NS_ :

BS_:

BU_: AWC BAP_Tester BMC_MLBevo BMS_MV BMS_NV DCDC_800V_PAG DCDC_HV DCDC_HV_02 DCDC_IHEV Gateway Gateway_PAG Ladegeraet_2 Ladegeraet_Konzern LE1 LE2 LE_MLBevo Sub_Gateway TME

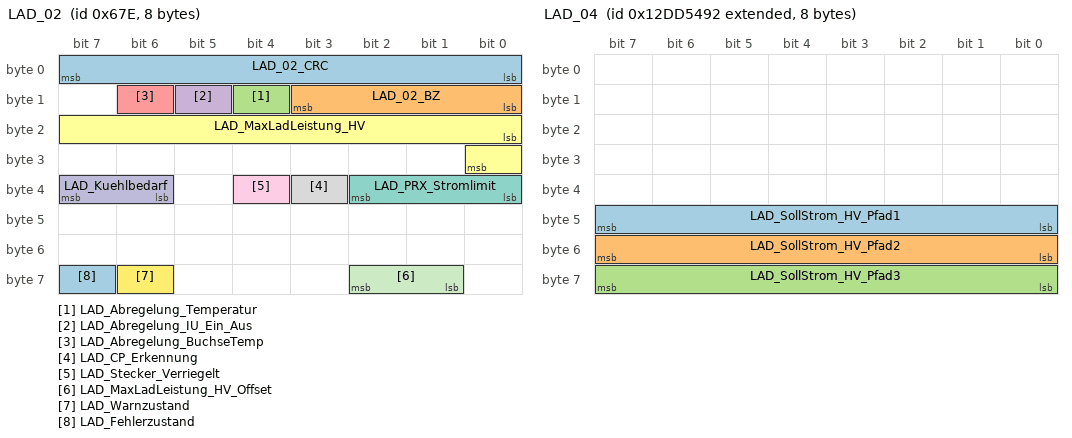
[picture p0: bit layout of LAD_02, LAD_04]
BO_ 1662 LAD_02: 8 Ladegeraet_Konzern
 SG_ LAD_02_CRC : 0|8@1+ (1,0) [0|255] ""  Gateway,Gateway_PAG
 SG_ LAD_02_BZ : 8|4@1+ (1,0) [0|15] ""  Gateway,Gateway_PAG
 SG_ LAD_Abregelung_Temperatur : 12|1@1+ (1.0,0.0) [0.0|1] ""  TME
 SG_ LAD_Abregelung_IU_Ein_Aus : 13|1@1+ (1.0,0.0) [0.0|1] ""  Vector__XXX
 SG_ LAD_Abregelung_BuchseTemp : 14|1@1+ (1.0,0.0) [0.0|1] ""  Vector__XXX
 SG_ LAD_MaxLadLeistung_HV : 16|9@1+ (100,0) [0|50900] "Unit_Watt"  TME
 SG_ LAD_PRX_Stromlimit : 32|3@1+ (1.0,0.0) [0.0|7] ""  Vector__XXX
 SG_ LAD_CP_Erkennung : 35|1@1+ (1.0,0.0) [0.0|1] ""  Vector__XXX
 SG_ LAD_Stecker_Verriegelt : 36|1@1+ (1.0,0.0) [0.0|1] ""  Vector__XXX
 SG_ LAD_Kuehlbedarf : 38|2@1+ (1.0,0.0) [0.0|3] ""  Vector__XXX
 SG_ LAD_MaxLadLeistung_HV_Offset : 57|2@1+ (1.0,0.0) [0.0|3] ""  Vector__XXX
 SG_ LAD_Warnzustand : 62|1@1+ (1.0,0.0) [0.0|1] ""  Vector__XXX
 SG_ LAD_Fehlerzustand : 63|1@1+ (1.0,0.0) [0.0|1] ""  Vector__XXX

BO_ 2463978642 LAD_04: 8 Ladegeraet_Konzern
 SG_ LAD_SollStrom_HV_Pfad1 : 40|8@1+ (0.1,0) [0.0|25.3] "Unit_Amper"  Ladegeraet_2
 SG_ LAD_SollStrom_HV_Pfad2 : 48|8@1+ (0.1,0) [0.0|25.3] "Unit_Amper"  Ladegeraet_2
 SG_ LAD_SollStrom_HV_Pfad3 : 56|8@1+ (0.1,0) [0.0|25.3] "Unit_Amper"  Ladegeraet_2

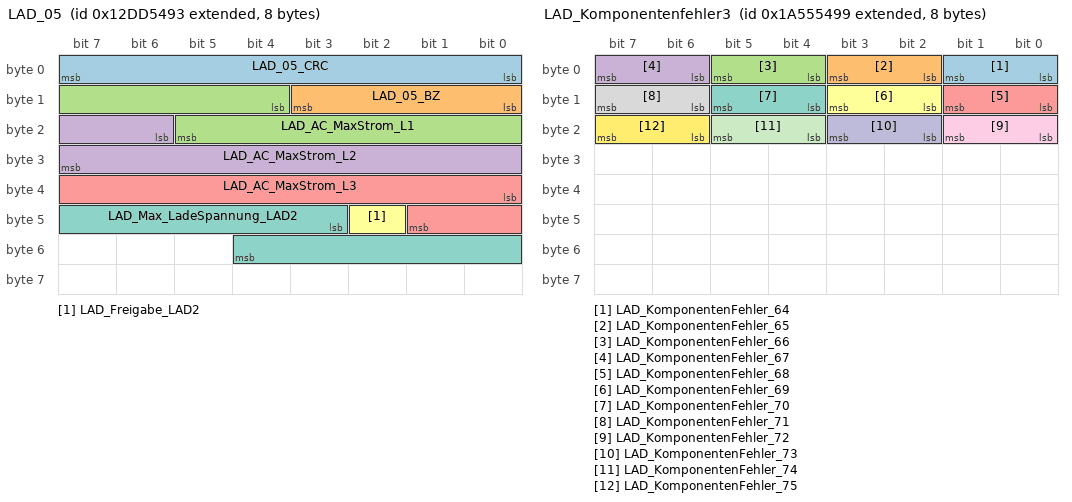
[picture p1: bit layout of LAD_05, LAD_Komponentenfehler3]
BO_ 2463978643 LAD_05: 8 Ladegeraet_Konzern
 SG_ LAD_05_CRC : 0|8@1+ (1,0) [0|255] ""  Ladegeraet_2
 SG_ LAD_05_BZ : 8|4@1+ (1,0) [0|15] ""  Ladegeraet_2
 SG_ LAD_AC_MaxStrom_L1 : 12|10@1+ (0.1,0) [0.0|102.1] "Unit_Amper"  Ladegeraet_2
 SG_ LAD_AC_MaxStrom_L2 : 22|10@1+ (0.1,0) [0.0|102.1] "Unit_Amper"  Ladegeraet_2
 SG_ LAD_AC_MaxStrom_L3 : 32|10@1+ (0.1,0) [0.0|102.1] "Unit_Amper"  Ladegeraet_2
 SG_ LAD_Freigabe_LAD2 : 42|1@1+ (1.0,0.0) [0.0|1] ""  Ladegeraet_2
 SG_ LAD_Max_LadeSpannung_LAD2 : 43|10@1+ (1,0) [0|1021] "Unit_Volt"  Ladegeraet_2

BO_ 2589283663 LAD_06: 8 Ladegeraet_Konzern
 SG_ LAD_PlanAntw_Verlustleistung : 48|12@1+ (50,0) [0|204650] "Unit_Watt"  TME
 SG_ LAD_PlanAntw_Zaehler : 60|4@1+ (1,0) [0|13] "Unit_None"  TME

BO_ 2589283415 LAD_CALID_CVN: 8 Ladegeraet_Konzern
 SG_ LAD_CALID_CVN_MUX M  : 0|2@1+ (1,0) [0|3] "Unit_None"  BMC_MLBevo
 SG_ LAD_CVN_VLD : 7|1@1+ (1.0,0.0) [0.0|1] ""  BMC_MLBevo
 SG_ LAD_CALID_Index_01 m0  : 8|8@1+ (1.0,0.0) [0.0|255] ""  BMC_MLBevo
 SG_ LAD_CALID_Index_05 m1  : 8|8@1+ (1.0,0.0) [0.0|255] ""  BMC_MLBevo
 SG_ LAD_CALID_Index_09 m2  : 8|8@1+ (1.0,0.0) [0.0|255] ""  BMC_MLBevo
 SG_ LAD_CALID_Index_13 m3  : 8|8@1+ (1.0,0.0) [0.0|255] ""  BMC_MLBevo
 SG_ LAD_CALID_Index_02 m0  : 16|8@1+ (1.0,0.0) [0.0|255] ""  BMC_MLBevo
 SG_ LAD_CALID_Index_06 m1  : 16|8@1+ (1.0,0.0) [0.0|255] ""  BMC_MLBevo
 SG_ LAD_CALID_Index_10 m2  : 16|8@1+ (1.0,0.0) [0.0|255] ""  BMC_MLBevo
 SG_ LAD_CALID_Index_14 m3  : 16|8@1+ (1.0,0.0) [0.0|255] ""  BMC_MLBevo
 SG_ LAD_CALID_Index_03 m0  : 24|8@1+ (1.0,0.0) [0.0|255] ""  BMC_MLBevo
 SG_ LAD_CALID_Index_07 m1  : 24|8@1+ (1.0,0.0) [0.0|255] ""  BMC_MLBevo
 SG_ LAD_CALID_Index_11 m2  : 24|8@1+ (1.0,0.0) [0.0|255] ""  BMC_MLBevo
 SG_ LAD_CALID_Index_15 m3  : 24|8@1+ (1.0,0.0) [0.0|255] ""  BMC_MLBevo
 SG_ LAD_CALID_Index_04 m0  : 32|8@1+ (1.0,0.0) [0.0|255] ""  BMC_MLBevo
 SG_ LAD_CALID_Index_08 m1  : 32|8@1+ (1.0,0.0) [0.0|255] ""  BMC_MLBevo
 SG_ LAD_CALID_Index_12 m2  : 32|8@1+ (1.0,0.0) [0.0|255] ""  BMC_MLBevo
 SG_ LAD_CALID_Index_16 m3  : 32|8@1+ (1.0,0.0) [0.0|255] ""  BMC_MLBevo
 SG_ LAD_CVN_Byte_1 m0  : 40|8@1+ (1.0,0.0) [0.0|255] ""  BMC_MLBevo
 SG_ LAD_CVN_Byte_2 m1  : 40|8@1+ (1.0,0.0) [0.0|255] ""  BMC_MLBevo
 SG_ LAD_CVN_Byte_3 m2  : 40|8@1+ (1.0,0.0) [0.0|255] ""  BMC_MLBevo
 SG_ LAD_CVN_Byte_4 m3  : 40|8@1+ (1.0,0.0) [0.0|255] ""  BMC_MLBevo

BO_ 2589283472 LAD_Komponentenfehler: 8 Ladegeraet_Konzern
 SG_ LAD_KomponentenFehler_01 : 0|2@1+ (1.0,0.0) [0.0|3] ""  BMC_MLBevo
 SG_ LAD_KomponentenFehler_02 : 2|2@1+ (1.0,0.0) [0.0|3] ""  BMC_MLBevo
 SG_ LAD_KomponentenFehler_03 : 4|2@1+ (1.0,0.0) [0.0|3] ""  BMC_MLBevo
 SG_ LAD_KomponentenFehler_04 : 6|2@1+ (1.0,0.0) [0.0|3] ""  BMC_MLBevo
 SG_ LAD_KomponentenFehler_05 : 8|2@1+ (1.0,0.0) [0.0|3] ""  BMC_MLBevo
 SG_ LAD_KomponentenFehler_06 : 10|2@1+ (1.0,0.0) [0.0|3] ""  BMC_MLBevo
 SG_ LAD_KomponentenFehler_07 : 12|2@1+ (1.0,0.0) [0.0|3] ""  BMC_MLBevo
 SG_ LAD_KomponentenFehler_08 : 14|2@1+ (1.0,0.0) [0.0|3] ""  BMC_MLBevo
 SG_ LAD_KomponentenFehler_09 : 16|2@1+ (1.0,0.0) [0.0|3] ""  BMC_MLBevo
 SG_ LAD_KomponentenFehler_10 : 18|2@1+ (1.0,0.0) [0.0|3] ""  BMC_MLBevo
 SG_ LAD_KomponentenFehler_11 : 20|2@1+ (1.0,0.0) [0.0|3] ""  BMC_MLBevo
 SG_ LAD_KomponentenFehler_12 : 22|2@1+ (1.0,0.0) [0.0|3] ""  BMC_MLBevo
 SG_ LAD_KomponentenFehler_13 : 24|2@1+ (1.0,0.0) [0.0|3] ""  BMC_MLBevo
 SG_ LAD_KomponentenFehler_14 : 26|2@1+ (1.0,0.0) [0.0|3] ""  BMC_MLBevo
 SG_ LAD_KomponentenFehler_15 : 28|2@1+ (1.0,0.0) [0.0|3] ""  BMC_MLBevo
 SG_ LAD_KomponentenFehler_16 : 30|2@1+ (1.0,0.0) [0.0|3] ""  BMC_MLBevo
 SG_ LAD_KomponentenFehler_17 : 32|2@1+ (1.0,0.0) [0.0|3] ""  BMC_MLBevo
 SG_ LAD_KomponentenFehler_18 : 34|2@1+ (1.0,0.0) [0.0|3] ""  BMC_MLBevo
 SG_ LAD_KomponentenFehler_19 : 36|2@1+ (1.0,0.0) [0.0|3] ""  BMC_MLBevo
 SG_ LAD_KomponentenFehler_20 : 38|2@1+ (1.0,0.0) [0.0|3] ""  BMC_MLBevo
 SG_ LAD_KomponentenFehler_21 : 40|2@1+ (1.0,0.0) [0.0|3] ""  BMC_MLBevo
 SG_ LAD_KomponentenFehler_22 : 42|2@1+ (1.0,0.0) [0.0|3] ""  BMC_MLBevo
 SG_ LAD_KomponentenFehler_23 : 44|2@1+ (1.0,0.0) [0.0|3] ""  BMC_MLBevo
 SG_ LAD_KomponentenFehler_24 : 46|2@1+ (1.0,0.0) [0.0|3] ""  BMC_MLBevo
 SG_ LAD_KomponentenFehler_25 : 48|2@1+ (1.0,0.0) [0.0|3] ""  BMC_MLBevo
 SG_ LAD_KomponentenFehler_26 : 50|2@1+ (1.0,0.0) [0.0|3] ""  BMC_MLBevo
 SG_ LAD_KomponentenFehler_27 : 52|2@1+ (1.0,0.0) [0.0|3] ""  BMC_MLBevo
 SG_ LAD_KomponentenFehler_28 : 54|2@1+ (1.0,0.0) [0.0|3] ""  BMC_MLBevo
 SG_ LAD_KomponentenFehler_29 : 56|2@1+ (1.0,0.0) [0.0|3] ""  BMC_MLBevo
 SG_ LAD_KomponentenFehler_30 : 58|2@1+ (1.0,0.0) [0.0|3] ""  BMC_MLBevo
 SG_ LAD_KomponentenFehler_31 : 60|2@1+ (1.0,0.0) [0.0|3] ""  BMC_MLBevo
 SG_ LAD_KomponentenFehler_32 : 62|2@1+ (1.0,0.0) [0.0|3] ""  BMC_MLBevo

BO_ 2589283473 LAD_Komponentenfehler2: 8 Ladegeraet_Konzern
 SG_ LAD_KomponentenFehler_33 : 0|2@1+ (1.0,0.0) [0.0|3] ""  BMC_MLBevo
 SG_ LAD_KomponentenFehler_34 : 2|2@1+ (1.0,0.0) [0.0|3] ""  BMC_MLBevo
 SG_ LAD_KomponentenFehler_35 : 4|2@1+ (1.0,0.0) [0.0|3] ""  BMC_MLBevo
 SG_ LAD_KomponentenFehler_36 : 6|2@1+ (1.0,0.0) [0.0|3] ""  BMC_MLBevo
 SG_ LAD_KomponentenFehler_37 : 8|2@1+ (1.0,0.0) [0.0|3] ""  BMC_MLBevo
 SG_ LAD_KomponentenFehler_38 : 10|2@1+ (1.0,0.0) [0.0|3] ""  BMC_MLBevo
 SG_ LAD_KomponentenFehler_39 : 12|2@1+ (1.0,0.0) [0.0|3] ""  BMC_MLBevo
 SG_ LAD_KomponentenFehler_40 : 14|2@1+ (1.0,0.0) [0.0|3] ""  BMC_MLBevo
 SG_ LAD_KomponentenFehler_41 : 16|2@1+ (1.0,0.0) [0.0|3] ""  BMC_MLBevo
 SG_ LAD_KomponentenFehler_42 : 18|2@1+ (1.0,0.0) [0.0|3] ""  BMC_MLBevo
 SG_ LAD_KomponentenFehler_43 : 20|2@1+ (1.0,0.0) [0.0|3] ""  BMC_MLBevo
 SG_ LAD_KomponentenFehler_44 : 22|2@1+ (1.0,0.0) [0.0|3] ""  BMC_MLBevo
 SG_ LAD_KomponentenFehler_45 : 24|2@1+ (1.0,0.0) [0.0|3] ""  BMC_MLBevo
 SG_ LAD_KomponentenFehler_46 : 26|2@1+ (1.0,0.0) [0.0|3] ""  BMC_MLBevo
 SG_ LAD_KomponentenFehler_47 : 28|2@1+ (1.0,0.0) [0.0|3] ""  BMC_MLBevo
 SG_ LAD_KomponentenFehler_48 : 30|2@1+ (1.0,0.0) [0.0|3] ""  BMC_MLBevo
 SG_ LAD_KomponentenFehler_49 : 32|2@1+ (1.0,0.0) [0.0|3] ""  BMC_MLBevo
 SG_ LAD_KomponentenFehler_50 : 34|2@1+ (1.0,0.0) [0.0|3] ""  BMC_MLBevo
 SG_ LAD_KomponentenFehler_51 : 36|2@1+ (1.0,0.0) [0.0|3] ""  BMC_MLBevo
 SG_ LAD_KomponentenFehler_52 : 38|2@1+ (1.0,0.0) [0.0|3] ""  BMC_MLBevo
 SG_ LAD_KomponentenFehler_53 : 40|2@1+ (1.0,0.0) [0.0|3] ""  BMC_MLBevo
 SG_ LAD_KomponentenFehler_54 : 42|2@1+ (1.0,0.0) [0.0|3] ""  BMC_MLBevo
 SG_ LAD_KomponentenFehler_55 : 44|2@1+ (1.0,0.0) [0.0|3] ""  BMC_MLBevo
 SG_ LAD_KomponentenFehler_56 : 46|2@1+ (1.0,0.0) [0.0|3] ""  BMC_MLBevo
 SG_ LAD_KomponentenFehler_57 : 48|2@1+ (1.0,0.0) [0.0|3] ""  BMC_MLBevo
 SG_ LAD_KomponentenFehler_58 : 50|2@1+ (1.0,0.0) [0.0|3] ""  BMC_MLBevo
 SG_ LAD_KomponentenFehler_59 : 52|2@1+ (1.0,0.0) [0.0|3] ""  BMC_MLBevo
 SG_ LAD_KomponentenFehler_60 : 54|2@1+ (1.0,0.0) [0.0|3] ""  BMC_MLBevo
 SG_ LAD_KomponentenFehler_61 : 56|2@1+ (1.0,0.0) [0.0|3] ""  BMC_MLBevo
 SG_ LAD_KomponentenFehler_62 : 58|2@1+ (1.0,0.0) [0.0|3] ""  BMC_MLBevo
 SG_ LAD_KomponentenFehler_63 : 60|2@1+ (1.0,0.0) [0.0|3] ""  BMC_MLBevo
 SG_ LAD_Komponentenfehler_VLD : 63|1@1+ (1.0,0.0) [0.0|1] ""  BMC_MLBevo

BO_ 2589283481 LAD_Komponentenfehler3: 8 Ladegeraet_Konzern
 SG_ LAD_KomponentenFehler_64 : 0|2@1+ (1.0,0.0) [0.0|3] ""  BMC_MLBevo
 SG_ LAD_KomponentenFehler_65 : 2|2@1+ (1.0,0.0) [0.0|3] ""  BMC_MLBevo
 SG_ LAD_KomponentenFehler_66 : 4|2@1+ (1.0,0.0) [0.0|3] ""  BMC_MLBevo
 SG_ LAD_KomponentenFehler_67 : 6|2@1+ (1.0,0.0) [0.0|3] ""  BMC_MLBevo
 SG_ LAD_KomponentenFehler_68 : 8|2@1+ (1.0,0.0) [0.0|3] ""  BMC_MLBevo
 SG_ LAD_KomponentenFehler_69 : 10|2@1+ (1.0,0.0) [0.0|3] ""  BMC_MLBevo
 SG_ LAD_KomponentenFehler_70 : 12|2@1+ (1.0,0.0) [0.0|3] ""  BMC_MLBevo
 SG_ LAD_KomponentenFehler_71 : 14|2@1+ (1.0,0.0) [0.0|3] ""  BMC_MLBevo
 SG_ LAD_KomponentenFehler_72 : 16|2@1+ (1.0,0.0) [0.0|3] ""  BMC_MLBevo
 SG_ LAD_KomponentenFehler_73 : 18|2@1+ (1.0,0.0) [0.0|3] ""  BMC_MLBevo
 SG_ LAD_KomponentenFehler_74 : 20|2@1+ (1.0,0.0) [0.0|3] ""  BMC_MLBevo
 SG_ LAD_KomponentenFehler_75 : 22|2@1+ (1.0,0.0) [0.0|3] ""  BMC_MLBevo

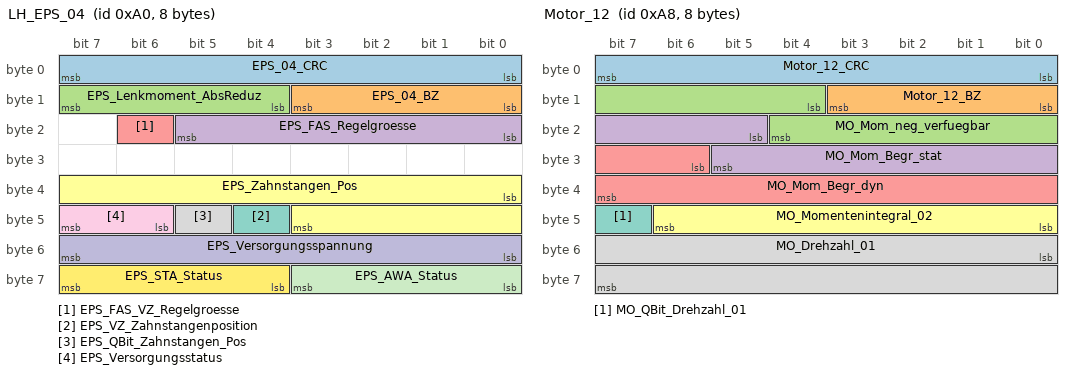
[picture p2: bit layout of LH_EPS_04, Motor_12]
BO_ 160 LH_EPS_04: 8 Gateway
 SG_ EPS_04_CRC : 0|8@1+ (1,0) [0|255] ""  Vector__XXX
 SG_ EPS_04_BZ : 8|4@1+ (1,0) [0|15] ""  Vector__XXX
 SG_ EPS_Lenkmoment_AbsReduz : 12|4@1+ (0.62,0.61) [0.61|8.05] "Unit_NewtoMeter"  Vector__XXX
 SG_ EPS_FAS_Regelgroesse : 16|6@1+ (2,0) [0|100] "Unit_PerCent"  Vector__XXX
 SG_ EPS_FAS_VZ_Regelgroesse : 22|1@1+ (1.0,0.0) [0.0|1] ""  Vector__XXX
 SG_ EPS_Zahnstangen_Pos : 32|12@1+ (0.02,0) [0.00|81.86] "Unit_MilliMeter"  AWC
 SG_ EPS_VZ_Zahnstangenposition : 44|1@1+ (1.0,0.0) [0.0|1] ""  AWC
 SG_ EPS_QBit_Zahnstangen_Pos : 45|1@1+ (1.0,0.0) [0.0|1] ""  AWC
 SG_ EPS_Versorgungsstatus : 46|2@1+ (1.0,0.0) [0.0|3] ""  Vector__XXX
 SG_ EPS_Versorgungsspannung : 48|8@1+ (0.05,5.05) [5.05|17.70] "Unit_Volt"  Vector__XXX
 SG_ EPS_AWA_Status : 56|4@1+ (1.0,0.0) [0.0|15] ""  Vector__XXX
 SG_ EPS_STA_Status : 60|4@1+ (1.0,0.0) [0.0|15] ""  Vector__XXX

BO_ 1600 Motor_07: 8 Gateway
 SG_ MO_QBit_Ansaugluft_Temp : 0|1@1+ (1.0,0.0) [0.0|1] ""  Vector__XXX
 SG_ MO_QBit_Oel_Temp : 1|1@1+ (1.0,0.0) [0.0|1] ""  Vector__XXX
 SG_ MO_QBit_Kuehlmittel_Temp : 2|1@1+ (1.0,0.0) [0.0|1] ""  Vector__XXX
 SG_ MO_KL15_Abschaltempfehlung : 3|1@1+ (1.0,0.0) [0.0|1] ""  Vector__XXX
 SG_ MO_HYB_Fehler_HV_Netz : 4|1@1+ (1.0,0.0) [0.0|1] ""  Vector__XXX
 SG_ MO_aktives_Getriebeheizen : 5|1@1+ (1.0,0.0) [0.0|1] ""  Vector__XXX
 SG_ MO_Absperrventil_oeffnen : 6|2@1+ (1.0,0.0) [0.0|3] ""  TME
 SG_ MO_Ansaugluft_Temp : 8|8@1+ (0.75,-48) [-48.00|141.75] "Unit_DegreCelsi"  TME
 SG_ MO_Oel_Temp : 16|8@1+ (1,-60) [-60|192] "Unit_DegreCelsi"  TME
 SG_ MO_Kuehlmittel_Temp : 24|8@1+ (0.75,-48) [-48.00|141.75] "Unit_DegreCelsi"  TME
 SG_ MO_Hoeheninfo : 32|8@1+ (0.00781,0) [0.00000|1.98374] ""  TME
 SG_ MO_Kennfeldk : 40|1@1+ (1.0,0.0) [0.0|1] ""  TME
 SG_ MO_Versionsinfo_02 : 41|5@1+ (1.0,0.0) [0.0|31] ""  Vector__XXX
 SG_ MO_QBit_Hoeheninfo : 46|1@1+ (1.0,0.0) [0.0|1] ""  Vector__XXX
 SG_ MO_Getriebe_kuehlen : 47|1@1+ (1.0,0.0) [0.0|1] ""  Vector__XXX
 SG_ MO_Mom_Traegheit_02 : 48|5@1+ (0.01,0) [0.00|0.31] "Unit_KiloGramMeterSquar"  Vector__XXX
 SG_ MO_Heizungspumpenansteuerung : 53|4@1+ (10,0) [0|100] "Unit_PerCent"  TME
 SG_ MO_SpannungsAnf : 57|1@1+ (1.0,0.0) [0.0|1] ""  Vector__XXX
 SG_ MO_Nachlaufzeit_Heizungspumpe : 58|6@1+ (15,0) [0|945] "Unit_Secon"  TME

BO_ 1607 Motor_09: 8 Gateway
 SG_ MO_ITM_Kuehlmittel_Temp : 0|8@1+ (0.75,-48) [-45.75|143.25] "Unit_DegreCelsi"  TME
 SG_ MO_E85_Sensor : 8|4@1+ (10,0) [0|100] "Unit_PerCent"  Vector__XXX
 SG_ SCR_Anz_Motorstarts : 12|4@1+ (1.0,0.0) [0.0|15] ""  Vector__XXX
 SG_ SCR_Reichweite : 16|15@1+ (1,0) [0|32766] "Unit_KiloMeter"  Vector__XXX
 SG_ MO_Ethanol_Spuelhinweis : 31|1@1+ (1.0,0.0) [0.0|1] ""  Vector__XXX
 SG_ SCR_Warnstufe_1 : 32|1@1+ (1.0,0.0) [0.0|1] ""  Vector__XXX
 SG_ SCR_Warnstufe_2 : 33|1@1+ (1.0,0.0) [0.0|1] ""  Vector__XXX
 SG_ SCR_Text : 34|3@1+ (1.0,0.0) [0.0|7] ""  Vector__XXX
 SG_ SCR_Akustik : 37|2@1+ (1.0,0.0) [0.0|3] ""  Vector__XXX
 SG_ SCR_verbaut : 39|1@1+ (1.0,0.0) [0.0|1] ""  Vector__XXX
 SG_ MO_Kraftstofffilter_Wasser : 40|1@1+ (1.0,0.0) [0.0|1] ""  Vector__XXX
 SG_ SCR_Systemfehler : 41|1@1+ (1.0,0.0) [0.0|1] ""  Vector__XXX
 SG_ SCR_Inducement_Strategie : 42|2@1+ (1.0,0.0) [0.0|3] ""  Vector__XXX
 SG_ MO_CO2_Faktor : 44|12@1+ (1,0) [1|4094] "Unit_GramPerLiter"  Vector__XXX
 SG_ MO_MKB_MUX M  : 56|2@1+ (1.0,0.0) [0.0|3] ""  Vector__XXX
 SG_ MO_MKB_01 m0  : 59|5@1+ (1.0,0.0) [0.0|31] ""  Vector__XXX
 SG_ MO_MKB_02 m1  : 59|5@1+ (1.0,0.0) [0.0|31] ""  Vector__XXX
 SG_ MO_MKB_03 m2  : 59|5@1+ (1.0,0.0) [0.0|31] ""  Vector__XXX
 SG_ MO_MKB_04 m3  : 59|5@1+ (1.0,0.0) [0.0|31] ""  Vector__XXX

BO_ 168 Motor_12: 8 Gateway
 SG_ Motor_12_CRC : 0|8@1+ (1,0) [0|255] ""  Vector__XXX
 SG_ Motor_12_BZ : 8|4@1+ (1,0) [0|15] ""  Vector__XXX
 SG_ MO_Mom_neg_verfuegbar : 12|9@1+ (1,-509) [-509|0] ""  Vector__XXX
 SG_ MO_Mom_Begr_stat : 21|9@1+ (1,0) [0|509] ""  Vector__XXX
 SG_ MO_Mom_Begr_dyn : 30|10@1+ (1,-509) [-509|509] ""  Vector__XXX
 SG_ MO_Momentenintegral_02 : 40|7@1+ (1,0) [0|100] "Unit_PerCent"  Vector__XXX
 SG_ MO_QBit_Drehzahl_01 : 47|1@1+ (1.0,0.0) [0.0|1] ""  AWC
 SG_ MO_Drehzahl_01 : 48|16@1+ (0.25,0) [0.00|16383.00] "Unit_MinutInver"  AWC,BMC_MLBevo,DCDC_800V_PAG,DCDC_HV,Ladegeraet_2,Ladegeraet_Konzern,TME

BO_ 958 Motor_14: 8 Gateway
 SG_ Motor_14_CRC : 0|8@1+ (1,0) [0|255] ""  Vector__XXX
 SG_ Motor_14_BZ : 8|4@1+ (1,0) [0|15] ""  Vector__XXX
 SG_ MO_StartStopp_Status : 12|2@1+ (1.0,0.0) [0.0|3] ""  TME
 SG_ MO_StartStopp_Wiederstart : 14|1@1+ (1.0,0.0) [0.0|1] ""  BMS_NV,TME
 SG_ MO_StartStopp_Motorstopp : 15|1@1+ (1.0,0.0) [0.0|1] ""  BMS_NV,TME
 SG_ MO_Freig_Reku : 16|2@1+ (1.0,0.0) [0.0|3] ""  Vector__XXX
 SG_ MO_Kl_75 : 18|1@1+ (1.0,0.0) [0.0|1] ""  TME
 SG_ MO_Kl_50 : 19|1@1+ (1.0,0.0) [0.0|1] ""  DCDC_IHEV,Ladegeraet_Konzern
 SG_ MO_Gangposition : 20|4@1+ (1.0,0.0) [0.0|15] ""  TME
 SG_ MO_StartStopp_Fahrerwunsch : 24|2@1+ (1.0,0.0) [0.0|3] ""  TME
 SG_ MO_HYB_Fahrbereitschaft : 26|1@1+ (1.0,0.0) [0.0|1] ""  AWC,BMS_NV,Ladegeraet_Konzern,TME
 SG_ MO_Ext_E_Fahrt_aktiv : 27|1@1+ (1.0,0.0) [0.0|1] ""  TME
 SG_ MO_Fahrer_bremst : 28|1@1+ (1.0,0.0) [0.0|1] ""  Vector__XXX
 SG_ MO_QBit_Fahrer_bremst : 29|1@1+ (1.0,0.0) [0.0|1] ""  Vector__XXX
 SG_ MO_BLS : 30|1@1+ (1.0,0.0) [0.0|1] ""  Vector__XXX
 SG_ MO_Konsistenz_Bremsped : 31|1@1+ (1.0,0.0) [0.0|1] ""  Vector__XXX
 SG_ MO_KomFehler_ESP : 32|1@1+ (1.0,0.0) [0.0|1] ""  Vector__XXX
 SG_ MO_Klima_Eingr : 33|2@1+ (1.0,0.0) [0.0|3] ""  TME
 SG_ MO_Aussp_Anlass : 35|1@1+ (1.0,0.0) [0.0|1] ""  Vector__XXX
 SG_ MO_Freig_Anlass : 36|1@1+ (1.0,0.0) [0.0|1] ""  Vector__XXX
 SG_ MO_Kuppl_schalter : 37|1@1+ (1.0,0.0) [0.0|1] ""  Vector__XXX
 SG_ MO_Interlock : 38|1@1+ (1.0,0.0) [0.0|1] ""  Vector__XXX
 SG_ MO_Motor_laeuft : 39|1@1+ (1.0,0.0) [0.0|1] ""  TME
 SG_ MO_Kickdown : 40|1@1+ (1.0,0.0) [0.0|1] ""  TME
 SG_ MO_QBit_KL_75 : 41|1@1+ (1.0,0.0) [0.0|1] ""  Vector__XXX
 SG_ MO_EKlKomLeiRed : 42|2@1+ (1.0,0.0) [0.0|3] ""  Vector__XXX
 SG_ MO_Handshake_STH : 44|1@1+ (1.0,0.0) [0.0|1] ""  Vector__XXX
 SG_ MO_BKV_Unterdruckwarnung : 45|1@1+ (1.0,0.0) [0.0|1] ""  Vector__XXX
 SG_ MO_Freigabe_Segeln : 46|1@1+ (1.0,0.0) [0.0|1] ""  Vector__XXX
 SG_ MO_PTC_Status : 47|3@1+ (1.0,0.0) [0.0|7] ""  Vector__XXX
 SG_ MO_QBit_Gangposition : 50|1@1+ (1.0,0.0) [0.0|1] ""  Vector__XXX
 SG_ MO_Signalquelle_Gangposition : 51|1@1+ (1.0,0.0) [0.0|1] ""  Vector__XXX
 SG_ MO_Remotestart_Betrieb : 52|1@1+ (1.0,0.0) [0.0|1] ""  Vector__XXX
 SG_ MO_Remotestart_moeglich : 53|1@1+ (1.0,0.0) [0.0|1] ""  Vector__XXX
 SG_ MO_FMAus_aktiv : 55|1@1+ (1.0,0.0) [0.0|1] ""  BMS_NV
 SG_ MO_FMAus_Startvariante : 56|2@1+ (1.0,0.0) [0.0|3] ""  Vector__XXX
 SG_ MO_BMS_NV_Anf_stuetzen : 58|1@1+ (1.0,0.0) [0.0|1] ""  Vector__XXX
 SG_ MO_Zylinderabschaltung : 59|2@1+ (1.0,0.0) [0.0|3] ""  Vector__XXX
 SG_ MO_HYB_VM_aktiv : 61|1@1+ (1.0,0.0) [0.0|1] ""  Vector__XXX
 SG_ MO_StartVorauss_erfuellt : 62|2@1+ (1.0,0.0) [0.0|3] ""  AWC,Ladegeraet_Konzern

BO_ 812 Motor_17: 8 Gateway
 SG_ MO_Sperrung_FahrPr_BZS : 0|8@1+ (1.0,0.0) [0.0|255] ""  Vector__XXX
 SG_ MO_Rampenzeit_Generator_Anf : 8|4@1+ (1.0,0.0) [0.0|15] ""  Vector__XXX
 SG_ MO_Prio_MAX_Wunschdrehzahl : 12|1@1+ (1.0,0.0) [0.0|1] ""  Vector__XXX
 SG_ MO_Prio_MIN_Wunschdrehzahl : 13|1@1+ (1.0,0.0) [0.0|1] ""  Vector__XXX
 SG_ MO_Luftpfad_aktiv : 14|1@1+ (1.0,0.0) [0.0|1] ""  Vector__XXX
 SG_ MO_v_Begrenz_Aktivierbar : 15|1@1+ (1.0,0.0) [0.0|1] ""  Vector__XXX
 SG_ MO_Drehzahlbeeinflussung : 16|8@1+ (0.39,0) [0.00|99.45] "Unit_PerCent"  Vector__XXX
 SG_ MO_MIN_Wunschdrehzahl : 24|8@1+ (25,0) [0|6350] "Unit_MinutInver"  Vector__XXX
 SG_ MO_MAX_Wunschdrehzahl : 32|9@1+ (25,0) [0|12750] "Unit_MinutInver"  Vector__XXX
 SG_ MO_Charisma_FahrPr : 41|4@1+ (1.0,0.0) [0.0|15] ""  TME
 SG_ MO_Charisma_Status : 45|2@1+ (1.0,0.0) [0.0|3] ""  Vector__XXX
 SG_ MO_StSt_Charisma_FahrPr : 47|4@1+ (1.0,0.0) [0.0|15] ""  Vector__XXX
 SG_ MO_StSt_Charisma_Status : 51|2@1+ (1.0,0.0) [0.0|3] ""  Vector__XXX
 SG_ MO_BZS_Charisma_FahrPr : 53|4@1+ (1.0,0.0) [0.0|15] ""  TME
 SG_ MO_BZS_Charisma_Status : 57|2@1+ (1.0,0.0) [0.0|3] ""  Vector__XXX
 SG_ MO_NGS_Position : 59|1@1+ (1.0,0.0) [0.0|1] ""  Vector__XXX
 SG_ MO_NGS_Status : 60|2@1+ (1.0,0.0) [0.0|3] ""  Vector__XXX
 SG_ MO_v_Begrenzung_Niveau : 62|2@1+ (1.0,0.0) [0.0|3] ""  Vector__XXX

BO_ 1648 Motor_18: 8 Gateway
 SG_ MO_max_Ladedruck : 0|6@1+ (0.1,0) [0.0|6.3] "Unit_Bar"  Vector__XXX
 SG_ MO_ANC_Kennfeld_Anf : 6|2@1+ (1.0,0.0) [0.0|3] ""  Vector__XXX
 SG_ MO_Bremslicht_Reku : 8|1@1+ (1.0,0.0) [0.0|1] ""  Vector__XXX
 SG_ MO_StartStopp_PopUp : 9|2@1+ (1.0,0.0) [0.0|3] ""  Vector__XXX
 SG_ MO1_Sperr_Info_WFS : 11|1@1+ (1.0,0.0) [0.0|1] ""  Vector__XXX
 SG_ MO1_Freigabe_Info_WFS : 12|1@1+ (1.0,0.0) [0.0|1] ""  Vector__XXX
 SG_ MO_EPCL : 13|3@1+ (1.0,0.0) [0.0|7] ""  Vector__XXX
 SG_ MO_Zylabsch_Texte_02 : 16|4@1+ (1.0,0.0) [0.0|15] ""  Vector__XXX
 SG_ MO_Fahrzeugtyp : 20|3@1+ (1.0,0.0) [0.0|7] ""  BMS_NV
 SG_ MO_NMAX_Schaltanzeige : 23|9@1+ (25,0) [0|12775] "Unit_MinutInver"  Vector__XXX
 SG_ MO_Abstellzeit : 32|8@1+ (8,0) [0|2024] "Unit_Minut"  BMS_MV,BMS_NV,TME
 SG_ MO_Abstellzeit_Status : 40|2@1+ (1.0,0.0) [0.0|3] ""  BMS_MV,BMS_NV,TME
 SG_ MO1_Freigabe_Verfallsinfo_WFS : 42|1@1+ (1.0,0.0) [0.0|1] ""  Vector__XXX
 SG_ MO_Hybrid_StartStopp_LED : 43|2@1+ (1.0,0.0) [0.0|3] ""  Vector__XXX
 SG_ MO_Fehler_Zylabsch : 45|2@1+ (1.0,0.0) [0.0|3] ""  Vector__XXX
 SG_ MO_Anzahl_Abgesch_Zyl : 47|3@1+ (1.0,0.0) [0.0|7] ""  Vector__XXX
 SG_ MO_Zylabsch_Texte : 50|2@1+ (1.0,0.0) [0.0|3] ""  Vector__XXX
 SG_ MO_Ethanol_BS_Texte : 52|3@1+ (1.0,0.0) [0.0|7] ""  Vector__XXX
 SG_ MO_Drehzahl_Warnung : 55|1@1+ (1.0,0.0) [0.0|1] ""  Vector__XXX
 SG_ MO_obere_Drehzahlgrenze : 56|8@1+ (50,0) [50|12750] "Unit_MinutInver"  Vector__XXX

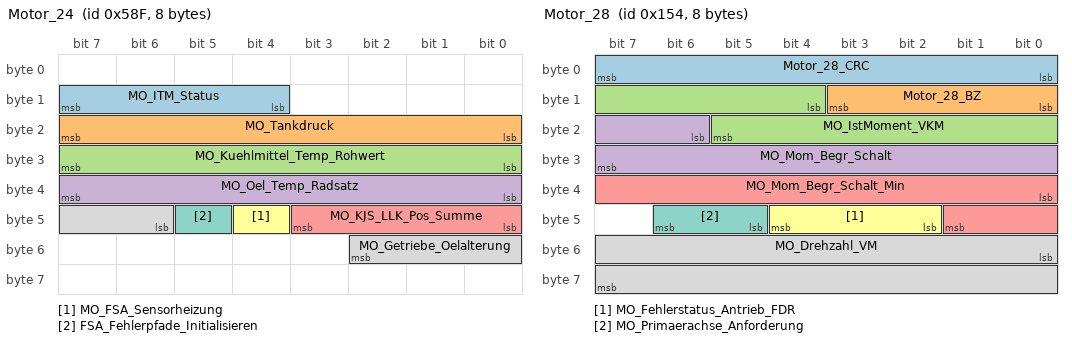
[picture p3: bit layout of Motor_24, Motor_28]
BO_ 1423 Motor_24: 8 Gateway
 SG_ MO_ITM_Status : 12|4@1+ (1.0,0.0) [0.0|15] ""  TME
 SG_ MO_Tankdruck : 16|8@1+ (2,-250) [-250|256] "Unit_MilliBar"  Vector__XXX
 SG_ MO_Kuehlmittel_Temp_Rohwert : 24|8@1+ (0.75,-48) [-48.00|141.75] "Unit_DegreCelsi"  TME
 SG_ MO_Oel_Temp_Radsatz : 32|8@1+ (1,-60) [-60|193] "Unit_DegreCelsi"  Vector__XXX
 SG_ MO_KJS_LLK_Pos_Summe : 40|4@1+ (10,0) [0|100] "Unit_PerCent"  Vector__XXX
 SG_ MO_FSA_Sensorheizung : 44|1@1+ (1.0,0.0) [0.0|1] ""  Vector__XXX
 SG_ FSA_Fehlerpfade_Initialisieren : 45|1@1+ (1.0,0.0) [0.0|1] ""  Vector__XXX
 SG_ MO_Getriebe_Oelalterung : 46|5@1+ (5,0) [0|100] "Unit_PerCent"  Vector__XXX

BO_ 967 Motor_26: 8 Gateway
 SG_ MO_Kuehlerluefter_MUX M  : 0|1@1+ (1.0,0.0) [0.0|1] ""  TME
 SG_ MO_Kuehlerluefter_1 m0  : 1|7@1+ (1,0) [0|100] "Unit_PerCent"  TME
 SG_ MO_Kuehlerluefter_2 m1  : 1|7@1+ (1,0) [0|100] "Unit_PerCent"  TME
 SG_ MO_EFLEX_Lampe : 8|2@1+ (1.0,0.0) [0.0|3] ""  Vector__XXX
 SG_ MO_KJS_nicht_bereit : 10|1@1+ (1.0,0.0) [0.0|1] ""  Vector__XXX
 SG_ MO_ITM_Warnung_Pumpe : 11|1@1+ (1.0,0.0) [0.0|1] ""  Vector__XXX
 SG_ WIV_Anzeige_aktiv : 12|1@1+ (1.0,0.0) [0.0|1] ""  Vector__XXX
 SG_ WIV_Oelmin_Warn : 13|1@1+ (1.0,0.0) [0.0|1] ""  Vector__XXX
 SG_ WIV_Sensorfehler : 14|1@1+ (1.0,0.0) [0.0|1] ""  Vector__XXX
 SG_ WIV_Schieflage : 15|1@1+ (1.0,0.0) [0.0|1] ""  Vector__XXX
 SG_ WIV_Oelstand : 16|4@1+ (12.5,0) [0.0|100.0] "Unit_PerCent"  Vector__XXX
 SG_ MO_Zustand_HWP : 20|2@1+ (1.0,0.0) [0.0|3] ""  TME
 SG_ OLEV_Systemstoerung : 22|1@1+ (1.0,0.0) [0.0|1] ""  Vector__XXX
 SG_ MO_Oelwarnung_max : 23|1@1+ (1.0,0.0) [0.0|1] ""  Vector__XXX
 SG_ WIV_Oelsystem_aktiv : 24|1@1+ (1.0,0.0) [0.0|1] ""  Vector__XXX
 SG_ WIV_nicht_betriebswarm : 25|1@1+ (1.0,0.0) [0.0|1] ""  Vector__XXX
 SG_ WIV_Ueberfuell_Warn : 26|1@1+ (1.0,0.0) [0.0|1] ""  Vector__XXX
 SG_ WIV_laufender_Motor : 27|1@1+ (1.0,0.0) [0.0|1] ""  Vector__XXX
 SG_ MO_E_Warnungen : 28|4@1+ (1.0,0.0) [0.0|15] ""  Vector__XXX
 SG_ MO_Text_Motorstart : 32|4@1+ (1.0,0.0) [0.0|15] ""  Vector__XXX
 SG_ MO_E_Texte : 36|4@1+ (1.0,0.0) [0.0|15] ""  Vector__XXX
 SG_ WIV_Oeldyn_avl : 40|1@1+ (1.0,0.0) [0.0|1] ""  Vector__XXX
 SG_ MO_Text_Partikelfil_Reg : 41|1@1+ (1,0) [0|1] ""  Vector__XXX
 SG_ OLEV_Oelstand_nicht_vorhanden : 42|1@1+ (1.0,0.0) [0.0|1] ""  Vector__XXX
 SG_ WIV_Oelmenge : 43|5@1+ (125,0) [0|3875] "Unit_MilliLiter"  Vector__XXX
 SG_ MO_Systemlampe : 48|1@1+ (1.0,0.0) [0.0|1] ""  Vector__XXX
 SG_ MO_OBD2_Lampe : 49|1@1+ (1.0,0.0) [0.0|1] ""  Vector__XXX
 SG_ MO_Heissleuchte : 50|1@1+ (1.0,0.0) [0.0|1] ""  TME
 SG_ MO_Partikel_Lampe : 51|1@1+ (1.0,0.0) [0.0|1] ""  Vector__XXX
 SG_ MO_RedFahrleistung_Lampe : 52|1@1+ (1.0,0.0) [0.0|1] ""  Vector__XXX
 SG_ WIV_Oelstand_nicht_vorhanden : 53|1@1+ (1.0,0.0) [0.0|1] ""  Vector__XXX
 SG_ WIV_nachfuellanzeige_ein : 54|1@1+ (1.0,0.0) [0.0|1] ""  Vector__XXX
 SG_ WIV_Ueberfuell_deaktiv : 55|1@1+ (1.0,0.0) [0.0|1] ""  Vector__XXX
 SG_ WIV_Unterfuell_Warn : 56|1@1+ (1.0,0.0) [0.0|1] ""  Vector__XXX
 SG_ MO_Tankdeckel_Lampe : 57|1@1+ (1.0,0.0) [0.0|1] ""  Vector__XXX
 SG_ MO_Text_Tankdeckelwarn : 58|1@1+ (1.0,0.0) [0.0|1] ""  Vector__XXX
 SG_ MO_Vorglueh_Lampe : 59|1@1+ (1.0,0.0) [0.0|1] ""  Vector__XXX
 SG_ WIV_Oeldr_Warn_Motor : 60|1@1+ (1.0,0.0) [0.0|1] ""  Vector__XXX
 SG_ MO_E_Mode : 61|3@1+ (1.0,0.0) [0.0|7] ""  Vector__XXX

BO_ 340 Motor_28: 8 Gateway
 SG_ Motor_28_CRC : 0|8@1+ (1,0) [0|255] ""  Vector__XXX
 SG_ Motor_28_BZ : 8|4@1+ (1,0) [0|15] ""  Vector__XXX
 SG_ MO_IstMoment_VKM : 12|10@1+ (1,-509) [-509|509] ""  Vector__XXX
 SG_ MO_Mom_Begr_Schalt : 22|10@1+ (1,-509) [-509|509] ""  Vector__XXX
 SG_ MO_Mom_Begr_Schalt_Min : 32|10@1+ (1,-509) [-509|509] ""  Vector__XXX
 SG_ MO_Fehlerstatus_Antrieb_FDR : 42|3@1+ (1.0,0.0) [0.0|7] ""  Vector__XXX
 SG_ MO_Primaerachse_Anforderung : 45|2@1+ (1.0,0.0) [0.0|3] ""  Vector__XXX
 SG_ MO_Drehzahl_VM : 48|16@1+ (0.25,0) [0.00|16383.00] "Unit_MinutInver"  BMC_MLBevo,BMS_MV,BMS_NV,DCDC_IHEV,TME

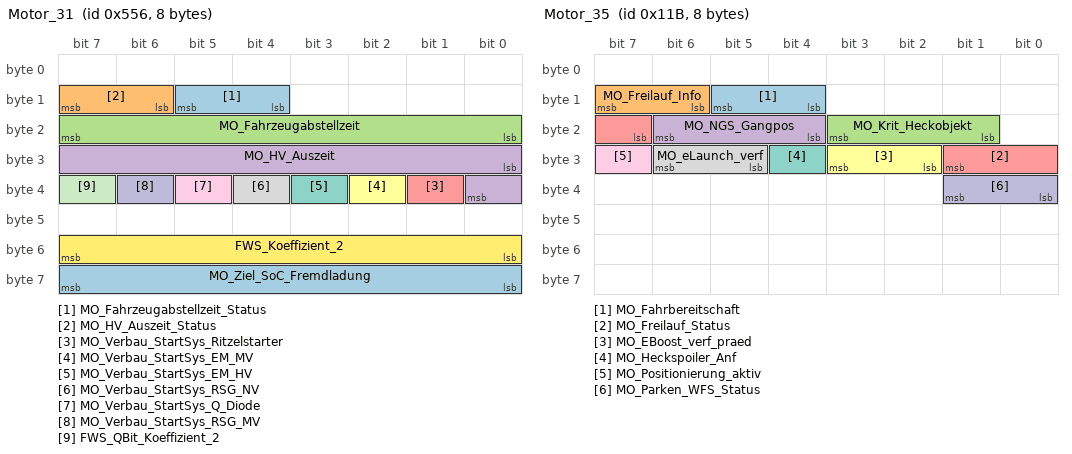
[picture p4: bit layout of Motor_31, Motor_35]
BO_ 1366 Motor_31: 8 Gateway
 SG_ MO_Fahrzeugabstellzeit_Status : 12|2@1+ (1.0,0.0) [0.0|3] ""  BMC_MLBevo,TME
 SG_ MO_HV_Auszeit_Status : 14|2@1+ (1.0,0.0) [0.0|3] ""  BMC_MLBevo,DCDC_HV,Ladegeraet_Konzern,TME
 SG_ MO_Fahrzeugabstellzeit : 16|8@1+ (8,0) [0|2024] "Unit_Minut"  BMC_MLBevo,TME
 SG_ MO_HV_Auszeit : 24|9@1+ (4,0) [0|2036] "Unit_Minut"  BMC_MLBevo,DCDC_HV,Ladegeraet_Konzern,TME
 SG_ MO_Verbau_StartSys_Ritzelstarter : 33|1@1+ (1.0,0.0) [0.0|1] ""  BMS_NV
 SG_ MO_Verbau_StartSys_EM_MV : 34|1@1+ (1.0,0.0) [0.0|1] ""  BMS_NV
 SG_ MO_Verbau_StartSys_EM_HV : 35|1@1+ (1.0,0.0) [0.0|1] ""  BMS_NV
 SG_ MO_Verbau_StartSys_RSG_NV : 36|1@1+ (1.0,0.0) [0.0|1] ""  BMS_NV
 SG_ MO_Verbau_StartSys_Q_Diode : 37|1@1+ (1.0,0.0) [0.0|1] ""  BMS_NV
 SG_ MO_Verbau_StartSys_RSG_MV : 38|1@1+ (1.0,0.0) [0.0|1] ""  BMS_NV
 SG_ FWS_QBit_Koeffizient_2 : 39|1@1+ (1.0,0.0) [0.0|1] ""  Vector__XXX
 SG_ FWS_Koeffizient_2 : 48|8@1+ (0.002,0) [0.000|0.506] "Unit_NewtonPer_Kmh_Squar"  Vector__XXX
 SG_ MO_Ziel_SoC_Fremdladung : 56|8@1+ (0.4,0) [0.0|100.0] "Unit_PerCent"  Vector__XXX

BO_ 283 Motor_35: 8 Gateway
 SG_ MO_Fahrbereitschaft : 12|2@1+ (1.0,0.0) [0.0|3] ""  Vector__XXX
 SG_ MO_Freilauf_Info : 14|2@1+ (1.0,0.0) [0.0|3] ""  Vector__XXX
 SG_ MO_Krit_Heckobjekt : 17|3@1+ (1.0,0.0) [0.0|7] ""  Vector__XXX
 SG_ MO_NGS_Gangpos : 20|3@1+ (1.0,0.0) [0.0|7] ""  Vector__XXX
 SG_ MO_Freilauf_Status : 23|3@1+ (1.0,0.0) [0.0|7] ""  BMS_NV
 SG_ MO_EBoost_verf_praed : 26|2@1+ (1.0,0.0) [0.0|3] ""  Vector__XXX
 SG_ MO_Heckspoiler_Anf : 28|1@1+ (1.0,0.0) [0.0|1] ""  Vector__XXX
 SG_ MO_eLaunch_verf : 29|2@1+ (1.0,0.0) [0.0|3] ""  Vector__XXX
 SG_ MO_Positionierung_aktiv : 31|1@1+ (1.0,0.0) [0.0|1] ""  Vector__XXX
 SG_ MO_Parken_WFS_Status : 32|2@1+ (1.0,0.0) [0.0|3] ""  Vector__XXX

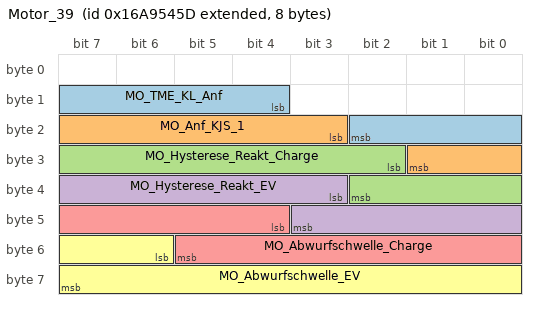
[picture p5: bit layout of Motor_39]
BO_ 2527679581 Motor_39: 8 Gateway
 SG_ MO_TME_KL_Anf : 12|7@1+ (1,0) [0|100] "Unit_PerCent"  TME
 SG_ MO_Anf_KJS_1 : 19|7@1+ (1,0) [0|100] "Unit_PerCent"  TME
 SG_ MO_Hysterese_Reakt_Charge : 26|9@1+ (4,0) [0|2036] "Unit_WattHour"  BMC_MLBevo
 SG_ MO_Hysterese_Reakt_EV : 35|9@1+ (4,0) [0|2036] "Unit_WattHour"  BMC_MLBevo
 SG_ MO_Abwurfschwelle_Charge : 44|10@1+ (4,0) [0|4084] "Unit_WattHour"  BMC_MLBevo
 SG_ MO_Abwurfschwelle_EV : 54|10@1+ (4,0) [0|4084] "Unit_WattHour"  BMC_MLBevo

BO_ 377 Motor_42: 8 Gateway
 SG_ MO_Soll_NutzbarerSOC : 56|8@1+ (0.5,0) [0.0|100.0] "Unit_PerCent"  BMC_MLBevo

BO_TX_BU_ 160 :Gateway,Gateway_PAG;
BO_TX_BU_ 1600 :Gateway,Gateway_PAG;
BO_TX_BU_ 1607 :Gateway,Gateway_PAG;
BO_TX_BU_ 168 :Gateway,Gateway_PAG;
BO_TX_BU_ 958 :Gateway,Gateway_PAG;
BO_TX_BU_ 812 :Gateway,Gateway_PAG;
BO_TX_BU_ 1648 :Gateway,Gateway_PAG;
BO_TX_BU_ 1423 :Gateway,Gateway_PAG;
BO_TX_BU_ 967 :Gateway,Gateway_PAG;
BO_TX_BU_ 340 :Gateway,Gateway_PAG;
BO_TX_BU_ 1366 :Gateway,Gateway_PAG;
BO_TX_BU_ 283 :Gateway,Gateway_PAG;
BO_TX_BU_ 2527679581 :Gateway,Gateway_PAG;
BO_TX_BU_ 377 :Gateway,Gateway_PAG;
CM_ BO_ 1662 "MLB, MXB, MLBevo";
CM_ BO_ 1600 "ab MQB mit QBit Höheneinfo und MO_Versionsinfo_02";
CM_ BO_ 168 "Teil 2 neue Momentenschnittstelle MLB";
CM_ BO_ 1648 "Kombischnittstelle";
CM_ BO_ 1423 "CAN-Botschaft";
CM_ BO_ 967 "MQB - vorher Motor_06 / Umbenennung wg. ID-Wechsel";

CM_ SG_ 1662 LAD_02_BZ "freilaufender Botschaftszähler";
CM_ SG_ 1662 LAD_02_CRC "Ab MQB und MLBevo:
'Berechnung siehe Lastenheft 'End-to-End Kommunikationsabsicherung''

Endwerte siehe Begleitdokument 'S-PDU Kennungsfolgen'";
CM_ SG_ 1662 LAD_Abregelung_BuchseTemp "Reduzierung aufgrund zu hoher Temperatur der Ladebuchse";
CM_ SG_ 1662 LAD_Abregelung_IU_Ein_Aus "Abregelung aufgrund Strom oder Spannung am Eingang oder Ausgang";
CM_ SG_ 1662 LAD_Abregelung_Temperatur "Abregelung aufgrund interner Übertemperatur im Ladegerät";
CM_ SG_ 1662 LAD_CP_Erkennung "Status Control Pilot Überwachung (Erkennung des Control Pilot Duty-Cycles)";
CM_ SG_ 1662 LAD_Fehlerzustand "Sammelfehler Ladegerät - kein Laden möglich";
CM_ SG_ 1662 LAD_Kuehlbedarf "Kühlbedarf des Ladegerätes";
CM_ SG_ 1662 LAD_MaxLadLeistung_HV "Maximale Leistung Ladegerät bezogen auf die maximale Leistung Infrastruktur (Kabel, Ladestation) und Berücksichtigung des Ladegerät-Wirkungsgrades";
CM_ SG_ 1662 LAD_MaxLadLeistung_HV_Offset "Signal kann in Ergänzung zu LAD_MaxLadLeistung_HV (100W Skalierung) genutzt werden, um die Auflösegenauigkeit auf 25W zu erweitern.";
CM_ SG_ 1662 LAD_PRX_Stromlimit "AC-Stromlimit aufgrund der PRX Kabelkodierung";
CM_ SG_ 1662 LAD_Stecker_Verriegelt "Status Steckerverriegelung (Rücklesekontakt des Verrieglungsaktors)";
CM_ SG_ 1662 LAD_Warnzustand "Sammelwarnung Ladegerät
0 keine Warnbedingung aktiv
1 Warnbedingung aktiv, evtl. eingeschränkte Leistungsfähigkeit";

CM_ SG_ 2463978642 LAD_SollStrom_HV_Pfad1 "HV-SollStrom für Rail1 von OBC2";
CM_ SG_ 2463978642 LAD_SollStrom_HV_Pfad2 "HV-Sollstrom für Rail2 von OBC2";
CM_ SG_ 2463978642 LAD_SollStrom_HV_Pfad3 "HV-Sollstrom für Rail3 von OBC2";

CM_ SG_ 2463978643 LAD_05_BZ "4bit Botschaftszähler, wird mit jeder Sendebotschaft inkrementiert";
CM_ SG_ 2463978643 LAD_05_CRC "Für MLB:
Berechnung siehe Lastenheft 'Kommunikationsabsicherung für FlexRay und CAN'
Ab MQB und MLBevo:
Berechnung siehe Lastenheft 'End-to-End Kommunikationsabsicherung'

Endwerte siehe Begleitdokument 'S-PDU Kennungsfolgen'";
CM_ SG_ 2463978643 LAD_AC_MaxStrom_L1 "Maximaler AC-Eingangsstrom auf Rail 1 für OBC2";
CM_ SG_ 2463978643 LAD_AC_MaxStrom_L2 "Maximaler AC-Eingangsstrom auf Rail 2 für OBC2";
CM_ SG_ 2463978643 LAD_AC_MaxStrom_L3 "Maximaler AC-Eingangsstrom auf Rail 3 für OBC2";
CM_ SG_ 2463978643 LAD_Freigabe_LAD2 "Ladefreigabe für zweiten OBC bei Verbau von 2x11 kW OBC";
CM_ SG_ 2463978643 LAD_Max_LadeSpannung_LAD2 "max. voltage / maximal erlaubte Ladespannung";

CM_ SG_ 2589283663 LAD_PlanAntw_Verlustleistung "Antwort auf die Ladeplan-Anfrage für die Ladeplanung: Verlustleistung";
CM_ SG_ 2589283663 LAD_PlanAntw_Zaehler "Antwort auf die Ladeplan-Anfrage für die Ladeplanung: Zähler";

CM_ SG_ 2589283415 LAD_CALID_CVN_MUX "Alle CALID-Indizes bilden zusammen die CALID";
CM_ SG_ 2589283415 LAD_CALID_Index_01 "Software-Calibration-Identification (CALID) im ASCII-Zeichenformat; 
für Ausgabe an das Generic Scan-Tool für OBD in NAR

0x30 entspricht ASCII '0'";
CM_ SG_ 2589283415 LAD_CALID_Index_02 "Software-Calibration-Identification (CALID) im ASCII-Zeichenformat; 
für Ausgabe an das Generic Scan-Tool für OBD in NAR

0x30 entspricht ASCII '0'";
CM_ SG_ 2589283415 LAD_CALID_Index_03 "Software-Calibration-Identification (CALID) im ASCII-Zeichenformat; 
für Ausgabe an das Generic Scan-Tool für OBD in NAR

0x30 entspricht ASCII '0'";
CM_ SG_ 2589283415 LAD_CALID_Index_04 "Software-Calibration-Identification (CALID) im ASCII-Zeichenformat; 
für Ausgabe an das Generic Scan-Tool für OBD in NAR

0x30 entspricht ASCII '0'";
CM_ SG_ 2589283415 LAD_CALID_Index_05 "Software-Calibration-Identification (CALID) im ASCII-Zeichenformat; 
für Ausgabe an das Generic Scan-Tool für OBD in NAR

0x30 entspricht ASCII '0'";
CM_ SG_ 2589283415 LAD_CALID_Index_06 "Software-Calibration-Identification (CALID) im ASCII-Zeichenformat; 
für Ausgabe an das Generic Scan-Tool für OBD in NAR

0x30 entspricht ASCII '0'";
CM_ SG_ 2589283415 LAD_CALID_Index_07 "Software-Calibration-Identification (CALID) im ASCII-Zeichenformat; 
für Ausgabe an das Generic Scan-Tool für OBD in NAR

0x30 entspricht ASCII '0'";
CM_ SG_ 2589283415 LAD_CALID_Index_08 "Software-Calibration-Identification (CALID) im ASCII-Zeichenformat; 
für Ausgabe an das Generic Scan-Tool für OBD in NAR

0x30 entspricht ASCII '0'";
CM_ SG_ 2589283415 LAD_CALID_Index_09 "Software-Calibration-Identification (CALID) im ASCII-Zeichenformat; 
für Ausgabe an das Generic Scan-Tool für OBD in NAR

0x30 entspricht ASCII '0'";
CM_ SG_ 2589283415 LAD_CALID_Index_10 "Software-Calibration-Identification (CALID) im ASCII-Zeichenformat; 
für Ausgabe an das Generic Scan-Tool für OBD in NAR

0x30 entspricht ASCII '0'";
CM_ SG_ 2589283415 LAD_CALID_Index_11 "Software-Calibration-Identification (CALID) im ASCII-Zeichenformat; 
für Ausgabe an das Generic Scan-Tool für OBD in NAR

0x30 entspricht ASCII '0'";
CM_ SG_ 2589283415 LAD_CALID_Index_12 "Software-Calibration-Identification (CALID) im ASCII-Zeichenformat; 
für Ausgabe an das Generic Scan-Tool für OBD in NAR

0x30 entspricht ASCII '0'";
CM_ SG_ 2589283415 LAD_CALID_Index_13 "Software-Calibration-Identification (CALID) im ASCII-Zeichenformat; 
für Ausgabe an das Generic Scan-Tool für OBD in NAR

0x30 entspricht ASCII '0'";
CM_ SG_ 2589283415 LAD_CALID_Index_14 "Software-Calibration-Identification (CALID) im ASCII-Zeichenformat; 
für Ausgabe an das Generic Scan-Tool für OBD in NAR

0x30 entspricht ASCII '0'";
CM_ SG_ 2589283415 LAD_CALID_Index_15 "Software-Calibration-Identification (CALID) im ASCII-Zeichenformat; 
für Ausgabe an das Generic Scan-Tool für OBD in NAR

0x30 entspricht ASCII '0'";
CM_ SG_ 2589283415 LAD_CALID_Index_16 "Software-Calibration-Identification (CALID) im ASCII-Zeichenformat; 
für Ausgabe an das Generic Scan-Tool für OBD in NAR

0x30 entspricht ASCII '0'";
CM_ SG_ 2589283415 LAD_CVN_Byte_1 "Calibration Verification Number (CVN bzw. Checksumme) des SW- und Datenstandes; 
für Ausgabe an das Generic Scan-Tool für OBD in NAR";
CM_ SG_ 2589283415 LAD_CVN_Byte_2 "Calibration Verification Number (CVN bzw. Checksumme) des SW- und Datenstandes; 
für Ausgabe an das Generic Scan-Tool für OBD in NAR";
CM_ SG_ 2589283415 LAD_CVN_Byte_3 "Calibration Verification Number (CVN bzw. Checksumme) des SW- und Datenstandes; 
für Ausgabe an das Generic Scan-Tool für OBD in NAR";
CM_ SG_ 2589283415 LAD_CVN_Byte_4 "Calibration Verification Number (CVN bzw. Checksumme) des SW- und Datenstandes; 
für Ausgabe an das Generic Scan-Tool für OBD in NAR";
CM_ SG_ 2589283415 LAD_CVN_VLD "Valid-Bit der Calibration-Verification-Number (CVN bzw. Checksumme)";

CM_ SG_ 2589283472 LAD_KomponentenFehler_01 "Übertragung OBD relevanter Fehlerpfade vom Secondary zum Primary Steuergerät. 
Zuordnung der generischen Komponentenfehler muss zwischen Sender und Empfänger abgestimmt werden.";
CM_ SG_ 2589283472 LAD_KomponentenFehler_02 "Übertragung OBD relevanter Fehlerpfade vom Secondary zum Primary Steuergerät. 
Zuordnung der generischen Komponentenfehler muss zwischen Sender und Empfänger abgestimmt werden.";
CM_ SG_ 2589283472 LAD_KomponentenFehler_03 "Übertragung OBD relevanter Fehlerpfade vom Secondary zum Primary Steuergerät. 
Zuordnung der generischen Komponentenfehler muss zwischen Sender und Empfänger abgestimmt werden.";
CM_ SG_ 2589283472 LAD_KomponentenFehler_04 "Übertragung OBD relevanter Fehlerpfade vom Secondary zum Primary Steuergerät. 
Zuordnung der generischen Komponentenfehler muss zwischen Sender und Empfänger abgestimmt werden.";
CM_ SG_ 2589283472 LAD_KomponentenFehler_05 "Übertragung OBD relevanter Fehlerpfade vom Secondary zum Primary Steuergerät. 
Zuordnung der generischen Komponentenfehler muss zwischen Sender und Empfänger abgestimmt werden.";
CM_ SG_ 2589283472 LAD_KomponentenFehler_06 "Übertragung OBD relevanter Fehlerpfade vom Secondary zum Primary Steuergerät. 
Zuordnung der generischen Komponentenfehler muss zwischen Sender und Empfänger abgestimmt werden.";
CM_ SG_ 2589283472 LAD_KomponentenFehler_07 "Übertragung OBD relevanter Fehlerpfade vom Secondary zum Primary Steuergerät. 
Zuordnung der generischen Komponentenfehler muss zwischen Sender und Empfänger abgestimmt werden.";
CM_ SG_ 2589283472 LAD_KomponentenFehler_08 "Übertragung OBD relevanter Fehlerpfade vom Secondary zum Primary Steuergerät. 
Zuordnung der generischen Komponentenfehler muss zwischen Sender und Empfänger abgestimmt werden.";
CM_ SG_ 2589283472 LAD_KomponentenFehler_09 "Übertragung OBD relevanter Fehlerpfade vom Secondary zum Primary Steuergerät. 
Zuordnung der generischen Komponentenfehler muss zwischen Sender und Empfänger abgestimmt werden.";
CM_ SG_ 2589283472 LAD_KomponentenFehler_10 "Übertragung OBD relevanter Fehlerpfade vom Secondary zum Primary Steuergerät. 
Zuordnung der generischen Komponentenfehler muss zwischen Sender und Empfänger abgestimmt werden.";
CM_ SG_ 2589283472 LAD_KomponentenFehler_11 "Übertragung OBD relevanter Fehlerpfade vom Secondary zum Primary Steuergerät. 
Zuordnung der generischen Komponentenfehler muss zwischen Sender und Empfänger abgestimmt werden.";
CM_ SG_ 2589283472 LAD_KomponentenFehler_12 "Übertragung OBD relevanter Fehlerpfade vom Secondary zum Primary Steuergerät. 
Zuordnung der generischen Komponentenfehler muss zwischen Sender und Empfänger abgestimmt werden.";
CM_ SG_ 2589283472 LAD_KomponentenFehler_13 "Übertragung OBD relevanter Fehlerpfade vom Secondary zum Primary Steuergerät. 
Zuordnung der generischen Komponentenfehler muss zwischen Sender und Empfänger abgestimmt werden.";
CM_ SG_ 2589283472 LAD_KomponentenFehler_14 "Übertragung OBD relevanter Fehlerpfade vom Secondary zum Primary Steuergerät. 
Zuordnung der generischen Komponentenfehler muss zwischen Sender und Empfänger abgestimmt werden.";
CM_ SG_ 2589283472 LAD_KomponentenFehler_15 "Übertragung OBD relevanter Fehlerpfade vom Secondary zum Primary Steuergerät. 
Zuordnung der generischen Komponentenfehler muss zwischen Sender und Empfänger abgestimmt werden.";
CM_ SG_ 2589283472 LAD_KomponentenFehler_16 "Übertragung OBD relevanter Fehlerpfade vom Secondary zum Primary Steuergerät. 
Zuordnung der generischen Komponentenfehler muss zwischen Sender und Empfänger abgestimmt werden.";
CM_ SG_ 2589283472 LAD_KomponentenFehler_17 "Übertragung OBD relevanter Fehlerpfade vom Secondary zum Primary Steuergerät. 
Zuordnung der generischen Komponentenfehler muss zwischen Sender und Empfänger abgestimmt werden.";
CM_ SG_ 2589283472 LAD_KomponentenFehler_18 "Übertragung OBD relevanter Fehlerpfade vom Secondary zum Primary Steuergerät. 
Zuordnung der generischen Komponentenfehler muss zwischen Sender und Empfänger abgestimmt werden.";
CM_ SG_ 2589283472 LAD_KomponentenFehler_19 "Übertragung OBD relevanter Fehlerpfade vom Secondary zum Primary Steuergerät. 
Zuordnung der generischen Komponentenfehler muss zwischen Sender und Empfänger abgestimmt werden.";
CM_ SG_ 2589283472 LAD_KomponentenFehler_20 "Übertragung OBD relevanter Fehlerpfade vom Secondary zum Primary Steuergerät. 
Zuordnung der generischen Komponentenfehler muss zwischen Sender und Empfänger abgestimmt werden.";
CM_ SG_ 2589283472 LAD_KomponentenFehler_21 "Übertragung OBD relevanter Fehlerpfade vom Secondary zum Primary Steuergerät. 
Zuordnung der generischen Komponentenfehler muss zwischen Sender und Empfänger abgestimmt werden.";
CM_ SG_ 2589283472 LAD_KomponentenFehler_22 "Übertragung OBD relevanter Fehlerpfade vom Secondary zum Primary Steuergerät. 
Zuordnung der generischen Komponentenfehler muss zwischen Sender und Empfänger abgestimmt werden.";
CM_ SG_ 2589283472 LAD_KomponentenFehler_23 "Übertragung OBD relevanter Fehlerpfade vom Secondary zum Primary Steuergerät. 
Zuordnung der generischen Komponentenfehler muss zwischen Sender und Empfänger abgestimmt werden.";
CM_ SG_ 2589283472 LAD_KomponentenFehler_24 "Übertragung OBD relevanter Fehlerpfade vom Secondary zum Primary Steuergerät. 
Zuordnung der generischen Komponentenfehler muss zwischen Sender und Empfänger abgestimmt werden.";
CM_ SG_ 2589283472 LAD_KomponentenFehler_25 "Übertragung OBD relevanter Fehlerpfade vom Secondary zum Primary Steuergerät. 
Zuordnung der generischen Komponentenfehler muss zwischen Sender und Empfänger abgestimmt werden.";
CM_ SG_ 2589283472 LAD_KomponentenFehler_26 "Übertragung OBD relevanter Fehlerpfade vom Secondary zum Primary Steuergerät. 
Zuordnung der generischen Komponentenfehler muss zwischen Sender und Empfänger abgestimmt werden.";
CM_ SG_ 2589283472 LAD_KomponentenFehler_27 "Übertragung OBD relevanter Fehlerpfade vom Secondary zum Primary Steuergerät. 
Zuordnung der generischen Komponentenfehler muss zwischen Sender und Empfänger abgestimmt werden.";
CM_ SG_ 2589283472 LAD_KomponentenFehler_28 "Übertragung OBD relevanter Fehlerpfade vom Secondary zum Primary Steuergerät. 
Zuordnung der generischen Komponentenfehler muss zwischen Sender und Empfänger abgestimmt werden.";
CM_ SG_ 2589283472 LAD_KomponentenFehler_29 "Übertragung OBD relevanter Fehlerpfade vom Secondary zum Primary Steuergerät. 
Zuordnung der generischen Komponentenfehler muss zwischen Sender und Empfänger abgestimmt werden.";
CM_ SG_ 2589283472 LAD_KomponentenFehler_30 "Übertragung OBD relevanter Fehlerpfade vom Secondary zum Primary Steuergerät. 
Zuordnung der generischen Komponentenfehler muss zwischen Sender und Empfänger abgestimmt werden.";
CM_ SG_ 2589283472 LAD_KomponentenFehler_31 "Übertragung OBD relevanter Fehlerpfade vom Secondary zum Primary Steuergerät. 
Zuordnung der generischen Komponentenfehler muss zwischen Sender und Empfänger abgestimmt werden.";
CM_ SG_ 2589283472 LAD_KomponentenFehler_32 "Übertragung OBD relevanter Fehlerpfade vom Secondary zum Primary Steuergerät. 
Zuordnung der generischen Komponentenfehler muss zwischen Sender und Empfänger abgestimmt werden.";

CM_ SG_ 2589283473 LAD_KomponentenFehler_33 "Übertragung OBD relevanter Fehlerpfade vom Secondary zum Primary Steuergerät. 
Zuordnung der generischen Komponentenfehler muss zwischen Sender und Empfänger abgestimmt werden.";
CM_ SG_ 2589283473 LAD_KomponentenFehler_34 "Übertragung OBD relevanter Fehlerpfade vom Secondary zum Primary Steuergerät. 
Zuordnung der generischen Komponentenfehler muss zwischen Sender und Empfänger abgestimmt werden.";
CM_ SG_ 2589283473 LAD_KomponentenFehler_35 "Übertragung OBD relevanter Fehlerpfade vom Secondary zum Primary Steuergerät. 
Zuordnung der generischen Komponentenfehler muss zwischen Sender und Empfänger abgestimmt werden.";
CM_ SG_ 2589283473 LAD_KomponentenFehler_36 "Übertragung OBD relevanter Fehlerpfade vom Secondary zum Primary Steuergerät. 
Zuordnung der generischen Komponentenfehler muss zwischen Sender und Empfänger abgestimmt werden.";
CM_ SG_ 2589283473 LAD_KomponentenFehler_37 "Übertragung OBD relevanter Fehlerpfade vom Secondary zum Primary Steuergerät. 
Zuordnung der generischen Komponentenfehler muss zwischen Sender und Empfänger abgestimmt werden.";
CM_ SG_ 2589283473 LAD_KomponentenFehler_38 "Übertragung OBD relevanter Fehlerpfade vom Secondary zum Primary Steuergerät. 
Zuordnung der generischen Komponentenfehler muss zwischen Sender und Empfänger abgestimmt werden.";
CM_ SG_ 2589283473 LAD_KomponentenFehler_39 "Übertragung OBD relevanter Fehlerpfade vom Secondary zum Primary Steuergerät. 
Zuordnung der generischen Komponentenfehler muss zwischen Sender und Empfänger abgestimmt werden.";
CM_ SG_ 2589283473 LAD_KomponentenFehler_40 "Übertragung OBD relevanter Fehlerpfade vom Secondary zum Primary Steuergerät. 
Zuordnung der generischen Komponentenfehler muss zwischen Sender und Empfänger abgestimmt werden.";
CM_ SG_ 2589283473 LAD_KomponentenFehler_41 "Übertragung OBD relevanter Fehlerpfade vom Secondary zum Primary Steuergerät. 
Zuordnung der generischen Komponentenfehler muss zwischen Sender und Empfänger abgestimmt werden.";
CM_ SG_ 2589283473 LAD_KomponentenFehler_42 "Übertragung OBD relevanter Fehlerpfade vom Secondary zum Primary Steuergerät. 
Zuordnung der generischen Komponentenfehler muss zwischen Sender und Empfänger abgestimmt werden.";
CM_ SG_ 2589283473 LAD_KomponentenFehler_43 "Übertragung OBD relevanter Fehlerpfade vom Secondary zum Primary Steuergerät. 
Zuordnung der generischen Komponentenfehler muss zwischen Sender und Empfänger abgestimmt werden.";
CM_ SG_ 2589283473 LAD_KomponentenFehler_44 "Übertragung OBD relevanter Fehlerpfade vom Secondary zum Primary Steuergerät. 
Zuordnung der generischen Komponentenfehler muss zwischen Sender und Empfänger abgestimmt werden.";
CM_ SG_ 2589283473 LAD_KomponentenFehler_45 "Übertragung OBD relevanter Fehlerpfade vom Secondary zum Primary Steuergerät. 
Zuordnung der generischen Komponentenfehler muss zwischen Sender und Empfänger abgestimmt werden.";
CM_ SG_ 2589283473 LAD_KomponentenFehler_46 "Übertragung OBD relevanter Fehlerpfade vom Secondary zum Primary Steuergerät. 
Zuordnung der generischen Komponentenfehler muss zwischen Sender und Empfänger abgestimmt werden.";
CM_ SG_ 2589283473 LAD_KomponentenFehler_47 "Übertragung OBD relevanter Fehlerpfade vom Secondary zum Primary Steuergerät. 
Zuordnung der generischen Komponentenfehler muss zwischen Sender und Empfänger abgestimmt werden.";
CM_ SG_ 2589283473 LAD_KomponentenFehler_48 "Übertragung OBD relevanter Fehlerpfade vom Secondary zum Primary Steuergerät. 
Zuordnung der generischen Komponentenfehler muss zwischen Sender und Empfänger abgestimmt werden.";
CM_ SG_ 2589283473 LAD_KomponentenFehler_49 "Übertragung OBD relevanter Fehlerpfade vom Secondary zum Primary Steuergerät. 
Zuordnung der generischen Komponentenfehler muss zwischen Sender und Empfänger abgestimmt werden.";
CM_ SG_ 2589283473 LAD_KomponentenFehler_50 "Übertragung OBD relevanter Fehlerpfade vom Secondary zum Primary Steuergerät. 
Zuordnung der generischen Komponentenfehler muss zwischen Sender und Empfänger abgestimmt werden.";
CM_ SG_ 2589283473 LAD_KomponentenFehler_51 "Übertragung OBD relevanter Fehlerpfade vom Secondary zum Primary Steuergerät. 
Zuordnung der generischen Komponentenfehler muss zwischen Sender und Empfänger abgestimmt werden.";
CM_ SG_ 2589283473 LAD_KomponentenFehler_52 "Übertragung OBD relevanter Fehlerpfade vom Secondary zum Primary Steuergerät. 
Zuordnung der generischen Komponentenfehler muss zwischen Sender und Empfänger abgestimmt werden.";
CM_ SG_ 2589283473 LAD_KomponentenFehler_53 "Übertragung OBD relevanter Fehlerpfade vom Secondary zum Primary Steuergerät. 
Zuordnung der generischen Komponentenfehler muss zwischen Sender und Empfänger abgestimmt werden.";
CM_ SG_ 2589283473 LAD_KomponentenFehler_54 "Übertragung OBD relevanter Fehlerpfade vom Secondary zum Primary Steuergerät. 
Zuordnung der generischen Komponentenfehler muss zwischen Sender und Empfänger abgestimmt werden.";
CM_ SG_ 2589283473 LAD_KomponentenFehler_55 "Übertragung OBD relevanter Fehlerpfade vom Secondary zum Primary Steuergerät. 
Zuordnung der generischen Komponentenfehler muss zwischen Sender und Empfänger abgestimmt werden.";
CM_ SG_ 2589283473 LAD_KomponentenFehler_56 "Übertragung OBD relevanter Fehlerpfade vom Secondary zum Primary Steuergerät. 
Zuordnung der generischen Komponentenfehler muss zwischen Sender und Empfänger abgestimmt werden.";
CM_ SG_ 2589283473 LAD_KomponentenFehler_57 "Übertragung OBD relevanter Fehlerpfade vom Secondary zum Primary Steuergerät. 
Zuordnung der generischen Komponentenfehler muss zwischen Sender und Empfänger abgestimmt werden.";
CM_ SG_ 2589283473 LAD_KomponentenFehler_58 "Übertragung OBD relevanter Fehlerpfade vom Secondary zum Primary Steuergerät. 
Zuordnung der generischen Komponentenfehler muss zwischen Sender und Empfänger abgestimmt werden.";
CM_ SG_ 2589283473 LAD_KomponentenFehler_59 "Übertragung OBD relevanter Fehlerpfade vom Secondary zum Primary Steuergerät. 
Zuordnung der generischen Komponentenfehler muss zwischen Sender und Empfänger abgestimmt werden.";
CM_ SG_ 2589283473 LAD_KomponentenFehler_60 "Übertragung OBD relevanter Fehlerpfade vom Secondary zum Primary Steuergerät. 
Zuordnung der generischen Komponentenfehler muss zwischen Sender und Empfänger abgestimmt werden.";
CM_ SG_ 2589283473 LAD_KomponentenFehler_61 "Übertragung OBD relevanter Fehlerpfade vom Secondary zum Primary Steuergerät. 
Zuordnung der generischen Komponentenfehler muss zwischen Sender und Empfänger abgestimmt werden.";
CM_ SG_ 2589283473 LAD_KomponentenFehler_62 "Übertragung OBD relevanter Fehlerpfade vom Secondary zum Primary Steuergerät. 
Zuordnung der generischen Komponentenfehler muss zwischen Sender und Empfänger abgestimmt werden.";
CM_ SG_ 2589283473 LAD_KomponentenFehler_63 "Übertragung OBD relevanter Fehlerpfade vom Secondary zum Primary Steuergerät. 
Zuordnung der generischen Komponentenfehler muss zwischen Sender und Empfänger abgestimmt werden.";
CM_ SG_ 2589283473 LAD_Komponentenfehler_VLD "Valid-Bit der OBD-Komponentenfehler. Das Bit wird beim Fehlerspeicher löschen zurückgenommen und erst wieder gesetzt, wenn der Fehlerspeicher vollständig gelöscht wurde. Der Primary-OBD-ECU soll damit mitgeteilt werden, ob sie den Inhalten der Komponenten";

CM_ SG_ 2589283481 LAD_KomponentenFehler_64 "Übertragung OBD relevanter Fehlerpfade vom Secondary zum Primary Steuergerät. 
Zuordnung der generischen Komponentenfehler muss zwischen Sender und Empfänger abgestimmt werden.";
CM_ SG_ 2589283481 LAD_KomponentenFehler_65 "Übertragung OBD relevanter Fehlerpfade vom Secondary zum Primary Steuergerät. 
Zuordnung der generischen Komponentenfehler muss zwischen Sender und Empfänger abgestimmt werden.";
CM_ SG_ 2589283481 LAD_KomponentenFehler_66 "Übertragung OBD relevanter Fehlerpfade vom Secondary zum Primary Steuergerät. 
Zuordnung der generischen Komponentenfehler muss zwischen Sender und Empfänger abgestimmt werden.";
CM_ SG_ 2589283481 LAD_KomponentenFehler_67 "Übertragung OBD relevanter Fehlerpfade vom Secondary zum Primary Steuergerät. 
Zuordnung der generischen Komponentenfehler muss zwischen Sender und Empfänger abgestimmt werden.";
CM_ SG_ 2589283481 LAD_KomponentenFehler_68 "Übertragung OBD relevanter Fehlerpfade vom Secondary zum Primary Steuergerät. 
Zuordnung der generischen Komponentenfehler muss zwischen Sender und Empfänger abgestimmt werden.";
CM_ SG_ 2589283481 LAD_KomponentenFehler_69 "Übertragung OBD relevanter Fehlerpfade vom Secondary zum Primary Steuergerät. 
Zuordnung der generischen Komponentenfehler muss zwischen Sender und Empfänger abgestimmt werden.";
CM_ SG_ 2589283481 LAD_KomponentenFehler_70 "Übertragung OBD relevanter Fehlerpfade vom Secondary zum Primary Steuergerät. 
Zuordnung der generischen Komponentenfehler muss zwischen Sender und Empfänger abgestimmt werden.";
CM_ SG_ 2589283481 LAD_KomponentenFehler_71 "Übertragung OBD relevanter Fehlerpfade vom Secondary zum Primary Steuergerät. 
Zuordnung der generischen Komponentenfehler muss zwischen Sender und Empfänger abgestimmt werden.";
CM_ SG_ 2589283481 LAD_KomponentenFehler_72 "Übertragung OBD relevanter Fehlerpfade vom Secondary zum Primary Steuergerät. 
Zuordnung der generischen Komponentenfehler muss zwischen Sender und Empfänger abgestimmt werden.";
CM_ SG_ 2589283481 LAD_KomponentenFehler_73 "Übertragung OBD relevanter Fehlerpfade vom Secondary zum Primary Steuergerät. 
Zuordnung der generischen Komponentenfehler muss zwischen Sender und Empfänger abgestimmt werden.";
CM_ SG_ 2589283481 LAD_KomponentenFehler_74 "Übertragung OBD relevanter Fehlerpfade vom Secondary zum Primary Steuergerät. 
Zuordnung der generischen Komponentenfehler muss zwischen Sender und Empfänger abgestimmt werden.";
CM_ SG_ 2589283481 LAD_KomponentenFehler_75 "Übertragung OBD relevanter Fehlerpfade vom Secondary zum Primary Steuergerät. 
Zuordnung der generischen Komponentenfehler muss zwischen Sender und Empfänger abgestimmt werden.";

CM_ SG_ 160 EPS_04_BZ "Botschaftszähler
Botschaft asynchron geroutet. Zählerwert kann springen.";
CM_ SG_ 160 EPS_04_CRC "Für MLB:
'Berechnung siehe Lastenheft 'Kommunikationsabsicherung für FlexRay und CAN''

Ab MQB und MLBevo:
'Berechnung siehe Lastenheft 'End-to-End Kommunikationsabsicherung''

Endwerte siehe Begleitdokument 'S-PDU Kennungsfolgen'";
CM_ SG_ 160 EPS_AWA_Status "beschreibt den Status der AWA-Funktion im EPS-Steuergerät. (Ausweich-Assistent)";
CM_ SG_ 160 EPS_FAS_Regelgroesse "Aktuelle Regelauslastung der STA/STP-Funktionsschnittstelle";
CM_ SG_ 160 EPS_FAS_VZ_Regelgroesse "Richtung der FAS Regelgröße";
CM_ SG_ 160 EPS_Lenkmoment_AbsReduz "Gibt den Absolutwert des aktuelle Handlenkmoment mit einer Auflösung von 0 ,62 Nm aus";
CM_ SG_ 160 EPS_QBit_Zahnstangen_Pos "beschreibt die Qualität/Vertrauenswürdigkeit der Zahnstangenposition";
CM_ SG_ 160 EPS_STA_Status "beschreibt den Status der STA-Funktion im EPS-Steuergerät. (Stauassistent)";
CM_ SG_ 160 EPS_Versorgungsspannung "Gibt die am Steuergerät anliegende Spannung aus.
";
CM_ SG_ 160 EPS_Versorgungsstatus "Erkennung Störung im Versorgungspfad
";
CM_ SG_ 160 EPS_VZ_Zahnstangenposition "Vorzeichen der Position/Verschiebung der Zahnstange bzgl. Lenkungsmitte
Vorzeichen:
(Fahreransicht: positiv = links von der Nullstellung des Lenkrades)
Nullstellung = +0mm";
CM_ SG_ 160 EPS_Zahnstangen_Pos "Position/Verschiebung der Zahnstange bzgl. Lenkungsmitte";

CM_ SG_ 1600 MO_Absperrventil_oeffnen "Signal an Klima-SG das Absperrrventil anzusteuern. Ab D4 auch 0x3 Ventil_schließen.

Im MQB wird hier der Soll-Status des Absperrventils ausgegeben.
Achtung: bei z. B. klemmendem Ventil entspricht das Signal nicht dem tatsächlichen Status!";
CM_ SG_ 1600 MO_aktives_Getriebeheizen "Information für Getriebe, ob ein Ventil für Getriebheizen angesteuert werden muss";
CM_ SG_ 1600 MO_Ansaugluft_Temp "In Fahrzeugen ohne Außentemperatur vom Kombi kann aus der Ansauglufttemperatur auf die Außentemperatur geschlossen werden. Beim SDI ist das mit einer gewissen Genauigkeit gegeben. Genutzt wird es vom ASG.";
CM_ SG_ 1600 MO_Getriebe_kuehlen "Anforderung Getriebekühlventilansteuerung";
CM_ SG_ 1600 MO_Heizungspumpenansteuerung "Anforderung Heizungspumpenansteuerung
MQB und Hybrid: Status der Heizungsunterstützungspumpe am MSG
";
CM_ SG_ 1600 MO_Hoeheninfo "Korrekturfaktor Höhe (1 entspricht 1013 mbar)";
CM_ SG_ 1600 MO_HYB_Fehler_HV_Netz "Im HV-Bordnetz ist fehlerbedingt kein generatorischer Betrieb möglich. Das 12V-Bordnetz wird über den DC/DC-Wandler allein aus der Traktionsbatterie gespeist. Um diesen Zustand möglichst lange aufrechterhalten zu können, sollten Komfort-Verbraucher abgesc";
CM_ SG_ 1600 MO_Kennfeldk "Die Kennfeldkühlung ist in diesem Fahrzeug verbaut und hat keinen Systemfehler";
CM_ SG_ 1600 MO_KL15_Abschaltempfehlung "Kessy Abschaltempfehlung nach Verlassen des Fahrzeugs";
CM_ SG_ 1600 MO_Kuehlmittel_Temp "Kuehlmitteltemperatur";
CM_ SG_ 1600 MO_Mom_Traegheit_02 "Massenträgheit (J) der Motors bzw. der Antriebsmaschinen in kgm².

Zur Berücksichtigung des E-Motor in Hybrid-Projekten:
in MLB-Projekten wird nur der J-Wert des Verbrennungsmotors und nicht der J-Wert des E-Motors berücksichtigt.
In MQB/MLBevo-Projek";
CM_ SG_ 1600 MO_Nachlaufzeit_Heizungspumpe "Nachlaufzeit für Heizungspumpe für Turboladerschutz";
CM_ SG_ 1600 MO_Oel_Temp "Realer Meßbereich ca. -40..150 Grad";
CM_ SG_ 1600 MO_QBit_Ansaugluft_Temp "
";
CM_ SG_ 1600 MO_QBit_Hoeheninfo "Qualifizierungsbit der Höheninfo. Gesetzt bei Ersatzwert, Init oder Fehler.";
CM_ SG_ 1600 MO_QBit_Kuehlmittel_Temp "
";
CM_ SG_ 1600 MO_SpannungsAnf "Forderung des Motor-SGs zur Spannungsanhebung";
CM_ SG_ 1600 MO_Versionsinfo_02 "Versioninformation vom Motor zur Steuerung bei inkompatiblen KMatrix-Änderung bzw. Einführung von neuen Funktionen, die in den Empfängern verriegelt werden müssen. Zu jedem Ereignis wird ein fixer Zählerstand zugeordnet, um dem Empfänger die funktionale Ä";

CM_ SG_ 1607 MO_CO2_Faktor "dynamischer Umrechnungsfaktor von l in CO2";
CM_ SG_ 1607 MO_E85_Sensor "Information über den E85 Gehalt (%-mass.) im Ottokraftstoff";
CM_ SG_ 1607 MO_Ethanol_Spuelhinweis "Hinweis das der Fahrer beim nächsten Tanken Ethanol armen Sprit tanken soll.";
CM_ SG_ 1607 MO_ITM_Kuehlmittel_Temp "Kuehlmitteltemperatur: Ersatzkühlmitteltemperatur für Motoren mit ITM (Thermomanagement)

ACHTUNG: Ab MQB wird in diesem Signal das Anzeigeplateau durch das MSG dargestellt!";
CM_ SG_ 1607 MO_Kraftstofffilter_Wasser "Für Schlechtkraftstoffländer wird das Wasserabscheidevolumen im Dieselkraftstofffilter mit einem  Wassersensor überwacht. Ist das Volumen erschöpft, erfolgt im Kombi eine entsprechende Anzeige.";
CM_ SG_ 1607 MO_MKB_01 "Motorkennbuchstabe 1";
CM_ SG_ 1607 MO_MKB_02 "Motorkennbuchstabe 2";
CM_ SG_ 1607 MO_MKB_03 "Motorkennbuchstabe 3";
CM_ SG_ 1607 MO_MKB_04 "Motorkennbuchstabe 4";
CM_ SG_ 1607 MO_MKB_MUX "Die vier Motorkennbuchstaben werden gemultiplext in MO_MKB übertragen. Das Signal MO_MKB_MUX stellt das Steuersignal für diesen Multiplexer dar.";
CM_ SG_ 1607 SCR_Akustik "Ansteuerung von Summer/Gong bei Aktivieren der SCR-Warnungen.
Bedienung des Signals nur bei Dieseln mit SCR-System. Andere senden Initwert.";
CM_ SG_ 1607 SCR_Anz_Motorstarts "Anzahl noch möglicher Motorstarts, wenn Reichweite = 0 ist
0..13 = Anzeige 'x mögliche Restarts'
14 = Eingeschränkte Fahrfunktion (z. Zt. Audi)
15 = keine Einschränkung (Anzeige Reichweite)
Bedienung des Signals nur bei Dieseln mit SCR-System.";
CM_ SG_ 1607 SCR_Inducement_Strategie "Art des Motor-Inducement-Konzepts. Abhängig von diesem Signal sind die Warntexte zwischen 'Kein Motorstart (in...km)' und 'eingeschränkte Fahrbarkeit (in ...km)' auszuwählen.";
CM_ SG_ 1607 SCR_Reichweite "Gesamtreichweite in km der aktuellen SCR-Tankfüllung.
Bedienung des Signals nur bei Dieseln mit SCR-System.";
CM_ SG_ 1607 SCR_Systemfehler "Ansteuerung Anzeige für SCR-Systemfehler";
CM_ SG_ 1607 SCR_Text "Warntext (z. B. in Kombination mit SCR Warnstufe und SCR-Systemfehler).
Bedienung des Signals nur bei Dieseln mit SCR-System. Andere senden Initwert.";
CM_ SG_ 1607 SCR_verbaut "Die SCR-Signale deren Initwert ungleich 0 sind, werden nur dann ausgewertet, wenn SCR_verbaut == 1 den Verbau des SCR Systems zeigt.";
CM_ SG_ 1607 SCR_Warnstufe_1 "Ansteuerung der SCR Füllstandswarnlampe (Stufe 1) (gelbe Lampe) SCR_Warnstufe_1 (Prio 2).
Bedienung des Signals nur bei Dieseln mit SCR-System. Andere senden Initwert.";
CM_ SG_ 1607 SCR_Warnstufe_2 "Ansteuerung der SCR Füllstandswarnlampe (Stufe 2) (Blinkbit für gelbe Lampe oder rote Lampe) SCR_Warnstufe_2 (Prio 1).
Bedienung des Signals nur bei Dieseln mit SCR-System. Andere senden Initwert.";

CM_ SG_ 168 MO_Drehzahl_01 "Im Fehlerfall wird die Motordrehzahl über die Nockenwellendrehzahl als Ersatzgrösse ausgegeben

Bei Parallelhybrid: Getriebeeingangsdrehzahl (=E-Maschinen Drehzahl)

Hinweis: 
Ehemaliger Fehlerwert 0xFFFF wird senderseitig nicht unterstützt. 
Diesen";
CM_ SG_ 168 MO_Mom_Begr_dyn "Einheitenloser Wert! Faktor in MO_Faktor_Momente (CAN V6.x) bzw. MO_Faktor_Momente_02 (CAN V7.x/V8.x) in Motor_Code_01 beachten!

Bei aktueller Drehzahl kurzfristig (ca. 100..200 ms) max. mögliches Moment (Summe aus Verbrennungsmotor und E-Motor), wird ";
CM_ SG_ 168 MO_Mom_Begr_stat "Einheitenloser Wert! Faktor in MO_Faktor_Momente (CAN V6.x) bzw. MO_Faktor_Momente_02 (CAN V7.x) in Motor_Code_01 beachten!

Bei aktueller Drehzahl quasistationär (nach ca. 3..5 s) max. mögliches Moment (Summe aus max. Moment des Verbrennungsmotors aus ";
CM_ SG_ 168 MO_Mom_neg_verfuegbar "Einheitenloser Wert! Faktor in MO_Faktor_Momente (CAN V6.x) bzw. MO_Faktor_Momente_02 (CAN V7.x) in Motor_Code_01 beachten!

Bei aktueller Drehzahl im nächsten Task (bei CAN-Übertragung z.B. 10ms) tatsächlich verfügbares negatives Moment (Summe aus Verl";
CM_ SG_ 168 MO_Momentenintegral_02 "100  %  entspricht volle Verfügbarkeit aktuell vorhanden. 0 % entspricht Integral bis Limit gefüllt, erhöhender Eingriff kann aktuell nicht berücksichtigt werden oder aufgrund eines Fehlers nicht verfügbar
";
CM_ SG_ 168 MO_QBit_Drehzahl_01 "AUDI D4: Zykluszeit: 10ms (siehe Zykluszeit schnell/Cycletime Fast)

Achtung:
Reduktion der Zykluszeit Motor_03 auf 10ms geplant.
Projektabhängig soll künftig mit 10ms gesendet werden.
Empfänger die in weiteren Konzern-Projekten eingesetzt werden müs";
CM_ SG_ 168 Motor_12_CRC "Für MLB:
'Berechnung siehe Lastenheft 'Kommunikationsabsicherung für FlexRay und CAN''

Ab MQB und MLBevo:
'Berechnung siehe Lastenheft 'End-to-End Kommunikationsabsicherung'

Endwerte siehe Begleitdokument 'S-PDU Kennungsfolgen'";

CM_ SG_ 958 MO_Aussp_Anlass "Das Signal zeigt an, ob die Wiederholstartsperre aktiv ist. D. h. eine Ansteuerung des Anlassers wird auch bei erfüllten Startvoraussetzungen (HS: Interlock betätigt bzw. AT: P/N eingelegt und Bremse betätigt) nicht erfolgen.";
CM_ SG_ 958 MO_BKV_Unterdruckwarnung "Über die Unterdruckwarnung signalisiert das MSG dem ESP, dass kein ausreichender Unterdruck für den BKV zur Verfügung gestellt werden kann.";
CM_ SG_ 958 MO_BLS "Ungefiltertes Rohsignal des Bremslichtschalters, nur wenn HW-Eingang bestückt und ausgewertet wird. Bei Motoren ohne genutzten HW-Eingang wird kein Ersatzwert (bspw. SW-Signal über CAN) ausgegeben!
Bei AUDI muss das Signal wg. Bremslichtfunktion immer be";
CM_ SG_ 958 MO_BMS_NV_Anf_stuetzen "Garantierte Unterstützung des Zusatzspeichers ist erforderlich. Zusatzspeicher muss an das Versorgungsnezt angebunden werden. ";
CM_ SG_ 958 MO_EKlKomLeiRed "Anforderung an die Klimasteuerung, die Leistungsaufnahme des E-Kompressors bei schlechtem SOC und in bestimmten Fahrsituationen zu begrenzen. (Das bereits bestehende Signal 'Klimakompressor aus' als stets umzusetzende Anforderung bleibt unverändert besteh";
CM_ SG_ 958 MO_Ext_E_Fahrt_aktiv "Funktionsrückmeldung zum erw. E-Fahr-Betrieb über Lampe/LED im E-Mode-Taster";
CM_ SG_ 958 MO_Fahrer_bremst "Redundante Bremsinformation vom Motor.

MLB:
AUDI D4: Zykluszeit: 10ms (siehe Zykluszeit schnell/Cycletime Fast)
Im AUDI B8 wird in diesem Bit der Wert der ESP-CAN-Information 'ESP_Fahrer_bremst' ausgegeben.

Achtung:
Reduktion der Zykluszeit Motor";
CM_ SG_ 958 MO_FMAus_aktiv "Das Signal gibt Rückmeldung ob Freilauf Motor aus aktiv ist. Beleibt auch 0km/h (unterhalb der StartStopp Schwelle) weiterhin aktiv.";
CM_ SG_ 958 MO_FMAus_Startvariante "Startvariante beim Motorstart aus der Freilauf-Motor-AUS Phase";
CM_ SG_ 958 MO_Freig_Anlass "Bit wird gesetzt, wenn der Motor beim Automatikstart gestartet werden darf (Motorstillstand, Emissionsmaßnahmen sind erfüllt).";
CM_ SG_ 958 MO_Freig_Reku "Empfehlung des Motor-SG's zur Spannungsabsenkung/-anhebung für den Rekuperationsbetrieb";
CM_ SG_ 958 MO_Freigabe_Segeln "Freigabebit des Segelbetriebs im Getriebe. Bedingt durch bestimmte Diagnosen und Adaptionen des MSGs, die nur im Schub möglich sind, darf nicht jede Schubphase für einen Segelbetrieb genutzt werden. Eine Freigabe bleibt auch außerhalb einer Schubphase bes";
CM_ SG_ 958 MO_Gangposition "MLB:
Stellung des Wählhebels in der Schaltgasse des Handschaltgetriebes.
MLBevo: 
Ausweitung der Bedienung auch auf Automatikgetriebe;
Routing des Signals GE_Fahrstufe: 
1. Position_R (dez. 6) auf MO_Gangposition: Gang_R (dez. 13) wegen Entfall Signa";
CM_ SG_ 958 MO_Handshake_STH "Es gilt: Signalspec MO_Handshake v1.0

Handshake zwischen MSG und STH. Wenn das MSG die EKP aufgrund einer STH-Anforderung ansteuert und kein Fehlereintrag bzgl. EKP/KPE/NDR vorliegt, wird das Bit gesetzt.";
CM_ SG_ 958 MO_HYB_Fahrbereitschaft "Signal steuert u.a. in der Lenkhilfe zusammen mit weiteren Informationen den Modewechsel in den 'Drivemode'
Grüne Anzeige im Kombiinstrument zur Signalisierung der Bereitschaft des Hybridsystems.";
CM_ SG_ 958 MO_HYB_VM_aktiv "0 = VMotor wird nicht aktiv gehalten (nVM < n_min und keine LL-Regelung aktiv)
1 = VMotor aktiv (ab der ersten Einspritzung; gilt auch für Schubbetrieb, wenn VMotor spätestens durch LLRegelung befeuert würde)
Verwendet zur Bestimmung des Ist-Zustandes";
CM_ SG_ 958 MO_Interlock "Das Motorsteuergerät gibt die Information aus, ab wann der Kupplungsschalter durch das Motorsteuergerät als getreten gesehen wird.
Bei Systemen für Start Stopp muss das Interlocksignal für einen Start durch das MSG generiert werden, sobald der Schalthebe";
CM_ SG_ 958 MO_Kickdown "Es gilt: Signalspec MO_Kickdown v1.0";
CM_ SG_ 958 MO_Kl_50 "Klemme 50: Startausführung durch Ritzelstarter

MLB: nicht von allen Motoren gesendet
MQB/MLBevo: gesendet von allen Motoren";
CM_ SG_ 958 MO_Kl_75 "Klemme X
";
CM_ SG_ 958 MO_Klima_Eingr "Eingriffe des Motor bei der Klima";
CM_ SG_ 958 MO_KomFehler_ESP "Anzeige Kommunikationsfehler bei Empfang vom ESP";
CM_ SG_ 958 MO_Konsistenz_Bremsped "MLB:

AUDI D4: Zykluszeit: 10ms (siehe Zykluszeit schnell/Cycletime Fast)
Siehe 'Funktionsspezifikation Bremslichtinfo B8'

Achtung:
Reduktion der Zykluszeit Motor_03 auf 10ms geplant.
Projektabhängig soll künftig mit 10ms gesendet werden.
Empfäng";
CM_ SG_ 958 MO_Kuppl_schalter "MLB:
Das Motorsteuergerät gibt die Information aus, ab wann der Kupplungsschalter durch das Motorsteuergerät als getreten gesehen wird
0x0: Schalter sagt betätigt (Ausgekuppelt)
0x1: Schalter sagt nicht betätigt (Eingekuppelt)

MQB:
Nur Handschalter";
CM_ SG_ 958 MO_Motor_laeuft "Das Motorsteuergerät gibt die Information aus, ab wann der Motor verbrennungsbedingt autark läuft und durch zuschaltbare Nebenaggregate mechanisch belastbar ist (z.B. durch Generator, Klimakompressor, etc.).

Die 'Motor läuft' Information wird ausgegebe";
CM_ SG_ 958 MO_PTC_Status "Status-Rückmeldung vom MSG zum aktuellen PTC-Status (stufiges PTC, Relais am MSG). Bei Ansteuerung eines stufigen PTC durch ein anderes SG beschreibt das Signal die vom MSG freigegebene PTC-Stufe.";
CM_ SG_ 958 MO_QBit_Fahrer_bremst "MLB:
AUDI D4: Zykluszeit: 10ms (siehe Zykluszeit schnell/Cycletime Fast)

Achtung:
Reduktion der Zykluszeit Motor_03 auf 10ms geplant.
Projektabhängig soll künftig mit 10ms gesendet werden.
Empfänger die in weiteren Konzern-Projekten eingesetzt werd";
CM_ SG_ 958 MO_QBit_Gangposition "Qualitätsbit zum Signal MO_Gangposition";
CM_ SG_ 958 MO_QBit_KL_75 "Q - Bit für das KL 75 Signal zur Vermeidung der fehlerhaften Erkennung von Motorstarts. 
Wird auf 1 gesetzt, solange das Motorsteuergerät KL15 = AUS erkannt hat.";
CM_ SG_ 958 MO_Remotestart_Betrieb "Das MSG ist für den Remotestart-Betrieb bereit. Nach Empfang der Motorstartanforderung für RSt-Betrieb durch BCM wird der Fahrzeugmotor gestartet und solange der Motor läuft, bleibt dieses Bit aktiv. Dieses Signal ist nur zur Verwendung durch das BCM zur ";
CM_ SG_ 958 MO_Remotestart_moeglich "Wenn Bit gesetzt, würde das MSG bei entsprechender Anforderung durch das BCM den Remotestartbetrieb einleiten, d.h. das MSG ist remotestartfähig und es liegen aktuell keine relevanten Fehler oder andere Abbruchgründe vor.";
CM_ SG_ 958 MO_Signalquelle_Gangposition "Signalquelle des Signals MO_Gangposition
0: Signalquelle Gangpositionssensor
1: Signalquelle Modellwert (v/n)";
CM_ SG_ 958 MO_StartStopp_Fahrerwunsch "Fahreraktivität Start/Stop";
CM_ SG_ 958 MO_StartStopp_Motorstopp "Motor-Stopp durch Start/Stopp-Koordinator
HYBRID:
Wenn MO_Hybridfahrzeug = 1 gilt:
Verbrennungsmotor durch Hybrid-Koordinator im MSG ausgeschaltet. 
Die definierten Start/Stopp-Signale beziehen sich nur auf den Verbrennungsmotor!";
CM_ SG_ 958 MO_StartStopp_Status "Aktivitätsstatus Start/Stopp-Koordinator
HYBRID:
Wenn MO_Hybridfahrzeug = 1 gilt:
Signal bezieht sich nur auf den Verbrennungsmotor, nicht auf den Hybridantrieb
";
CM_ SG_ 958 MO_StartStopp_Wiederstart "Motorwiederstart durch Start/Stopp-Koordinator
HYBRID:
Wenn MO_Hybridfahrzeug =1 gilt:
Warnung vor Spannungseinbruch beim Zustart des Verbrennungsmotors. 
-nicht relevant, da derzeit kein Start über 12V-Starter geplant-
Dieses Signal wird nur vom Hyb";
CM_ SG_ 958 MO_StartVorauss_erfuellt "Dient der Fallunterscheidung bei ZAT-Betätigung im Zustand 'KL15 ein' (bei nicht gesetztem Signal folgt KL15 aus, bei gesetztem Signal folgt setzen KL50-Anf.)

0: Signal nicht bedient 
1: Voraussetzungen zur Antriebsstrangaktivierung / Startvoraussetzu";
CM_ SG_ 958 MO_Zylinderabschaltung "Status Zylinderabschaltung Motor";
CM_ SG_ 958 Motor_14_CRC "Ab MQB und MLBevo:
'Berechnung siehe Lastenheft 'End-to-End Kommunikationsabsicherung'

Endwerte siehe Begleitdokument 'S-PDU Kennungsfolgen'";

CM_ SG_ 812 MO_BZS_Charisma_FahrPr "Rückmeldung des aktuellen Charisma-Fahrprogramms der MSG Betriebsstrategie

MLBevo: Aktuelles Fahrprogramm des Charisma-Teilnehmers (siehe Systemlastenheft Drive Select)
MQB: Istwert der Kennlinie (siehe Systemlastenheft MQB FPA)";
CM_ SG_ 812 MO_BZS_Charisma_Status "Charisma Systemstatus des Charisma-Teilnehmers MSG (Betriebszustände)

Wert 0x3 ist nur für Fahrzeuge ab MQB relevant";
CM_ SG_ 812 MO_Charisma_FahrPr "MLBevo: Aktuelles Fahrprogramm des Charisma-Teilnehmers (siehe Systemlastenheft Drive Select)
MQB: Istwert der Kennlinie (siehe Systemlastenheft MQB FPA)";
CM_ SG_ 812 MO_Charisma_Status "Charisma Systemstatus des Charisma-Teilnehmers

Wert 0x3 ist nur für Fahrzeuge ab MQB relevant";
CM_ SG_ 812 MO_Drehzahlbeeinflussung "Faktor zur Anhebung der Fahrdrehzahl im Warmlauf";
CM_ SG_ 812 MO_Luftpfad_aktiv "Getriebeeingriff wird zusätzlich zum Zündungspfad auch über den Luftpfad umgesetzt, kommt zu MLB neu in die PL48-Getriebe";
CM_ SG_ 812 MO_MAX_Wunschdrehzahl "maximale Motorwunschdrehzahl, die vom Getriebe nicht überschritten werden darf

Signal darf GE_Synchro_Wunschdrehzahl nicht spiegeln";
CM_ SG_ 812 MO_MIN_Wunschdrehzahl "minimale Motorwunschdrehzahl aufgrund Regeneration, die vom Getriebe nicht unterschritten werden darf

Hinweis: 
Ehemaliger Fehlerwert 0xFF wird senderseitig nicht unterstützt. 
Diesen Wert aus Kompatibilitätsgründen nicht neu belegen!";
CM_ SG_ 812 MO_NGS_Position "Messwert des Neutralgangsensors
(nur Handschalter)";
CM_ SG_ 812 MO_NGS_Status "Status des Signals MO_NGS_Position. Das MSG prüft die Plausibilität nur hinsichtlich sicher geöffnetem Triebstrang.";
CM_ SG_ 812 MO_Prio_MAX_Wunschdrehzahl "Prioritätsbit der Motorwunschdrehzahl  als MAX";
CM_ SG_ 812 MO_Prio_MIN_Wunschdrehzahl "Prioritätsbit der Motorwunschdrehzahl als MIN";
CM_ SG_ 812 MO_Rampenzeit_Generator_Anf "Das Motorsteuergerät kann eine Load-Response-Zeit des Generators vom Niedervoltenergiemanagement (NVEM) anfordern. Die Load-Response-Zeit wird vom NVEM umgesetzt, wenn dies bordnetzverträglich möglich ist.";
CM_ SG_ 812 MO_Sperrung_FahrPr_BZS "Sperrung einzelner Betriebszustände bzgl. Kommunikation zwischen Motor-SG und Charisma-SG (Gateway)";
CM_ SG_ 812 MO_StSt_Charisma_FahrPr "MLBevo: Aktuelles Fahrprogramm des Charisma-Teilnehmers (siehe Systemlastenheft Drive Select)
MQB: Istwert der Kennlinie (siehe Systemlastenheft MQB FPA)";
CM_ SG_ 812 MO_StSt_Charisma_Status "Charisma Systemstatus des Charisma-Teilnehmers

Wert 0x3 ist nur für Fahrzeuge ab MQB relevant";
CM_ SG_ 812 MO_v_Begrenz_Aktivierbar "Fehlerbit wird vom Motor-SG gesetzt, wenn dieses nicht in dieGeschwindigkeits-begrenzung gehen kann, ein Fehler während der v-Begrenzung auftritt oder v > v_Begrenzung - v_Delta";
CM_ SG_ 812 MO_v_Begrenzung_Niveau "Zeigt an, ob eine v-Begrenzung aufgrund Anforderung der Niveauregelung  im MSG aktiv ist oder nicht (Signal für Niveau zum Steuern der Kombianzeige).";

CM_ SG_ 1648 MO1_Freigabe_Info_WFS "WFS-Freigabeinformation";
CM_ SG_ 1648 MO1_Freigabe_Verfallsinfo_WFS "WFS-Freigabeverfallsinformation";
CM_ SG_ 1648 MO1_Sperr_Info_WFS "WFS-Sperrinformation";
CM_ SG_ 1648 MO_Abstellzeit "Abstelldauer nach letztem KL15 aus

Hinweis: 
Ehemaliger Fehlerwert 0xFF wird senderseitig nicht unterstützt. 
Diesen Wert aus Kompatibilitätsgründen nicht neu belegen!";
CM_ SG_ 1648 MO_Abstellzeit_Status "Statusinformation zur Abstellzeit
0: Die dem Status zugeordnete Variable konnte noch nicht berechnet werden. 
1: Die dem Status zugehörige Variable wurde korrekt berechnet. 
2: Der Wert der zugehörigen Variablen ist nur ein Minimalwert. 
3: Der Wert d";
CM_ SG_ 1648 MO_ANC_Kennfeld_Anf "Anforderung ANC Kennfeldumschaltung";
CM_ SG_ 1648 MO_Anzahl_Abgesch_Zyl "Gibt die Anzahl der abgeschalteten Zylinder an. In Übergangszuständen wird der Zielbetriebszustand angezeigt.";
CM_ SG_ 1648 MO_Bremslicht_Reku "Bremslicht (ggf. bei Rekuperation durch E-Motor) wird angesteuert";
CM_ SG_ 1648 MO_Drehzahl_Warnung "Warnhinweis zum Kombi im Fall einer fehlerbehafteten Drehzahlbegrenzung";
CM_ SG_ 1648 MO_EPCL "Die Anforderung der EPC-Lampe vom MSG ans Kombi soll durch das Bus-Signal MO_EPCL gemäß folgender Logik erfolgen:
MO_EPCL = 0 dez -> EPC Lampe aus, kein Text
MO_EPCL = 1 dez -> gelbe EPC-Symbolik, Text „Antrieb: Störung! Bitte Service aufsuchen“
MO_EPC";
CM_ SG_ 1648 MO_Ethanol_BS_Texte "Ethanol Brennstoff-Texte im Kombi

0 = kein Text
1 = E85 Warm_Up
2 = FlexFuel Warnung 3.Stufe (Too cold for ethanol)
3 = Warmfahrempfehlung MQB / FlexFuel Warnung 1.Stufe (Refuel with gasoline)
4 = FlexFuel Warnung 2. Stufe (Refuel with gasoline)
5";
CM_ SG_ 1648 MO_Fahrzeugtyp "Unterscheidet die Fahrzeugtypen bzgl. der Antriebsart";
CM_ SG_ 1648 MO_Fehler_Zylabsch "Fehlerstatus der Funktion Zylinderabschaltung ";
CM_ SG_ 1648 MO_Hybrid_StartStopp_LED "Ansteuerung der Funktions-LED der Hybrid Taste bzw. Start/Stop Deaktivierungstaste.
Der Start/Stopp-Master (derzeit im MSG) (oder ein künftiger Hybrid-Master) soll die Ansteuerung senden.";
CM_ SG_ 1648 MO_max_Ladedruck "maximal möglicher Ladedruck (zur Anpassung des Anzeigebereichs bei absoluter Ladedruckanzeige)";
CM_ SG_ 1648 MO_NMAX_Schaltanzeige "Maximaldrehzahl für Schaltanzeige";
CM_ SG_ 1648 MO_obere_Drehzahlgrenze "obere Drehzahlgrenze des Motors";
CM_ SG_ 1648 MO_StartStopp_PopUp "Das Signal zeigt an, ob der StSt-Status mittels Deaktivierungstaster geändert wurde. Ein Wechsel auf die Werte 01 oder 10 löst im Kombi ein entsprechendes PopUp aus. Bei einem Statuswechsel durch andere Signalquellen (z.B. Charisma, fehlerbedingte Abschal";
CM_ SG_ 1648 MO_Zylabsch_Texte "Zylinderabschaltung mode in Kombi, fuer Zylinderabschaltung";
CM_ SG_ 1648 MO_Zylabsch_Texte_02 "ZAS-Anzeige für den Fahrer im Kombi
0: kein ZAS (generell keinerlei ZAS-Anzeigen)  (Init für nicht ZAS-Motor)
1: ZAS im Vollmotorbetrieb  (Init für ZAS-Motor)
2: ZAS im Abschaltbetrieb: 1 Zyl aktiv
3: ZAS im Abschaltbetrieb: 2 Zyl aktiv
4: ZAS im Abs";

CM_ SG_ 1423 FSA_Fehlerpfade_Initialisieren "Aktivierung der Fehlerpfad-Initialisierung  beim FSP Löschen ueber Mode04";
CM_ SG_ 1423 MO_FSA_Sensorheizung "Aktivierung Sensorheizung FSA";
CM_ SG_ 1423 MO_Getriebe_Oelalterung "Prozentualer Alterungswert Getriebeöl";
CM_ SG_ 1423 MO_ITM_Status "Statusinformationen an TME-Steuergerät bzgl. Thermomanagement";
CM_ SG_ 1423 MO_KJS_LLK_Pos_Summe "Aerodynamisch wirksamer Gesamtöffnungswinkel aller Kühlerlüfter- und LLK-Jalousiesteller.

Pos_Frontendverschl_ungenau = 15 zeigt eine Fehlfunktion bzw. unbekannte Position einer oder mehrere Jalousiesteller an.";
CM_ SG_ 1423 MO_Kuehlmittel_Temp_Rohwert "Rohwert Kuehlmitteltemperatur
Das Signal wird derzeit von Diesel-Projekten nicht bedient.";
CM_ SG_ 1423 MO_Oel_Temp_Radsatz "Öltemperatur in PDK Radsatz ";
CM_ SG_ 1423 MO_Tankdruck "Tank Über-/Unterdruck wird für Ansteuerintensität der Treibstoffpumpe der Standheizung benötigt.";

CM_ SG_ 967 MO_E_Mode "Anforderung der E-Mode Statusanzeige";
CM_ SG_ 967 MO_E_Texte "Anforderung von Hinweistexten des E-Systems separat für HEV/BEV bzw. erweiterbar für PHEV";
CM_ SG_ 967 MO_E_Warnungen "Anforderung von Warnanzeigen des E-Systems separat für HEV/BEV bzw. erweiterbar für PHEV";
CM_ SG_ 967 MO_EFLEX_Lampe "Um ein Starten mit E100 zu ermöglichen, wird Kraftstoff ggf. vorgeheizt. Das Signal dient der Anzeige des Heizungsstatus.

Heizung aus -> Lampe aus
Heizung ein -> Lampe ein
Heizung ein und Startversuch -> Lampe blinkend
Heizung nicht möglich -> Lampe";
CM_ SG_ 967 MO_Heissleuchte "Ansteuerung der Kühlwassertemperatur-Heißleuchte (Sensor nur noch am Motorsteuergerät): Temperaturschaltschwellen mit Hysterese (bei VW D1/Colorado Kombi derzeit noch nicht genutzt).";
CM_ SG_ 967 MO_ITM_Warnung_Pumpe "Textanzeige: 'Motor sofort abstellen, geschaltete Wasserpumpe defekt / klemmt'";
CM_ SG_ 967 MO_KJS_nicht_bereit "Dieses Signal zeigen einen Fehler der Kühlerjalousie mit unbekannter Stellung der Lamellen. ";
CM_ SG_ 967 MO_Kuehlerluefter_1 "Ansteuertastverhaeltnis (PWM) der Kuehlerluefterendstufe 1";
CM_ SG_ 967 MO_Kuehlerluefter_2 "Ansteuertastverhaeltnis (PWM) der Kuehlerluefterendstufe 2";
CM_ SG_ 967 MO_Kuehlerluefter_MUX "Multiplexer für das Signal 'MO_Kuehlerlüfter'";
CM_ SG_ 967 MO_OBD2_Lampe "OBD bzw. MIL-Lampe wird vom Motorsteuergerät angesteuert, die Information im Signal GE_OBD_Status wird vom Motorsteuergerät an das Kombi weitergereicht";
CM_ SG_ 967 MO_Oelwarnung_max "Ölstandswarnung mit der Aufforderung zum Ölwechsel.
Hintergrund: Bei Kraftstoffeintrag (B20) ins Öl verbleibt der RME-Anteil irreversibel im Öl.";
CM_ SG_ 967 MO_Partikel_Lampe "Partikelfilter-Lampe wird eingeschaltet";
CM_ SG_ 967 MO_RedFahrleistung_Lampe "Ansteuerung der Turtle-Mode Lampe für E-Traktion Fahrzeuge";
CM_ SG_ 967 MO_Systemlampe "EGas Systemlampe (EPC) oder Vorglühlampe im Kombi, Kombi steuert immer gleiche
LED an, nur über Ziffernblatt wird die EPC von der Vorglühlampe differenziert";
CM_ SG_ 967 MO_Tankdeckel_Lampe "Ansteuerung Tankdeckel-Warnlampe Kombiinstrument (nur Ottomotoren) z.Zt. Vorhalt VW";
CM_ SG_ 967 MO_Text_Motorstart "Anzeigetexte für Start/Stopp und Motor-Start
0xB Fehler_Kupplungsschalter nur für PAG-MLB";
CM_ SG_ 967 MO_Text_Partikelfil_Reg "Über dieses Bit im Kombi wird ein Klartextanzeige erzeugt werden: 'Partikelfilter benötigt Regeneration'.
";
CM_ SG_ 967 MO_Text_Tankdeckelwarn "Textbit der Tankdeckelwarnung, z.Zt. Vorhalt VW";
CM_ SG_ 967 MO_Vorglueh_Lampe "Vorglühlampe im Kombi, Kombi steuert immer gleiche LED an. 
Mit Einführung des Einheits-Kombis sind getrennte Signalwege für Vorglühlampe und EPCL notwendig.";
CM_ SG_ 967 MO_Zustand_HWP "Rückmeldung des  Ansteuerzustand der Hauptwasserpumpe an das Klima-SG .
Der Zustand 'HWP fördert' wird übermittelt, wenn die Schaufeln der Hauptwasserpumpe frei drehen können und die Motordrehzahl und damit die Wasserpumpendrehzahl größer als Null ist. B";
CM_ SG_ 967 OLEV_Oelstand_nicht_vorhanden "Kein aktueller Ölstand vorhanden";
CM_ SG_ 967 OLEV_Systemstoerung "Systemstörung im Ölsystem";
CM_ SG_ 967 WIV_Anzeige_aktiv "Peilstabsanzeigefunktion aktiv";
CM_ SG_ 967 WIV_laufender_Motor "Messung bei laufendem Motor nicht möglich";
CM_ SG_ 967 WIV_nachfuellanzeige_ein "Steuert das Aufblenden der Nachfüllanzeige im Kombi, nach Klemme 15 ein und geöffneter Motorhaube";
CM_ SG_ 967 WIV_nicht_betriebswarm "Motor nicht betriebswarm, Messung ungenau";
CM_ SG_ 967 WIV_Oeldr_Warn_Motor "Löst im Kombiinstrument die rote Prio1-Öldruckwarnung (inkl. 3xBeep) aus.
nur MLB: die Warnauslösung erfolgt nur bei gleichzeitig gesetztem 'WIV_Enable_Oeldr_Motor'";
CM_ SG_ 967 WIV_Oeldyn_avl "Ölstand aus dynamischer Messung vorhanden";
CM_ SG_ 967 WIV_Oelmenge "Ölmenge zwischen Min und Max";
CM_ SG_ 967 WIV_Oelmin_Warn "Signal gibt an wenn der Ölstand die Min-Schwelle unterschritten hat";
CM_ SG_ 967 WIV_Oelstand "8 Segmente zur Balkenanzeige des Ölstands";
CM_ SG_ 967 WIV_Oelstand_nicht_vorhanden "Kein aktueller Ölstand vorhanden";
CM_ SG_ 967 WIV_Oelsystem_aktiv "Gesamtölsystem aktiv (entspricht Ölsensor verbaut) und das Ölstand-Untermenu im MMI aktiv";
CM_ SG_ 967 WIV_Schieflage "Fahrzeug steht nicht waagerecht, Messung ungenau";
CM_ SG_ 967 WIV_Sensorfehler "Ölstand/Öltemperatursensor (TOG) defekt";
CM_ SG_ 967 WIV_Ueberfuell_deaktiv "Unterdrückung der Warnung im Kombi die durch Signal WIV_Ueberfuel_Warn ausgelöst wird";
CM_ SG_ 967 WIV_Ueberfuell_Warn "Ölstand hat die Überfüllschwelle überschritten";
CM_ SG_ 967 WIV_Unterfuell_Warn "Ölstand hat die Unterfüllschwelle unterschritten";

CM_ SG_ 340 MO_Drehzahl_VM "Motordrehzahl des Verbrennungsmotors

für OBD freeze frame

Hinweis: 
Ehemaliger Fehlerwert 0xFFFF wird senderseitig nicht unterstützt. 
Diesen Wert aus Kompatibilitätsgründen nicht neu belegen!";
CM_ SG_ 340 MO_Fehlerstatus_Antrieb_FDR "Fehlerstatus Antrieb - FDR";
CM_ SG_ 340 MO_IstMoment_VKM "Ist-Moment des Verbrennungsmotors

einheitenloser Wert! MO_Faktor_Momente_02 in Motor_Code_01 berücksichtigen!";
CM_ SG_ 340 MO_Mom_Begr_Schalt "Einheitenloser Wert! Faktor in MO_Faktor_Momente (CAN V6.x) bzw. MO_Faktor_Momente_02 (CAN V7.x/8.x) in Motor_Code_01 beachten!

Bei aktueller Drehzahl kurzfristig (ca. 100..200 ms) für momentenerhöhende Getriebeeingriffe max. zur Verfügung stehendes Ge";
CM_ SG_ 340 MO_Mom_Begr_Schalt_Min "Bei aktueller Drehzahl im nächsten Task (im VKM Umsetzung zur nächsten möglichen Verbrennung) minmal stellbares Moment (Summe aus Verbrennungsmotor und E-Motor) aufgrund Momenten-Reduzierungs-Anforderung durch reduzierenden Getriebeeingriff.
Berücksichti";
CM_ SG_ 340 MO_Primaerachse_Anforderung "Das Signal dient der Steuerung der Primärachse. 

Anforderung zum Öffnen/Schließen der Getriebekupplungen und damit An-/Abkuppeln der Primärachse. 
Wird in MHEV-Projekten keine explizite Anforderung gesendet (Wert 0), ist die Freilaufsteuerung aus 'MO_";
CM_ SG_ 340 Motor_28_BZ "Botschaft asynchron geroutet. Zählerwert kann springen.";
CM_ SG_ 340 Motor_28_CRC "Für MLB:
'Berechnung siehe Lastenheft 'Kommunikationsabsicherung für FlexRay und CAN''

Ab MQB und MLBevo:
'Berechnung siehe Lastenheft 'End-to-End Kommunikationsabsicherung''

Endwerte siehe Begleitdokument 'S-PDU Kennungsfolgen'";

CM_ SG_ 1366 FWS_Koeffizient_2 "Von der quadratischen Geschwindigkeit abhängiger Fahrwiderstandsanteil. Details zum Signal siehe Dokument zur Signalbeschreibung";
CM_ SG_ 1366 FWS_QBit_Koeffizient_2 "Qualitätsbit zu FWS_Koeffizient_2.
Nähere Beschreibung siehe Dokument zur Signalbeschreibung";
CM_ SG_ 1366 MO_Fahrzeugabstellzeit "Zeit seit letzter Fahrbereitschaft.";
CM_ SG_ 1366 MO_Fahrzeugabstellzeit_Status "Status Fahrzeugabstellzeit";
CM_ SG_ 1366 MO_HV_Auszeit "Zeit seit letzter Hochvoltaktivität.";
CM_ SG_ 1366 MO_HV_Auszeit_Status "Status HV-Auszeit.";
CM_ SG_ 1366 MO_Verbau_StartSys_EM_HV "Signal zeigt an, welche Komponenten des Startsystemes verbaut sind.
Verbau E-Maschine HV";
CM_ SG_ 1366 MO_Verbau_StartSys_EM_MV "Signal zeigt an, welche Komponenten des Startsystemes verbaut sind.
Verbau E-Maschine MV z.B. 48V";
CM_ SG_ 1366 MO_Verbau_StartSys_Q_Diode "Signal zeigt an, welche Komponenten des Startsystemes verbaut sind.
Verbau Q_Diode";
CM_ SG_ 1366 MO_Verbau_StartSys_Ritzelstarter "Signal zeigt an, welche Komponenten des Startsystemes verbaut sind.
Verbau Ritzel Starter";
CM_ SG_ 1366 MO_Verbau_StartSys_RSG_MV "Signal zeigt an, welche Komponenten des Startsystemes verbaut sind.
Verbau Riemen Starter Generator MV z.B. 48V";
CM_ SG_ 1366 MO_Verbau_StartSys_RSG_NV "Signal zeigt an, welche Komponenten des Startsystemes verbaut sind.
Verbau Riemen Starter Generator NV z.B. 12V";
CM_ SG_ 1366 MO_Ziel_SoC_Fremdladung "Auf diesen SoC soll MHEV-Speicher geladen werden, wenn ein Ladegerät erkannt ist.";

CM_ SG_ 283 MO_EBoost_verf_praed "Zeigt an, ob für eine im Projekt definierte Zeit (max. 10s) E-Boost in Höhe von EM1_maxPred_Moment verfügbar sein wird.

0 - Init_oder_nicht_verfügbar
1 - EBoost_kurzzeit_verfügbar (~3Sek.)
2 - EBoost_langzeit_verfügbar (~10Sek)";
CM_ SG_ 283 MO_eLaunch_verf "Zeigt an, ob aus Antriebssicht E-Launch verfügbar ist.";
CM_ SG_ 283 MO_Fahrbereitschaft "Das Signal MO_Fahrbereitschaft zeigt in mehreren Stufen an, ob der Motor in einem anfahrbereiten Zustand ist.";
CM_ SG_ 283 MO_Freilauf_Info "Freilauf Informationssignal vom Motorsteuergerät zum Getriebesteuergerät. Das Motorsteuergerät kann über dieses Signal den Freilauf freigeben, verhindern bzw. explizit anfordern.";
CM_ SG_ 283 MO_Freilauf_Status "Freilauf-Status-Signal vom Frailauf-Master an aktive Freilauf-Teilnehmer. In diesem Signal zeigt der Freilauf-Master an, welchen aktuellen Status die Freilauf-Betriebsstrategie hat.";
CM_ SG_ 283 MO_Heckspoiler_Anf "Anforderung den Heckspoiler zur Ladeluft- bzw. Motorraumkühlung auszufahren.";
CM_ SG_ 283 MO_Krit_Heckobjekt "Beschreibt die Kritikalität des hinter einem in der Spur fahrenden Fahrzeuges";
CM_ SG_ 283 MO_NGS_Gangpos "Gang- bzw. Neutralinformation des erweiterten Neutralgangsensors. Bedingt durch den eingeschränkten Erfassungssbereich des Sensors sind die Ganginformationen als eingelegt bzw. fast eingelegt/vorausgewählt zu interpretieren (nur Handschalter)";
CM_ SG_ 283 MO_Parken_WFS_Status "Gesammelte Rückmeldung des Limitierungsstatus aller EM in einem vom ZFAS angeforderten Parkvorgang.";
CM_ SG_ 283 MO_Positionierung_aktiv "Zeigt an, dass die Motorpositionierung mit Hilfe des Riemenstartergenerator momentan aktiv ist.";

CM_ SG_ 2527679581 MO_Abwurfschwelle_Charge "Signalisiert den Offset auf das Signal BMS_SOC_Max bei dem der Charge-Mode von der BS abgeworfen wird";
CM_ SG_ 2527679581 MO_Abwurfschwelle_EV "Signalisiert den Offset auf das Signal BMS_SOC_Kaltstart bei dem der EV-Mode von der BS abgeworfen wird";
CM_ SG_ 2527679581 MO_Anf_KJS_1 "Ansteuersollwert  Kühlerjalousie (motoreigene Bedarfe)";
CM_ SG_ 2527679581 MO_Hysterese_Reakt_Charge "Signalisiert die Hysterese auf die MO_Abwurfschwelle_Charge ab welcher der Charge-Mode wieder reaktiviert werden kann";
CM_ SG_ 2527679581 MO_Hysterese_Reakt_EV "Signalisiert die Hysterese auf die MO_Abwurfschwelle_EV ab welcher der EV-Mode wieder reaktiviert werden kann";
CM_ SG_ 2527679581 MO_TME_KL_Anf "Lüfteranforderung DME->TME.
Max-Auswahl aus TME Lüfteranforderung + SKE positionsabhängiger Offset.";

CM_ SG_ 377 MO_Soll_NutzbarerSOC "Der Sollwert für den Kunden-Nutzbaren-SOC bei einer SOC-steuernden Betriebsstrategie";
BA_DEF_REL_ BU_SG_REL_  "GenSigTimeoutTime" INT 0 65535;
BA_DEF_ BO_  "DiagRequest" ENUM "No", "Yes";
BA_DEF_ BO_  "DiagResponse" ENUM "No", "Yes";
BA_DEF_ BO_  "DiagState" ENUM "No", "Yes";
BA_DEF_ BO_  "GenMsgChkConstant" HEX 0 4095;
BA_DEF_ BO_  "GenMsgCycleTime" INT 0 65535;
BA_DEF_ BO_  "GenMsgCycleTimeFast" INT 0 65535;
BA_DEF_ BO_  "GenMsgDelayTime" INT 0 100000;
BA_DEF_ BO_  "GenMsgILSupport" ENUM "No", "Yes";
BA_DEF_ BO_  "GenMsgNrOfRepetition" INT 0 100;
BA_DEF_ BO_  "GenMsgPDUConstants" STRING;
BA_DEF_ BO_  "GenMsgSendType" ENUM "Cyclic", "not_used", "not_used", "not_used", "not_used", "not_used", "not_used", "IfActive", "NoMsgSendType";
BA_DEF_ BO_  "GenMsgStartDelayTime" INT 0 100000;
BA_DEF_ BO_  "NmMessage" ENUM "No", "Yes";
BA_DEF_ BO_  "NmhMessage" ENUM "No", "Yes";
BA_DEF_ BO_  "MsgType" ENUM "Application", "NM ", "NMH", "TP2.0", "ISO-TP ", "BAP", "EID", "KS";
BA_DEF_ BO_  "VAGTP20_API" HEX 0 255;
BA_DEF_ BO_  "VAGTP20_DynConnection" ENUM "No", "Yes";
BA_DEF_ BO_  "VAGTP20_DynSetup" ENUM "No", "Yes";
BA_DEF_ BO_  "VAGTP20_StatConnection" ENUM "No", "Yes";
BA_DEF_ SG_  "GenSigActiveRepetitions" INT -2147483648 2147483647;
BA_DEF_ SG_  "GenSigInactiveValue" INT -2147483648 2147483647;
BA_DEF_ SG_  "GenSigSendType" ENUM "Cyclic", "OnWrite", "OnWriteWithRepetition", "OnChange", "OnChangeWithRepetition", "IfActive", "IfActiveWithRepetition", "NoSigSendType", "OnChangeAndIfActive", "OnChangeAndIfActiveWithRepetition";
BA_DEF_ SG_  "GenSigStartValue" INT -2147483648 2147483647;
BA_DEF_ SG_  "NWM-WakeupAllowed" ENUM "No", "Yes";
BA_DEF_ SG_  "GenSigFuncType" ENUM "NoFunction", "MsgCounter", "CRC-8", "XOR", "XOR-2", "DatedBit", "SW-Kl15", "CHK", "Constant", "Protocol", "CRC-8-SAE_J1850";
BA_DEF_ SG_  "GenSigSwitchedByIgnition" ENUM "No", "Yes";
BA_DEF_ SG_  "Fehlerwert" HEX 0 2147483647;
BA_DEF_ SG_  "GenSigMissingSourceValue" HEX 0 2147483647;
BA_DEF_DEF_REL_  "GenSigTimeoutTime" 0;
BA_DEF_DEF_  "DiagRequest" "No";
BA_DEF_DEF_  "DiagResponse" "No";
BA_DEF_DEF_  "DiagState" "No";
BA_DEF_DEF_  "GenMsgChkConstant" 0;
BA_DEF_DEF_  "GenMsgCycleTime" 0;
BA_DEF_DEF_  "GenMsgCycleTimeFast" 0;
BA_DEF_DEF_  "GenMsgDelayTime" 0;
BA_DEF_DEF_  "GenMsgILSupport" "No";
BA_DEF_DEF_  "GenMsgNrOfRepetition" 0;
BA_DEF_DEF_  "GenMsgPDUConstants" "";
BA_DEF_DEF_  "GenMsgSendType" "NoMsgSendType";
BA_DEF_DEF_  "GenMsgStartDelayTime" 0;
BA_DEF_DEF_  "NmMessage" "No";
BA_DEF_DEF_  "NmhMessage" "No";
BA_DEF_DEF_  "MsgType" "Application";
BA_DEF_DEF_  "VAGTP20_API" 0;
BA_DEF_DEF_  "VAGTP20_DynConnection" "No";
BA_DEF_DEF_  "VAGTP20_DynSetup" "No";
BA_DEF_DEF_  "VAGTP20_StatConnection" "No";
BA_DEF_DEF_  "GenSigActiveRepetitions" 0;
BA_DEF_DEF_  "GenSigInactiveValue" 0;
BA_DEF_DEF_  "GenSigSendType" "NoSigSendType";
BA_DEF_DEF_  "GenSigStartValue" 0;
BA_DEF_DEF_  "NWM-WakeupAllowed" "No";
BA_DEF_DEF_  "GenSigFuncType" "NoFunction";
BA_DEF_DEF_  "GenSigSwitchedByIgnition" "Yes";
BA_DEF_DEF_  "Fehlerwert" 0;
BA_DEF_DEF_  "GenSigMissingSourceValue" 0;
BA_ "GenMsgChkConstant" BO_ 1662 37;
BA_ "GenMsgCycleTime" BO_ 1662 1000;
BA_ "GenMsgDelayTime" BO_ 1662 50;
BA_ "GenMsgILSupport" BO_ 1662 1;
BA_ "GenMsgPDUConstants" BO_ 1662 "0x25,0x25,0x25,0x25,0x25,0x25,0x25,0x25,0x25,0x25,0x25,0x25,0x25,0x25,0x25,0x25";
BA_ "GenMsgSendType" BO_ 1662 0;
BA_ "GenMsgCycleTime" BO_ 2463978642 100;
BA_ "GenMsgILSupport" BO_ 2463978642 1;
BA_ "GenMsgSendType" BO_ 2463978642 0;
BA_ "GenMsgCycleTime" BO_ 2463978643 100;
BA_ "GenMsgILSupport" BO_ 2463978643 1;
BA_ "GenMsgPDUConstants" BO_ 2463978643 "0x74,0x7e,0x45,0xe8,0x3c,0xd0,0x13,0x1f,0x4e,0x3a,0x88,0x0b,0x7d,0xd2,0x6d,0xab";
BA_ "GenMsgSendType" BO_ 2463978643 0;
BA_ "GenMsgCycleTime" BO_ 2589283663 1000;
BA_ "GenMsgILSupport" BO_ 2589283663 1;
BA_ "GenMsgSendType" BO_ 2589283663 0;
BA_ "GenMsgCycleTime" BO_ 2589283415 1000;
BA_ "GenMsgILSupport" BO_ 2589283415 1;
BA_ "GenMsgSendType" BO_ 2589283415 0;
BA_ "GenMsgCycleTime" BO_ 2589283472 500;
BA_ "GenMsgILSupport" BO_ 2589283472 1;
BA_ "GenMsgSendType" BO_ 2589283472 0;
BA_ "GenMsgCycleTime" BO_ 2589283473 500;
BA_ "GenMsgILSupport" BO_ 2589283473 1;
BA_ "GenMsgSendType" BO_ 2589283473 0;
BA_ "GenMsgCycleTime" BO_ 2589283481 500;
BA_ "GenMsgILSupport" BO_ 2589283481 1;
BA_ "GenMsgSendType" BO_ 2589283481 0;
BA_ "GenMsgCycleTime" BO_ 160 100;
BA_ "GenMsgILSupport" BO_ 160 1;
BA_ "GenMsgPDUConstants" BO_ 160 "0x4a,0xb4,0xe8,0x24,0x99,0x5a,0x59,0x8b,0x1e,0xaa,0x94,0xb6,0x09,0xd5,0xaf,0x97";
BA_ "GenMsgSendType" BO_ 160 0;
BA_ "GenMsgCycleTime" BO_ 1600 320;
BA_ "GenMsgILSupport" BO_ 1600 1;
BA_ "GenMsgSendType" BO_ 1600 0;
BA_ "GenMsgCycleTime" BO_ 1607 320;
BA_ "GenMsgILSupport" BO_ 1607 1;
BA_ "GenMsgSendType" BO_ 1607 0;
BA_ "GenMsgCycleTime" BO_ 168 10;
BA_ "GenMsgILSupport" BO_ 168 1;
BA_ "GenMsgPDUConstants" BO_ 168 "0x52,0x8c,0x50,0xee,0x4f,0xa6,0xcc,0xcf,0x7d,0x2f,0x98,0x6b,0x27,0x41,0x9f,0x93";
BA_ "GenMsgSendType" BO_ 168 0;
BA_ "GenMsgCycleTime" BO_ 958 100;
BA_ "GenMsgDelayTime" BO_ 958 10;
BA_ "GenMsgILSupport" BO_ 958 1;
BA_ "GenMsgPDUConstants" BO_ 958 "0x1f,0x28,0xc6,0x85,0xe6,0xf8,0xb0,0x19,0x5b,0x64,0x35,0x21,0xe4,0xf7,0x9c,0x24";
BA_ "GenMsgSendType" BO_ 958 0;
BA_ "GenMsgCycleTime" BO_ 812 200;
BA_ "GenMsgDelayTime" BO_ 812 40;
BA_ "GenMsgILSupport" BO_ 812 1;
BA_ "GenMsgSendType" BO_ 812 0;
BA_ "GenMsgCycleTime" BO_ 1648 500;
BA_ "GenMsgDelayTime" BO_ 1648 20;
BA_ "GenMsgILSupport" BO_ 1648 1;
BA_ "GenMsgSendType" BO_ 1648 0;
BA_ "GenMsgCycleTime" BO_ 1423 320;
BA_ "GenMsgILSupport" BO_ 1423 1;
BA_ "GenMsgSendType" BO_ 1423 0;
BA_ "GenMsgCycleTime" BO_ 967 80;
BA_ "GenMsgILSupport" BO_ 967 1;
BA_ "GenMsgSendType" BO_ 967 0;
BA_ "GenMsgCycleTime" BO_ 340 200;
BA_ "GenMsgILSupport" BO_ 340 1;
BA_ "GenMsgPDUConstants" BO_ 340 "0x21,0x93,0x4a,0x04,0x5c,0x18,0xe0,0x69,0x14,0xce,0x26,0x8f,0x5e,0xb1,0xdf,0x53";
BA_ "GenMsgSendType" BO_ 340 0;
BA_ "GenMsgCycleTime" BO_ 1366 960;
BA_ "GenMsgILSupport" BO_ 1366 1;
BA_ "GenMsgSendType" BO_ 1366 0;
BA_ "GenMsgCycleTime" BO_ 283 500;
BA_ "GenMsgDelayTime" BO_ 283 10;
BA_ "GenMsgILSupport" BO_ 283 1;
BA_ "GenMsgSendType" BO_ 283 0;
BA_ "GenMsgCycleTime" BO_ 2527679581 320;
BA_ "GenMsgILSupport" BO_ 2527679581 1;
BA_ "GenMsgSendType" BO_ 2527679581 0;
BA_ "GenMsgCycleTime" BO_ 377 100;
BA_ "GenMsgDelayTime" BO_ 377 10;
BA_ "GenMsgILSupport" BO_ 377 1;
BA_ "GenMsgSendType" BO_ 377 0;
BA_ "GenSigSendType" SG_ 1662 LAD_02_BZ 0;
BA_ "GenSigFuncType" SG_ 1662 LAD_02_BZ 1;
BA_ "GenSigSwitchedByIgnition" SG_ 1662 LAD_02_BZ 0;
BA_ "GenSigSendType" SG_ 1662 LAD_02_CRC 0;
BA_ "GenSigFuncType" SG_ 1662 LAD_02_CRC 2;
BA_ "GenSigSwitchedByIgnition" SG_ 1662 LAD_02_CRC 0;
BA_ "GenSigSendType" SG_ 1662 LAD_Abregelung_BuchseTemp 0;
BA_ "GenSigSwitchedByIgnition" SG_ 1662 LAD_Abregelung_BuchseTemp 0;
BA_ "GenSigSendType" SG_ 1662 LAD_Abregelung_IU_Ein_Aus 0;
BA_ "GenSigSwitchedByIgnition" SG_ 1662 LAD_Abregelung_IU_Ein_Aus 0;
BA_ "GenSigSendType" SG_ 1662 LAD_Abregelung_Temperatur 0;
BA_ "GenSigSwitchedByIgnition" SG_ 1662 LAD_Abregelung_Temperatur 0;
BA_ "GenSigSendType" SG_ 1662 LAD_CP_Erkennung 3;
BA_ "GenSigSwitchedByIgnition" SG_ 1662 LAD_CP_Erkennung 0;
BA_ "GenSigSendType" SG_ 1662 LAD_Fehlerzustand 0;
BA_ "GenSigSwitchedByIgnition" SG_ 1662 LAD_Fehlerzustand 0;
BA_ "GenSigSendType" SG_ 1662 LAD_Kuehlbedarf 0;
BA_ "GenSigSwitchedByIgnition" SG_ 1662 LAD_Kuehlbedarf 0;
BA_ "GenSigSendType" SG_ 1662 LAD_MaxLadLeistung_HV 0;
BA_ "GenSigStartValue" SG_ 1662 LAD_MaxLadLeistung_HV 510;
BA_ "GenSigSwitchedByIgnition" SG_ 1662 LAD_MaxLadLeistung_HV 0;
BA_ "Fehlerwert" SG_ 1662 LAD_MaxLadLeistung_HV 511;
BA_ "GenSigSendType" SG_ 1662 LAD_MaxLadLeistung_HV_Offset 0;
BA_ "GenSigSwitchedByIgnition" SG_ 1662 LAD_MaxLadLeistung_HV_Offset 0;
BA_ "GenSigSendType" SG_ 1662 LAD_PRX_Stromlimit 0;
BA_ "GenSigStartValue" SG_ 1662 LAD_PRX_Stromlimit 6;
BA_ "GenSigSwitchedByIgnition" SG_ 1662 LAD_PRX_Stromlimit 0;
BA_ "Fehlerwert" SG_ 1662 LAD_PRX_Stromlimit 7;
BA_ "GenSigSendType" SG_ 1662 LAD_Stecker_Verriegelt 0;
BA_ "GenSigSwitchedByIgnition" SG_ 1662 LAD_Stecker_Verriegelt 0;
BA_ "GenSigSendType" SG_ 1662 LAD_Warnzustand 0;
BA_ "GenSigSwitchedByIgnition" SG_ 1662 LAD_Warnzustand 0;
BA_ "GenSigSendType" SG_ 2463978642 LAD_SollStrom_HV_Pfad1 0;
BA_ "GenSigStartValue" SG_ 2463978642 LAD_SollStrom_HV_Pfad1 254;
BA_ "GenSigSwitchedByIgnition" SG_ 2463978642 LAD_SollStrom_HV_Pfad1 0;
BA_ "Fehlerwert" SG_ 2463978642 LAD_SollStrom_HV_Pfad1 255;
BA_ "GenSigSendType" SG_ 2463978642 LAD_SollStrom_HV_Pfad2 0;
BA_ "GenSigStartValue" SG_ 2463978642 LAD_SollStrom_HV_Pfad2 254;
BA_ "GenSigSwitchedByIgnition" SG_ 2463978642 LAD_SollStrom_HV_Pfad2 0;
BA_ "Fehlerwert" SG_ 2463978642 LAD_SollStrom_HV_Pfad2 255;
BA_ "GenSigSendType" SG_ 2463978642 LAD_SollStrom_HV_Pfad3 0;
BA_ "GenSigStartValue" SG_ 2463978642 LAD_SollStrom_HV_Pfad3 254;
BA_ "GenSigSwitchedByIgnition" SG_ 2463978642 LAD_SollStrom_HV_Pfad3 0;
BA_ "Fehlerwert" SG_ 2463978642 LAD_SollStrom_HV_Pfad3 255;
BA_ "GenSigSendType" SG_ 2463978643 LAD_05_BZ 0;
BA_ "GenSigFuncType" SG_ 2463978643 LAD_05_BZ 1;
BA_ "GenSigSwitchedByIgnition" SG_ 2463978643 LAD_05_BZ 0;
BA_ "GenSigSendType" SG_ 2463978643 LAD_05_CRC 0;
BA_ "GenSigFuncType" SG_ 2463978643 LAD_05_CRC 2;
BA_ "GenSigSwitchedByIgnition" SG_ 2463978643 LAD_05_CRC 0;
BA_ "GenSigSendType" SG_ 2463978643 LAD_AC_MaxStrom_L1 0;
BA_ "GenSigStartValue" SG_ 2463978643 LAD_AC_MaxStrom_L1 1022;
BA_ "GenSigSwitchedByIgnition" SG_ 2463978643 LAD_AC_MaxStrom_L1 0;
BA_ "Fehlerwert" SG_ 2463978643 LAD_AC_MaxStrom_L1 1023;
BA_ "GenSigSendType" SG_ 2463978643 LAD_AC_MaxStrom_L2 0;
BA_ "GenSigStartValue" SG_ 2463978643 LAD_AC_MaxStrom_L2 1022;
BA_ "GenSigSwitchedByIgnition" SG_ 2463978643 LAD_AC_MaxStrom_L2 0;
BA_ "Fehlerwert" SG_ 2463978643 LAD_AC_MaxStrom_L2 1023;
BA_ "GenSigSendType" SG_ 2463978643 LAD_AC_MaxStrom_L3 0;
BA_ "GenSigStartValue" SG_ 2463978643 LAD_AC_MaxStrom_L3 1022;
BA_ "GenSigSwitchedByIgnition" SG_ 2463978643 LAD_AC_MaxStrom_L3 0;
BA_ "Fehlerwert" SG_ 2463978643 LAD_AC_MaxStrom_L3 1023;
BA_ "GenSigSendType" SG_ 2463978643 LAD_Freigabe_LAD2 0;
BA_ "GenSigSwitchedByIgnition" SG_ 2463978643 LAD_Freigabe_LAD2 0;
BA_ "GenSigSendType" SG_ 2463978643 LAD_Max_LadeSpannung_LAD2 0;
BA_ "GenSigStartValue" SG_ 2463978643 LAD_Max_LadeSpannung_LAD2 1022;
BA_ "GenSigSwitchedByIgnition" SG_ 2463978643 LAD_Max_LadeSpannung_LAD2 0;
BA_ "Fehlerwert" SG_ 2463978643 LAD_Max_LadeSpannung_LAD2 1023;
BA_ "GenSigSendType" SG_ 2589283663 LAD_PlanAntw_Verlustleistung 0;
BA_ "GenSigStartValue" SG_ 2589283663 LAD_PlanAntw_Verlustleistung 4094;
BA_ "GenSigSwitchedByIgnition" SG_ 2589283663 LAD_PlanAntw_Verlustleistung 0;
BA_ "Fehlerwert" SG_ 2589283663 LAD_PlanAntw_Verlustleistung 4095;
BA_ "GenSigSendType" SG_ 2589283663 LAD_PlanAntw_Zaehler 0;
BA_ "GenSigStartValue" SG_ 2589283663 LAD_PlanAntw_Zaehler 14;
BA_ "GenSigSwitchedByIgnition" SG_ 2589283663 LAD_PlanAntw_Zaehler 0;
BA_ "Fehlerwert" SG_ 2589283663 LAD_PlanAntw_Zaehler 15;
BA_ "GenSigSendType" SG_ 2589283415 LAD_CALID_CVN_MUX 0;
BA_ "GenSigSwitchedByIgnition" SG_ 2589283415 LAD_CALID_CVN_MUX 0;
BA_ "GenSigStartValue" SG_ 2589283415 LAD_CALID_Index_01 48;
BA_ "GenSigSwitchedByIgnition" SG_ 2589283415 LAD_CALID_Index_01 0;
BA_ "GenSigStartValue" SG_ 2589283415 LAD_CALID_Index_02 48;
BA_ "GenSigSwitchedByIgnition" SG_ 2589283415 LAD_CALID_Index_02 0;
BA_ "GenSigStartValue" SG_ 2589283415 LAD_CALID_Index_03 48;
BA_ "GenSigSwitchedByIgnition" SG_ 2589283415 LAD_CALID_Index_03 0;
BA_ "GenSigStartValue" SG_ 2589283415 LAD_CALID_Index_04 48;
BA_ "GenSigSwitchedByIgnition" SG_ 2589283415 LAD_CALID_Index_04 0;
BA_ "GenSigStartValue" SG_ 2589283415 LAD_CALID_Index_05 48;
BA_ "GenSigSwitchedByIgnition" SG_ 2589283415 LAD_CALID_Index_05 0;
BA_ "GenSigStartValue" SG_ 2589283415 LAD_CALID_Index_06 48;
BA_ "GenSigSwitchedByIgnition" SG_ 2589283415 LAD_CALID_Index_06 0;
BA_ "GenSigStartValue" SG_ 2589283415 LAD_CALID_Index_07 48;
BA_ "GenSigSwitchedByIgnition" SG_ 2589283415 LAD_CALID_Index_07 0;
BA_ "GenSigStartValue" SG_ 2589283415 LAD_CALID_Index_08 48;
BA_ "GenSigSwitchedByIgnition" SG_ 2589283415 LAD_CALID_Index_08 0;
BA_ "GenSigStartValue" SG_ 2589283415 LAD_CALID_Index_09 48;
BA_ "GenSigSwitchedByIgnition" SG_ 2589283415 LAD_CALID_Index_09 0;
BA_ "GenSigStartValue" SG_ 2589283415 LAD_CALID_Index_10 48;
BA_ "GenSigSwitchedByIgnition" SG_ 2589283415 LAD_CALID_Index_10 0;
BA_ "GenSigStartValue" SG_ 2589283415 LAD_CALID_Index_11 48;
BA_ "GenSigSwitchedByIgnition" SG_ 2589283415 LAD_CALID_Index_11 0;
BA_ "GenSigStartValue" SG_ 2589283415 LAD_CALID_Index_12 48;
BA_ "GenSigSwitchedByIgnition" SG_ 2589283415 LAD_CALID_Index_12 0;
BA_ "GenSigStartValue" SG_ 2589283415 LAD_CALID_Index_13 48;
BA_ "GenSigSwitchedByIgnition" SG_ 2589283415 LAD_CALID_Index_13 0;
BA_ "GenSigStartValue" SG_ 2589283415 LAD_CALID_Index_14 48;
BA_ "GenSigSwitchedByIgnition" SG_ 2589283415 LAD_CALID_Index_14 0;
BA_ "GenSigStartValue" SG_ 2589283415 LAD_CALID_Index_15 48;
BA_ "GenSigSwitchedByIgnition" SG_ 2589283415 LAD_CALID_Index_15 0;
BA_ "GenSigStartValue" SG_ 2589283415 LAD_CALID_Index_16 48;
BA_ "GenSigSwitchedByIgnition" SG_ 2589283415 LAD_CALID_Index_16 0;
BA_ "GenSigSwitchedByIgnition" SG_ 2589283415 LAD_CVN_Byte_1 0;
BA_ "GenSigSwitchedByIgnition" SG_ 2589283415 LAD_CVN_Byte_2 0;
BA_ "GenSigSwitchedByIgnition" SG_ 2589283415 LAD_CVN_Byte_3 0;
BA_ "GenSigSwitchedByIgnition" SG_ 2589283415 LAD_CVN_Byte_4 0;
BA_ "GenSigSendType" SG_ 2589283415 LAD_CVN_VLD 0;
BA_ "GenSigSwitchedByIgnition" SG_ 2589283415 LAD_CVN_VLD 0;
BA_ "GenSigSendType" SG_ 2589283472 LAD_KomponentenFehler_01 0;
BA_ "GenSigStartValue" SG_ 2589283472 LAD_KomponentenFehler_01 2;
BA_ "GenSigSwitchedByIgnition" SG_ 2589283472 LAD_KomponentenFehler_01 0;
BA_ "GenSigSendType" SG_ 2589283472 LAD_KomponentenFehler_02 0;
BA_ "GenSigStartValue" SG_ 2589283472 LAD_KomponentenFehler_02 2;
BA_ "GenSigSwitchedByIgnition" SG_ 2589283472 LAD_KomponentenFehler_02 0;
BA_ "GenSigSendType" SG_ 2589283472 LAD_KomponentenFehler_03 0;
BA_ "GenSigStartValue" SG_ 2589283472 LAD_KomponentenFehler_03 2;
BA_ "GenSigSwitchedByIgnition" SG_ 2589283472 LAD_KomponentenFehler_03 0;
BA_ "GenSigSendType" SG_ 2589283472 LAD_KomponentenFehler_04 0;
BA_ "GenSigStartValue" SG_ 2589283472 LAD_KomponentenFehler_04 2;
BA_ "GenSigSwitchedByIgnition" SG_ 2589283472 LAD_KomponentenFehler_04 0;
BA_ "GenSigSendType" SG_ 2589283472 LAD_KomponentenFehler_05 0;
BA_ "GenSigStartValue" SG_ 2589283472 LAD_KomponentenFehler_05 2;
BA_ "GenSigSwitchedByIgnition" SG_ 2589283472 LAD_KomponentenFehler_05 0;
BA_ "GenSigSendType" SG_ 2589283472 LAD_KomponentenFehler_06 0;
BA_ "GenSigStartValue" SG_ 2589283472 LAD_KomponentenFehler_06 2;
BA_ "GenSigSwitchedByIgnition" SG_ 2589283472 LAD_KomponentenFehler_06 0;
BA_ "GenSigSendType" SG_ 2589283472 LAD_KomponentenFehler_07 0;
BA_ "GenSigStartValue" SG_ 2589283472 LAD_KomponentenFehler_07 2;
BA_ "GenSigSwitchedByIgnition" SG_ 2589283472 LAD_KomponentenFehler_07 0;
BA_ "GenSigSendType" SG_ 2589283472 LAD_KomponentenFehler_08 0;
BA_ "GenSigStartValue" SG_ 2589283472 LAD_KomponentenFehler_08 2;
BA_ "GenSigSwitchedByIgnition" SG_ 2589283472 LAD_KomponentenFehler_08 0;
BA_ "GenSigSendType" SG_ 2589283472 LAD_KomponentenFehler_09 0;
BA_ "GenSigStartValue" SG_ 2589283472 LAD_KomponentenFehler_09 2;
BA_ "GenSigSwitchedByIgnition" SG_ 2589283472 LAD_KomponentenFehler_09 0;
BA_ "GenSigSendType" SG_ 2589283472 LAD_KomponentenFehler_10 0;
BA_ "GenSigStartValue" SG_ 2589283472 LAD_KomponentenFehler_10 2;
BA_ "GenSigSwitchedByIgnition" SG_ 2589283472 LAD_KomponentenFehler_10 0;
BA_ "GenSigSendType" SG_ 2589283472 LAD_KomponentenFehler_11 0;
BA_ "GenSigStartValue" SG_ 2589283472 LAD_KomponentenFehler_11 2;
BA_ "GenSigSwitchedByIgnition" SG_ 2589283472 LAD_KomponentenFehler_11 0;
BA_ "GenSigSendType" SG_ 2589283472 LAD_KomponentenFehler_12 0;
BA_ "GenSigStartValue" SG_ 2589283472 LAD_KomponentenFehler_12 2;
BA_ "GenSigSwitchedByIgnition" SG_ 2589283472 LAD_KomponentenFehler_12 0;
BA_ "GenSigSendType" SG_ 2589283472 LAD_KomponentenFehler_13 0;
BA_ "GenSigStartValue" SG_ 2589283472 LAD_KomponentenFehler_13 2;
BA_ "GenSigSwitchedByIgnition" SG_ 2589283472 LAD_KomponentenFehler_13 0;
BA_ "GenSigSendType" SG_ 2589283472 LAD_KomponentenFehler_14 0;
BA_ "GenSigStartValue" SG_ 2589283472 LAD_KomponentenFehler_14 2;
BA_ "GenSigSwitchedByIgnition" SG_ 2589283472 LAD_KomponentenFehler_14 0;
BA_ "GenSigSendType" SG_ 2589283472 LAD_KomponentenFehler_15 0;
BA_ "GenSigStartValue" SG_ 2589283472 LAD_KomponentenFehler_15 2;
BA_ "GenSigSwitchedByIgnition" SG_ 2589283472 LAD_KomponentenFehler_15 0;
BA_ "GenSigSendType" SG_ 2589283472 LAD_KomponentenFehler_16 0;
BA_ "GenSigStartValue" SG_ 2589283472 LAD_KomponentenFehler_16 2;
BA_ "GenSigSwitchedByIgnition" SG_ 2589283472 LAD_KomponentenFehler_16 0;
BA_ "GenSigSendType" SG_ 2589283472 LAD_KomponentenFehler_17 0;
BA_ "GenSigStartValue" SG_ 2589283472 LAD_KomponentenFehler_17 2;
BA_ "GenSigSwitchedByIgnition" SG_ 2589283472 LAD_KomponentenFehler_17 0;
BA_ "GenSigSendType" SG_ 2589283472 LAD_KomponentenFehler_18 0;
BA_ "GenSigStartValue" SG_ 2589283472 LAD_KomponentenFehler_18 2;
BA_ "GenSigSwitchedByIgnition" SG_ 2589283472 LAD_KomponentenFehler_18 0;
BA_ "GenSigSendType" SG_ 2589283472 LAD_KomponentenFehler_19 0;
BA_ "GenSigStartValue" SG_ 2589283472 LAD_KomponentenFehler_19 2;
BA_ "GenSigSwitchedByIgnition" SG_ 2589283472 LAD_KomponentenFehler_19 0;
BA_ "GenSigSendType" SG_ 2589283472 LAD_KomponentenFehler_20 0;
BA_ "GenSigStartValue" SG_ 2589283472 LAD_KomponentenFehler_20 2;
BA_ "GenSigSwitchedByIgnition" SG_ 2589283472 LAD_KomponentenFehler_20 0;
BA_ "GenSigSendType" SG_ 2589283472 LAD_KomponentenFehler_21 0;
BA_ "GenSigStartValue" SG_ 2589283472 LAD_KomponentenFehler_21 2;
BA_ "GenSigSwitchedByIgnition" SG_ 2589283472 LAD_KomponentenFehler_21 0;
BA_ "GenSigSendType" SG_ 2589283472 LAD_KomponentenFehler_22 0;
BA_ "GenSigStartValue" SG_ 2589283472 LAD_KomponentenFehler_22 2;
BA_ "GenSigSwitchedByIgnition" SG_ 2589283472 LAD_KomponentenFehler_22 0;
BA_ "GenSigSendType" SG_ 2589283472 LAD_KomponentenFehler_23 0;
BA_ "GenSigStartValue" SG_ 2589283472 LAD_KomponentenFehler_23 2;
BA_ "GenSigSwitchedByIgnition" SG_ 2589283472 LAD_KomponentenFehler_23 0;
BA_ "GenSigSendType" SG_ 2589283472 LAD_KomponentenFehler_24 0;
BA_ "GenSigStartValue" SG_ 2589283472 LAD_KomponentenFehler_24 2;
BA_ "GenSigSwitchedByIgnition" SG_ 2589283472 LAD_KomponentenFehler_24 0;
BA_ "GenSigSendType" SG_ 2589283472 LAD_KomponentenFehler_25 0;
BA_ "GenSigStartValue" SG_ 2589283472 LAD_KomponentenFehler_25 2;
BA_ "GenSigSwitchedByIgnition" SG_ 2589283472 LAD_KomponentenFehler_25 0;
BA_ "GenSigSendType" SG_ 2589283472 LAD_KomponentenFehler_26 0;
BA_ "GenSigStartValue" SG_ 2589283472 LAD_KomponentenFehler_26 2;
BA_ "GenSigSwitchedByIgnition" SG_ 2589283472 LAD_KomponentenFehler_26 0;
BA_ "GenSigSendType" SG_ 2589283472 LAD_KomponentenFehler_27 0;
BA_ "GenSigStartValue" SG_ 2589283472 LAD_KomponentenFehler_27 2;
BA_ "GenSigSwitchedByIgnition" SG_ 2589283472 LAD_KomponentenFehler_27 0;
BA_ "GenSigSendType" SG_ 2589283472 LAD_KomponentenFehler_28 0;
BA_ "GenSigStartValue" SG_ 2589283472 LAD_KomponentenFehler_28 2;
BA_ "GenSigSwitchedByIgnition" SG_ 2589283472 LAD_KomponentenFehler_28 0;
BA_ "GenSigSendType" SG_ 2589283472 LAD_KomponentenFehler_29 0;
BA_ "GenSigStartValue" SG_ 2589283472 LAD_KomponentenFehler_29 2;
BA_ "GenSigSwitchedByIgnition" SG_ 2589283472 LAD_KomponentenFehler_29 0;
BA_ "GenSigSendType" SG_ 2589283472 LAD_KomponentenFehler_30 0;
BA_ "GenSigStartValue" SG_ 2589283472 LAD_KomponentenFehler_30 2;
BA_ "GenSigSwitchedByIgnition" SG_ 2589283472 LAD_KomponentenFehler_30 0;
BA_ "GenSigSendType" SG_ 2589283472 LAD_KomponentenFehler_31 0;
BA_ "GenSigStartValue" SG_ 2589283472 LAD_KomponentenFehler_31 2;
BA_ "GenSigSwitchedByIgnition" SG_ 2589283472 LAD_KomponentenFehler_31 0;
BA_ "GenSigSendType" SG_ 2589283472 LAD_KomponentenFehler_32 0;
BA_ "GenSigStartValue" SG_ 2589283472 LAD_KomponentenFehler_32 2;
BA_ "GenSigSwitchedByIgnition" SG_ 2589283472 LAD_KomponentenFehler_32 0;
BA_ "GenSigSendType" SG_ 2589283473 LAD_KomponentenFehler_33 0;
BA_ "GenSigStartValue" SG_ 2589283473 LAD_KomponentenFehler_33 2;
BA_ "GenSigSwitchedByIgnition" SG_ 2589283473 LAD_KomponentenFehler_33 0;
BA_ "GenSigSendType" SG_ 2589283473 LAD_KomponentenFehler_34 0;
BA_ "GenSigStartValue" SG_ 2589283473 LAD_KomponentenFehler_34 2;
BA_ "GenSigSwitchedByIgnition" SG_ 2589283473 LAD_KomponentenFehler_34 0;
BA_ "GenSigSendType" SG_ 2589283473 LAD_KomponentenFehler_35 0;
BA_ "GenSigStartValue" SG_ 2589283473 LAD_KomponentenFehler_35 2;
BA_ "GenSigSwitchedByIgnition" SG_ 2589283473 LAD_KomponentenFehler_35 0;
BA_ "GenSigSendType" SG_ 2589283473 LAD_KomponentenFehler_36 0;
BA_ "GenSigStartValue" SG_ 2589283473 LAD_KomponentenFehler_36 2;
BA_ "GenSigSwitchedByIgnition" SG_ 2589283473 LAD_KomponentenFehler_36 0;
BA_ "GenSigSendType" SG_ 2589283473 LAD_KomponentenFehler_37 0;
BA_ "GenSigStartValue" SG_ 2589283473 LAD_KomponentenFehler_37 2;
BA_ "GenSigSwitchedByIgnition" SG_ 2589283473 LAD_KomponentenFehler_37 0;
BA_ "GenSigSendType" SG_ 2589283473 LAD_KomponentenFehler_38 0;
BA_ "GenSigStartValue" SG_ 2589283473 LAD_KomponentenFehler_38 2;
BA_ "GenSigSwitchedByIgnition" SG_ 2589283473 LAD_KomponentenFehler_38 0;
BA_ "GenSigSendType" SG_ 2589283473 LAD_KomponentenFehler_39 0;
BA_ "GenSigStartValue" SG_ 2589283473 LAD_KomponentenFehler_39 2;
BA_ "GenSigSwitchedByIgnition" SG_ 2589283473 LAD_KomponentenFehler_39 0;
BA_ "GenSigSendType" SG_ 2589283473 LAD_KomponentenFehler_40 0;
BA_ "GenSigStartValue" SG_ 2589283473 LAD_KomponentenFehler_40 2;
BA_ "GenSigSwitchedByIgnition" SG_ 2589283473 LAD_KomponentenFehler_40 0;
BA_ "GenSigSendType" SG_ 2589283473 LAD_KomponentenFehler_41 0;
BA_ "GenSigStartValue" SG_ 2589283473 LAD_KomponentenFehler_41 2;
BA_ "GenSigSwitchedByIgnition" SG_ 2589283473 LAD_KomponentenFehler_41 0;
BA_ "GenSigSendType" SG_ 2589283473 LAD_KomponentenFehler_42 0;
BA_ "GenSigStartValue" SG_ 2589283473 LAD_KomponentenFehler_42 2;
BA_ "GenSigSwitchedByIgnition" SG_ 2589283473 LAD_KomponentenFehler_42 0;
BA_ "GenSigSendType" SG_ 2589283473 LAD_KomponentenFehler_43 0;
BA_ "GenSigStartValue" SG_ 2589283473 LAD_KomponentenFehler_43 2;
BA_ "GenSigSwitchedByIgnition" SG_ 2589283473 LAD_KomponentenFehler_43 0;
BA_ "GenSigSendType" SG_ 2589283473 LAD_KomponentenFehler_44 0;
BA_ "GenSigStartValue" SG_ 2589283473 LAD_KomponentenFehler_44 2;
BA_ "GenSigSwitchedByIgnition" SG_ 2589283473 LAD_KomponentenFehler_44 0;
BA_ "GenSigSendType" SG_ 2589283473 LAD_KomponentenFehler_45 0;
BA_ "GenSigStartValue" SG_ 2589283473 LAD_KomponentenFehler_45 2;
BA_ "GenSigSwitchedByIgnition" SG_ 2589283473 LAD_KomponentenFehler_45 0;
BA_ "GenSigSendType" SG_ 2589283473 LAD_KomponentenFehler_46 0;
BA_ "GenSigStartValue" SG_ 2589283473 LAD_KomponentenFehler_46 2;
BA_ "GenSigSwitchedByIgnition" SG_ 2589283473 LAD_KomponentenFehler_46 0;
BA_ "GenSigSendType" SG_ 2589283473 LAD_KomponentenFehler_47 0;
BA_ "GenSigStartValue" SG_ 2589283473 LAD_KomponentenFehler_47 2;
BA_ "GenSigSwitchedByIgnition" SG_ 2589283473 LAD_KomponentenFehler_47 0;
BA_ "GenSigSendType" SG_ 2589283473 LAD_KomponentenFehler_48 0;
BA_ "GenSigStartValue" SG_ 2589283473 LAD_KomponentenFehler_48 2;
BA_ "GenSigSwitchedByIgnition" SG_ 2589283473 LAD_KomponentenFehler_48 0;
BA_ "GenSigSendType" SG_ 2589283473 LAD_KomponentenFehler_49 0;
BA_ "GenSigStartValue" SG_ 2589283473 LAD_KomponentenFehler_49 2;
BA_ "GenSigSwitchedByIgnition" SG_ 2589283473 LAD_KomponentenFehler_49 0;
BA_ "GenSigSendType" SG_ 2589283473 LAD_KomponentenFehler_50 0;
BA_ "GenSigStartValue" SG_ 2589283473 LAD_KomponentenFehler_50 2;
BA_ "GenSigSwitchedByIgnition" SG_ 2589283473 LAD_KomponentenFehler_50 0;
BA_ "GenSigSendType" SG_ 2589283473 LAD_KomponentenFehler_51 0;
BA_ "GenSigStartValue" SG_ 2589283473 LAD_KomponentenFehler_51 2;
BA_ "GenSigSwitchedByIgnition" SG_ 2589283473 LAD_KomponentenFehler_51 0;
BA_ "GenSigSendType" SG_ 2589283473 LAD_KomponentenFehler_52 0;
BA_ "GenSigStartValue" SG_ 2589283473 LAD_KomponentenFehler_52 2;
BA_ "GenSigSwitchedByIgnition" SG_ 2589283473 LAD_KomponentenFehler_52 0;
BA_ "GenSigSendType" SG_ 2589283473 LAD_KomponentenFehler_53 0;
BA_ "GenSigStartValue" SG_ 2589283473 LAD_KomponentenFehler_53 2;
BA_ "GenSigSwitchedByIgnition" SG_ 2589283473 LAD_KomponentenFehler_53 0;
BA_ "GenSigSendType" SG_ 2589283473 LAD_KomponentenFehler_54 0;
BA_ "GenSigStartValue" SG_ 2589283473 LAD_KomponentenFehler_54 2;
BA_ "GenSigSwitchedByIgnition" SG_ 2589283473 LAD_KomponentenFehler_54 0;
BA_ "GenSigSendType" SG_ 2589283473 LAD_KomponentenFehler_55 0;
BA_ "GenSigStartValue" SG_ 2589283473 LAD_KomponentenFehler_55 2;
BA_ "GenSigSwitchedByIgnition" SG_ 2589283473 LAD_KomponentenFehler_55 0;
BA_ "GenSigSendType" SG_ 2589283473 LAD_KomponentenFehler_56 0;
BA_ "GenSigStartValue" SG_ 2589283473 LAD_KomponentenFehler_56 2;
BA_ "GenSigSwitchedByIgnition" SG_ 2589283473 LAD_KomponentenFehler_56 0;
BA_ "GenSigSendType" SG_ 2589283473 LAD_KomponentenFehler_57 0;
BA_ "GenSigStartValue" SG_ 2589283473 LAD_KomponentenFehler_57 2;
BA_ "GenSigSwitchedByIgnition" SG_ 2589283473 LAD_KomponentenFehler_57 0;
BA_ "GenSigSendType" SG_ 2589283473 LAD_KomponentenFehler_58 0;
BA_ "GenSigStartValue" SG_ 2589283473 LAD_KomponentenFehler_58 2;
BA_ "GenSigSwitchedByIgnition" SG_ 2589283473 LAD_KomponentenFehler_58 0;
BA_ "GenSigSendType" SG_ 2589283473 LAD_KomponentenFehler_59 0;
BA_ "GenSigStartValue" SG_ 2589283473 LAD_KomponentenFehler_59 2;
BA_ "GenSigSwitchedByIgnition" SG_ 2589283473 LAD_KomponentenFehler_59 0;
BA_ "GenSigSendType" SG_ 2589283473 LAD_KomponentenFehler_60 0;
BA_ "GenSigStartValue" SG_ 2589283473 LAD_KomponentenFehler_60 2;
BA_ "GenSigSwitchedByIgnition" SG_ 2589283473 LAD_KomponentenFehler_60 0;
BA_ "GenSigSendType" SG_ 2589283473 LAD_KomponentenFehler_61 0;
BA_ "GenSigStartValue" SG_ 2589283473 LAD_KomponentenFehler_61 2;
BA_ "GenSigSwitchedByIgnition" SG_ 2589283473 LAD_KomponentenFehler_61 0;
BA_ "GenSigSendType" SG_ 2589283473 LAD_KomponentenFehler_62 0;
BA_ "GenSigStartValue" SG_ 2589283473 LAD_KomponentenFehler_62 2;
BA_ "GenSigSwitchedByIgnition" SG_ 2589283473 LAD_KomponentenFehler_62 0;
BA_ "GenSigSendType" SG_ 2589283473 LAD_KomponentenFehler_63 0;
BA_ "GenSigStartValue" SG_ 2589283473 LAD_KomponentenFehler_63 2;
BA_ "GenSigSwitchedByIgnition" SG_ 2589283473 LAD_KomponentenFehler_63 0;
BA_ "GenSigSendType" SG_ 2589283473 LAD_Komponentenfehler_VLD 0;
BA_ "GenSigSwitchedByIgnition" SG_ 2589283473 LAD_Komponentenfehler_VLD 0;
BA_ "GenSigSendType" SG_ 2589283481 LAD_KomponentenFehler_64 0;
BA_ "GenSigStartValue" SG_ 2589283481 LAD_KomponentenFehler_64 2;
BA_ "GenSigSwitchedByIgnition" SG_ 2589283481 LAD_KomponentenFehler_64 0;
BA_ "GenSigSendType" SG_ 2589283481 LAD_KomponentenFehler_65 0;
BA_ "GenSigStartValue" SG_ 2589283481 LAD_KomponentenFehler_65 2;
BA_ "GenSigSwitchedByIgnition" SG_ 2589283481 LAD_KomponentenFehler_65 0;
BA_ "GenSigSendType" SG_ 2589283481 LAD_KomponentenFehler_66 0;
BA_ "GenSigStartValue" SG_ 2589283481 LAD_KomponentenFehler_66 2;
BA_ "GenSigSwitchedByIgnition" SG_ 2589283481 LAD_KomponentenFehler_66 0;
BA_ "GenSigSendType" SG_ 2589283481 LAD_KomponentenFehler_67 0;
BA_ "GenSigStartValue" SG_ 2589283481 LAD_KomponentenFehler_67 2;
BA_ "GenSigSwitchedByIgnition" SG_ 2589283481 LAD_KomponentenFehler_67 0;
BA_ "GenSigSendType" SG_ 2589283481 LAD_KomponentenFehler_68 0;
BA_ "GenSigStartValue" SG_ 2589283481 LAD_KomponentenFehler_68 2;
BA_ "GenSigSwitchedByIgnition" SG_ 2589283481 LAD_KomponentenFehler_68 0;
BA_ "GenSigSendType" SG_ 2589283481 LAD_KomponentenFehler_69 0;
BA_ "GenSigStartValue" SG_ 2589283481 LAD_KomponentenFehler_69 2;
BA_ "GenSigSwitchedByIgnition" SG_ 2589283481 LAD_KomponentenFehler_69 0;
BA_ "GenSigSendType" SG_ 2589283481 LAD_KomponentenFehler_70 0;
BA_ "GenSigStartValue" SG_ 2589283481 LAD_KomponentenFehler_70 2;
BA_ "GenSigSwitchedByIgnition" SG_ 2589283481 LAD_KomponentenFehler_70 0;
BA_ "GenSigSendType" SG_ 2589283481 LAD_KomponentenFehler_71 0;
BA_ "GenSigStartValue" SG_ 2589283481 LAD_KomponentenFehler_71 2;
BA_ "GenSigSwitchedByIgnition" SG_ 2589283481 LAD_KomponentenFehler_71 0;
BA_ "GenSigSendType" SG_ 2589283481 LAD_KomponentenFehler_72 0;
BA_ "GenSigStartValue" SG_ 2589283481 LAD_KomponentenFehler_72 2;
BA_ "GenSigSwitchedByIgnition" SG_ 2589283481 LAD_KomponentenFehler_72 0;
BA_ "GenSigSendType" SG_ 2589283481 LAD_KomponentenFehler_73 0;
BA_ "GenSigStartValue" SG_ 2589283481 LAD_KomponentenFehler_73 2;
BA_ "GenSigSwitchedByIgnition" SG_ 2589283481 LAD_KomponentenFehler_73 0;
BA_ "GenSigSendType" SG_ 2589283481 LAD_KomponentenFehler_74 0;
BA_ "GenSigStartValue" SG_ 2589283481 LAD_KomponentenFehler_74 2;
BA_ "GenSigSwitchedByIgnition" SG_ 2589283481 LAD_KomponentenFehler_74 0;
BA_ "GenSigSendType" SG_ 2589283481 LAD_KomponentenFehler_75 0;
BA_ "GenSigStartValue" SG_ 2589283481 LAD_KomponentenFehler_75 2;
BA_ "GenSigSwitchedByIgnition" SG_ 2589283481 LAD_KomponentenFehler_75 0;
BA_ "GenSigSendType" SG_ 160 EPS_04_BZ 0;
BA_ "GenSigFuncType" SG_ 160 EPS_04_BZ 1;
BA_ "GenSigSwitchedByIgnition" SG_ 160 EPS_04_BZ 0;
BA_ "GenSigSendType" SG_ 160 EPS_04_CRC 0;
BA_ "GenSigFuncType" SG_ 160 EPS_04_CRC 2;
BA_ "GenSigSwitchedByIgnition" SG_ 160 EPS_04_CRC 0;
BA_ "GenSigSendType" SG_ 160 EPS_AWA_Status 0;
BA_ "GenSigStartValue" SG_ 160 EPS_AWA_Status 14;
BA_ "GenSigSwitchedByIgnition" SG_ 160 EPS_AWA_Status 0;
BA_ "GenSigSendType" SG_ 160 EPS_FAS_Regelgroesse 0;
BA_ "GenSigStartValue" SG_ 160 EPS_FAS_Regelgroesse 62;
BA_ "GenSigSwitchedByIgnition" SG_ 160 EPS_FAS_Regelgroesse 0;
BA_ "Fehlerwert" SG_ 160 EPS_FAS_Regelgroesse 63;
BA_ "GenSigSendType" SG_ 160 EPS_FAS_VZ_Regelgroesse 0;
BA_ "GenSigSwitchedByIgnition" SG_ 160 EPS_FAS_VZ_Regelgroesse 0;
BA_ "GenSigSendType" SG_ 160 EPS_Lenkmoment_AbsReduz 0;
BA_ "GenSigStartValue" SG_ 160 EPS_Lenkmoment_AbsReduz 14;
BA_ "GenSigSwitchedByIgnition" SG_ 160 EPS_Lenkmoment_AbsReduz 0;
BA_ "Fehlerwert" SG_ 160 EPS_Lenkmoment_AbsReduz 15;
BA_ "GenSigSendType" SG_ 160 EPS_QBit_Zahnstangen_Pos 0;
BA_ "GenSigSwitchedByIgnition" SG_ 160 EPS_QBit_Zahnstangen_Pos 0;
BA_ "GenSigSendType" SG_ 160 EPS_STA_Status 0;
BA_ "GenSigStartValue" SG_ 160 EPS_STA_Status 14;
BA_ "GenSigSwitchedByIgnition" SG_ 160 EPS_STA_Status 0;
BA_ "GenSigSendType" SG_ 160 EPS_Versorgungsspannung 0;
BA_ "GenSigStartValue" SG_ 160 EPS_Versorgungsspannung 254;
BA_ "GenSigSwitchedByIgnition" SG_ 160 EPS_Versorgungsspannung 0;
BA_ "Fehlerwert" SG_ 160 EPS_Versorgungsspannung 255;
BA_ "GenSigSendType" SG_ 160 EPS_Versorgungsstatus 0;
BA_ "GenSigSwitchedByIgnition" SG_ 160 EPS_Versorgungsstatus 0;
BA_ "GenSigSendType" SG_ 160 EPS_VZ_Zahnstangenposition 0;
BA_ "GenSigSwitchedByIgnition" SG_ 160 EPS_VZ_Zahnstangenposition 0;
BA_ "GenSigSendType" SG_ 160 EPS_Zahnstangen_Pos 0;
BA_ "GenSigStartValue" SG_ 160 EPS_Zahnstangen_Pos 4094;
BA_ "GenSigSwitchedByIgnition" SG_ 160 EPS_Zahnstangen_Pos 0;
BA_ "Fehlerwert" SG_ 160 EPS_Zahnstangen_Pos 4095;
BA_ "GenSigSendType" SG_ 1600 MO_Absperrventil_oeffnen 0;
BA_ "GenSigSwitchedByIgnition" SG_ 1600 MO_Absperrventil_oeffnen 0;
BA_ "GenSigSendType" SG_ 1600 MO_aktives_Getriebeheizen 0;
BA_ "GenSigSwitchedByIgnition" SG_ 1600 MO_aktives_Getriebeheizen 0;
BA_ "GenSigSendType" SG_ 1600 MO_Ansaugluft_Temp 0;
BA_ "GenSigStartValue" SG_ 1600 MO_Ansaugluft_Temp 254;
BA_ "GenSigSwitchedByIgnition" SG_ 1600 MO_Ansaugluft_Temp 0;
BA_ "Fehlerwert" SG_ 1600 MO_Ansaugluft_Temp 255;
BA_ "GenSigSendType" SG_ 1600 MO_Getriebe_kuehlen 0;
BA_ "GenSigSwitchedByIgnition" SG_ 1600 MO_Getriebe_kuehlen 0;
BA_ "GenSigSendType" SG_ 1600 MO_Heizungspumpenansteuerung 0;
BA_ "GenSigStartValue" SG_ 1600 MO_Heizungspumpenansteuerung 14;
BA_ "GenSigSwitchedByIgnition" SG_ 1600 MO_Heizungspumpenansteuerung 0;
BA_ "Fehlerwert" SG_ 1600 MO_Heizungspumpenansteuerung 13;
BA_ "GenSigSendType" SG_ 1600 MO_Hoeheninfo 0;
BA_ "GenSigSwitchedByIgnition" SG_ 1600 MO_Hoeheninfo 0;
BA_ "Fehlerwert" SG_ 1600 MO_Hoeheninfo 255;
BA_ "GenSigSendType" SG_ 1600 MO_HYB_Fehler_HV_Netz 0;
BA_ "GenSigSwitchedByIgnition" SG_ 1600 MO_HYB_Fehler_HV_Netz 0;
BA_ "GenSigSendType" SG_ 1600 MO_Kennfeldk 0;
BA_ "GenSigSwitchedByIgnition" SG_ 1600 MO_Kennfeldk 0;
BA_ "GenSigSendType" SG_ 1600 MO_KL15_Abschaltempfehlung 0;
BA_ "GenSigSwitchedByIgnition" SG_ 1600 MO_KL15_Abschaltempfehlung 0;
BA_ "GenSigSendType" SG_ 1600 MO_Kuehlmittel_Temp 0;
BA_ "GenSigStartValue" SG_ 1600 MO_Kuehlmittel_Temp 254;
BA_ "GenSigSwitchedByIgnition" SG_ 1600 MO_Kuehlmittel_Temp 0;
BA_ "Fehlerwert" SG_ 1600 MO_Kuehlmittel_Temp 255;
BA_ "GenSigSendType" SG_ 1600 MO_Mom_Traegheit_02 0;
BA_ "GenSigSwitchedByIgnition" SG_ 1600 MO_Mom_Traegheit_02 0;
BA_ "GenSigSendType" SG_ 1600 MO_Nachlaufzeit_Heizungspumpe 0;
BA_ "GenSigSwitchedByIgnition" SG_ 1600 MO_Nachlaufzeit_Heizungspumpe 0;
BA_ "GenSigSendType" SG_ 1600 MO_Oel_Temp 0;
BA_ "GenSigStartValue" SG_ 1600 MO_Oel_Temp 254;
BA_ "GenSigSwitchedByIgnition" SG_ 1600 MO_Oel_Temp 0;
BA_ "Fehlerwert" SG_ 1600 MO_Oel_Temp 255;
BA_ "GenSigSendType" SG_ 1600 MO_QBit_Ansaugluft_Temp 0;
BA_ "GenSigStartValue" SG_ 1600 MO_QBit_Ansaugluft_Temp 1;
BA_ "GenSigSwitchedByIgnition" SG_ 1600 MO_QBit_Ansaugluft_Temp 0;
BA_ "GenSigSendType" SG_ 1600 MO_QBit_Hoeheninfo 0;
BA_ "GenSigStartValue" SG_ 1600 MO_QBit_Hoeheninfo 1;
BA_ "GenSigSwitchedByIgnition" SG_ 1600 MO_QBit_Hoeheninfo 0;
BA_ "GenSigSendType" SG_ 1600 MO_QBit_Kuehlmittel_Temp 0;
BA_ "GenSigStartValue" SG_ 1600 MO_QBit_Kuehlmittel_Temp 1;
BA_ "GenSigSwitchedByIgnition" SG_ 1600 MO_QBit_Kuehlmittel_Temp 0;
BA_ "GenSigSendType" SG_ 1600 MO_QBit_Oel_Temp 0;
BA_ "GenSigStartValue" SG_ 1600 MO_QBit_Oel_Temp 1;
BA_ "GenSigSwitchedByIgnition" SG_ 1600 MO_QBit_Oel_Temp 0;
BA_ "GenSigSendType" SG_ 1600 MO_SpannungsAnf 0;
BA_ "GenSigSwitchedByIgnition" SG_ 1600 MO_SpannungsAnf 0;
BA_ "GenSigSendType" SG_ 1600 MO_Versionsinfo_02 0;
BA_ "GenSigSwitchedByIgnition" SG_ 1600 MO_Versionsinfo_02 0;
BA_ "GenSigSendType" SG_ 1607 MO_CO2_Faktor 0;
BA_ "GenSigSwitchedByIgnition" SG_ 1607 MO_CO2_Faktor 0;
BA_ "Fehlerwert" SG_ 1607 MO_CO2_Faktor 4095;
BA_ "GenSigSendType" SG_ 1607 MO_E85_Sensor 0;
BA_ "GenSigStartValue" SG_ 1607 MO_E85_Sensor 14;
BA_ "GenSigSwitchedByIgnition" SG_ 1607 MO_E85_Sensor 0;
BA_ "Fehlerwert" SG_ 1607 MO_E85_Sensor 15;
BA_ "GenSigSendType" SG_ 1607 MO_Ethanol_Spuelhinweis 0;
BA_ "GenSigSwitchedByIgnition" SG_ 1607 MO_Ethanol_Spuelhinweis 0;
BA_ "GenSigSendType" SG_ 1607 MO_ITM_Kuehlmittel_Temp 0;
BA_ "GenSigStartValue" SG_ 1607 MO_ITM_Kuehlmittel_Temp 1;
BA_ "GenSigSwitchedByIgnition" SG_ 1607 MO_ITM_Kuehlmittel_Temp 0;
BA_ "Fehlerwert" SG_ 1607 MO_ITM_Kuehlmittel_Temp 2;
BA_ "GenSigSendType" SG_ 1607 MO_Kraftstofffilter_Wasser 0;
BA_ "GenSigSwitchedByIgnition" SG_ 1607 MO_Kraftstofffilter_Wasser 0;
BA_ "GenSigSwitchedByIgnition" SG_ 1607 MO_MKB_01 0;
BA_ "GenSigSwitchedByIgnition" SG_ 1607 MO_MKB_02 0;
BA_ "GenSigSwitchedByIgnition" SG_ 1607 MO_MKB_03 0;
BA_ "GenSigSwitchedByIgnition" SG_ 1607 MO_MKB_04 0;
BA_ "GenSigSendType" SG_ 1607 MO_MKB_MUX 0;
BA_ "GenSigSwitchedByIgnition" SG_ 1607 MO_MKB_MUX 0;
BA_ "GenSigSendType" SG_ 1607 SCR_Akustik 0;
BA_ "GenSigSwitchedByIgnition" SG_ 1607 SCR_Akustik 0;
BA_ "GenSigSendType" SG_ 1607 SCR_Anz_Motorstarts 0;
BA_ "GenSigStartValue" SG_ 1607 SCR_Anz_Motorstarts 15;
BA_ "GenSigSwitchedByIgnition" SG_ 1607 SCR_Anz_Motorstarts 0;
BA_ "GenSigSendType" SG_ 1607 SCR_Inducement_Strategie 0;
BA_ "GenSigSwitchedByIgnition" SG_ 1607 SCR_Inducement_Strategie 0;
BA_ "GenSigSendType" SG_ 1607 SCR_Reichweite 0;
BA_ "GenSigStartValue" SG_ 1607 SCR_Reichweite 32767;
BA_ "GenSigSwitchedByIgnition" SG_ 1607 SCR_Reichweite 0;
BA_ "GenSigSendType" SG_ 1607 SCR_Systemfehler 0;
BA_ "GenSigSwitchedByIgnition" SG_ 1607 SCR_Systemfehler 0;
BA_ "GenSigSendType" SG_ 1607 SCR_Text 0;
BA_ "GenSigSwitchedByIgnition" SG_ 1607 SCR_Text 0;
BA_ "GenSigSendType" SG_ 1607 SCR_verbaut 0;
BA_ "GenSigFuncType" SG_ 1607 SCR_verbaut 8;
BA_ "GenSigSwitchedByIgnition" SG_ 1607 SCR_verbaut 0;
BA_ "GenSigSendType" SG_ 1607 SCR_Warnstufe_1 0;
BA_ "GenSigSwitchedByIgnition" SG_ 1607 SCR_Warnstufe_1 0;
BA_ "GenSigSendType" SG_ 1607 SCR_Warnstufe_2 0;
BA_ "GenSigSwitchedByIgnition" SG_ 1607 SCR_Warnstufe_2 0;
BA_ "GenSigSendType" SG_ 168 MO_Drehzahl_01 0;
BA_ "GenSigSwitchedByIgnition" SG_ 168 MO_Drehzahl_01 0;
BA_ "GenSigSendType" SG_ 168 MO_Mom_Begr_dyn 0;
BA_ "GenSigStartValue" SG_ 168 MO_Mom_Begr_dyn 1022;
BA_ "GenSigSwitchedByIgnition" SG_ 168 MO_Mom_Begr_dyn 0;
BA_ "GenSigSendType" SG_ 168 MO_Mom_Begr_stat 0;
BA_ "GenSigStartValue" SG_ 168 MO_Mom_Begr_stat 510;
BA_ "GenSigSwitchedByIgnition" SG_ 168 MO_Mom_Begr_stat 0;
BA_ "GenSigSendType" SG_ 168 MO_Mom_neg_verfuegbar 0;
BA_ "GenSigStartValue" SG_ 168 MO_Mom_neg_verfuegbar 510;
BA_ "GenSigSwitchedByIgnition" SG_ 168 MO_Mom_neg_verfuegbar 0;
BA_ "Fehlerwert" SG_ 168 MO_Mom_neg_verfuegbar 511;
BA_ "GenSigSendType" SG_ 168 MO_Momentenintegral_02 0;
BA_ "GenSigSwitchedByIgnition" SG_ 168 MO_Momentenintegral_02 0;
BA_ "GenSigSendType" SG_ 168 MO_QBit_Drehzahl_01 0;
BA_ "GenSigStartValue" SG_ 168 MO_QBit_Drehzahl_01 1;
BA_ "GenSigSwitchedByIgnition" SG_ 168 MO_QBit_Drehzahl_01 0;
BA_ "GenSigSendType" SG_ 168 Motor_12_BZ 0;
BA_ "GenSigFuncType" SG_ 168 Motor_12_BZ 1;
BA_ "GenSigSwitchedByIgnition" SG_ 168 Motor_12_BZ 0;
BA_ "GenSigSendType" SG_ 168 Motor_12_CRC 0;
BA_ "GenSigFuncType" SG_ 168 Motor_12_CRC 2;
BA_ "GenSigSwitchedByIgnition" SG_ 168 Motor_12_CRC 0;
BA_ "GenSigSendType" SG_ 958 MO_Aussp_Anlass 3;
BA_ "GenSigSwitchedByIgnition" SG_ 958 MO_Aussp_Anlass 0;
BA_ "GenSigSendType" SG_ 958 MO_BKV_Unterdruckwarnung 0;
BA_ "GenSigSwitchedByIgnition" SG_ 958 MO_BKV_Unterdruckwarnung 0;
BA_ "GenSigSendType" SG_ 958 MO_BLS 3;
BA_ "GenSigSwitchedByIgnition" SG_ 958 MO_BLS 0;
BA_ "GenSigSendType" SG_ 958 MO_BMS_NV_Anf_stuetzen 3;
BA_ "GenSigSwitchedByIgnition" SG_ 958 MO_BMS_NV_Anf_stuetzen 0;
BA_ "GenSigSendType" SG_ 958 MO_EKlKomLeiRed 0;
BA_ "GenSigSwitchedByIgnition" SG_ 958 MO_EKlKomLeiRed 0;
BA_ "GenSigSendType" SG_ 958 MO_Ext_E_Fahrt_aktiv 3;
BA_ "NWM-WakeupAllowed" SG_ 958 MO_Ext_E_Fahrt_aktiv 1;
BA_ "GenSigSwitchedByIgnition" SG_ 958 MO_Ext_E_Fahrt_aktiv 0;
BA_ "GenSigSendType" SG_ 958 MO_Fahrer_bremst 3;
BA_ "GenSigSwitchedByIgnition" SG_ 958 MO_Fahrer_bremst 0;
BA_ "GenSigSendType" SG_ 958 MO_FMAus_aktiv 3;
BA_ "GenSigSwitchedByIgnition" SG_ 958 MO_FMAus_aktiv 0;
BA_ "GenSigSendType" SG_ 958 MO_FMAus_Startvariante 3;
BA_ "GenSigSwitchedByIgnition" SG_ 958 MO_FMAus_Startvariante 0;
BA_ "GenSigSendType" SG_ 958 MO_Freig_Anlass 3;
BA_ "GenSigSwitchedByIgnition" SG_ 958 MO_Freig_Anlass 0;
BA_ "GenSigSendType" SG_ 958 MO_Freig_Reku 0;
BA_ "GenSigSwitchedByIgnition" SG_ 958 MO_Freig_Reku 0;
BA_ "GenSigSendType" SG_ 958 MO_Freigabe_Segeln 0;
BA_ "GenSigSwitchedByIgnition" SG_ 958 MO_Freigabe_Segeln 0;
BA_ "GenSigSendType" SG_ 958 MO_Gangposition 3;
BA_ "GenSigStartValue" SG_ 958 MO_Gangposition 14;
BA_ "GenSigSwitchedByIgnition" SG_ 958 MO_Gangposition 0;
BA_ "Fehlerwert" SG_ 958 MO_Gangposition 15;
BA_ "GenSigSendType" SG_ 958 MO_Handshake_STH 0;
BA_ "GenSigSwitchedByIgnition" SG_ 958 MO_Handshake_STH 0;
BA_ "GenSigSendType" SG_ 958 MO_HYB_Fahrbereitschaft 0;
BA_ "GenSigSwitchedByIgnition" SG_ 958 MO_HYB_Fahrbereitschaft 0;
BA_ "GenSigSendType" SG_ 958 MO_HYB_VM_aktiv 3;
BA_ "GenSigSwitchedByIgnition" SG_ 958 MO_HYB_VM_aktiv 0;
BA_ "GenSigSendType" SG_ 958 MO_Interlock 3;
BA_ "GenSigSwitchedByIgnition" SG_ 958 MO_Interlock 0;
BA_ "GenSigSendType" SG_ 958 MO_Kickdown 3;
BA_ "GenSigSwitchedByIgnition" SG_ 958 MO_Kickdown 0;
BA_ "GenSigSendType" SG_ 958 MO_Kl_50 3;
BA_ "GenSigSwitchedByIgnition" SG_ 958 MO_Kl_50 0;
BA_ "GenSigSendType" SG_ 958 MO_Kl_75 3;
BA_ "GenSigSwitchedByIgnition" SG_ 958 MO_Kl_75 0;
BA_ "GenSigSendType" SG_ 958 MO_Klima_Eingr 0;
BA_ "GenSigSwitchedByIgnition" SG_ 958 MO_Klima_Eingr 0;
BA_ "GenSigSendType" SG_ 958 MO_KomFehler_ESP 3;
BA_ "GenSigSwitchedByIgnition" SG_ 958 MO_KomFehler_ESP 0;
BA_ "Fehlerwert" SG_ 958 MO_KomFehler_ESP 1;
BA_ "GenSigSendType" SG_ 958 MO_Konsistenz_Bremsped 3;
BA_ "GenSigSwitchedByIgnition" SG_ 958 MO_Konsistenz_Bremsped 0;
BA_ "GenSigSendType" SG_ 958 MO_Kuppl_schalter 3;
BA_ "GenSigSwitchedByIgnition" SG_ 958 MO_Kuppl_schalter 0;
BA_ "GenSigSendType" SG_ 958 MO_Motor_laeuft 3;
BA_ "GenSigSwitchedByIgnition" SG_ 958 MO_Motor_laeuft 0;
BA_ "GenSigSendType" SG_ 958 MO_PTC_Status 0;
BA_ "GenSigSwitchedByIgnition" SG_ 958 MO_PTC_Status 0;
BA_ "GenSigSendType" SG_ 958 MO_QBit_Fahrer_bremst 3;
BA_ "GenSigStartValue" SG_ 958 MO_QBit_Fahrer_bremst 1;
BA_ "GenSigSwitchedByIgnition" SG_ 958 MO_QBit_Fahrer_bremst 0;
BA_ "GenSigSendType" SG_ 958 MO_QBit_Gangposition 3;
BA_ "GenSigStartValue" SG_ 958 MO_QBit_Gangposition 1;
BA_ "GenSigSwitchedByIgnition" SG_ 958 MO_QBit_Gangposition 0;
BA_ "GenSigSendType" SG_ 958 MO_QBit_KL_75 3;
BA_ "GenSigStartValue" SG_ 958 MO_QBit_KL_75 1;
BA_ "GenSigSwitchedByIgnition" SG_ 958 MO_QBit_KL_75 0;
BA_ "GenSigSendType" SG_ 958 MO_Remotestart_Betrieb 3;
BA_ "GenSigSwitchedByIgnition" SG_ 958 MO_Remotestart_Betrieb 0;
BA_ "GenSigSendType" SG_ 958 MO_Remotestart_moeglich 0;
BA_ "GenSigSwitchedByIgnition" SG_ 958 MO_Remotestart_moeglich 0;
BA_ "GenSigSendType" SG_ 958 MO_Signalquelle_Gangposition 0;
BA_ "GenSigSwitchedByIgnition" SG_ 958 MO_Signalquelle_Gangposition 0;
BA_ "GenSigSendType" SG_ 958 MO_StartStopp_Fahrerwunsch 0;
BA_ "GenSigSwitchedByIgnition" SG_ 958 MO_StartStopp_Fahrerwunsch 0;
BA_ "GenSigSendType" SG_ 958 MO_StartStopp_Motorstopp 3;
BA_ "GenSigSwitchedByIgnition" SG_ 958 MO_StartStopp_Motorstopp 0;
BA_ "GenSigSendType" SG_ 958 MO_StartStopp_Status 3;
BA_ "GenSigSwitchedByIgnition" SG_ 958 MO_StartStopp_Status 0;
BA_ "GenSigSendType" SG_ 958 MO_StartStopp_Wiederstart 3;
BA_ "GenSigSwitchedByIgnition" SG_ 958 MO_StartStopp_Wiederstart 0;
BA_ "GenSigSendType" SG_ 958 MO_StartVorauss_erfuellt 3;
BA_ "GenSigStartValue" SG_ 958 MO_StartVorauss_erfuellt 1;
BA_ "GenSigSwitchedByIgnition" SG_ 958 MO_StartVorauss_erfuellt 0;
BA_ "GenSigSendType" SG_ 958 MO_Zylinderabschaltung 3;
BA_ "GenSigSwitchedByIgnition" SG_ 958 MO_Zylinderabschaltung 0;
BA_ "GenSigSendType" SG_ 958 Motor_14_BZ 0;
BA_ "GenSigFuncType" SG_ 958 Motor_14_BZ 1;
BA_ "GenSigSwitchedByIgnition" SG_ 958 Motor_14_BZ 0;
BA_ "GenSigSendType" SG_ 958 Motor_14_CRC 0;
BA_ "GenSigFuncType" SG_ 958 Motor_14_CRC 2;
BA_ "GenSigSwitchedByIgnition" SG_ 958 Motor_14_CRC 0;
BA_ "GenSigSendType" SG_ 812 MO_BZS_Charisma_FahrPr 3;
BA_ "GenSigSwitchedByIgnition" SG_ 812 MO_BZS_Charisma_FahrPr 0;
BA_ "GenSigSendType" SG_ 812 MO_BZS_Charisma_Status 0;
BA_ "GenSigSwitchedByIgnition" SG_ 812 MO_BZS_Charisma_Status 0;
BA_ "GenSigSendType" SG_ 812 MO_Charisma_FahrPr 0;
BA_ "GenSigSwitchedByIgnition" SG_ 812 MO_Charisma_FahrPr 0;
BA_ "GenSigSendType" SG_ 812 MO_Charisma_Status 0;
BA_ "GenSigSwitchedByIgnition" SG_ 812 MO_Charisma_Status 0;
BA_ "GenSigSendType" SG_ 812 MO_Drehzahlbeeinflussung 0;
BA_ "GenSigSwitchedByIgnition" SG_ 812 MO_Drehzahlbeeinflussung 0;
BA_ "GenSigSendType" SG_ 812 MO_Luftpfad_aktiv 0;
BA_ "GenSigSwitchedByIgnition" SG_ 812 MO_Luftpfad_aktiv 0;
BA_ "GenSigSendType" SG_ 812 MO_MAX_Wunschdrehzahl 3;
BA_ "GenSigSwitchedByIgnition" SG_ 812 MO_MAX_Wunschdrehzahl 0;
BA_ "GenSigSendType" SG_ 812 MO_MIN_Wunschdrehzahl 0;
BA_ "GenSigSwitchedByIgnition" SG_ 812 MO_MIN_Wunschdrehzahl 0;
BA_ "GenSigSendType" SG_ 812 MO_NGS_Position 0;
BA_ "GenSigSwitchedByIgnition" SG_ 812 MO_NGS_Position 0;
BA_ "GenSigSendType" SG_ 812 MO_NGS_Status 0;
BA_ "GenSigSwitchedByIgnition" SG_ 812 MO_NGS_Status 0;
BA_ "Fehlerwert" SG_ 812 MO_NGS_Status 3;
BA_ "GenSigSendType" SG_ 812 MO_Prio_MAX_Wunschdrehzahl 3;
BA_ "GenSigSwitchedByIgnition" SG_ 812 MO_Prio_MAX_Wunschdrehzahl 0;
BA_ "GenSigSendType" SG_ 812 MO_Prio_MIN_Wunschdrehzahl 0;
BA_ "GenSigSwitchedByIgnition" SG_ 812 MO_Prio_MIN_Wunschdrehzahl 0;
BA_ "GenSigSendType" SG_ 812 MO_Rampenzeit_Generator_Anf 0;
BA_ "GenSigStartValue" SG_ 812 MO_Rampenzeit_Generator_Anf 15;
BA_ "GenSigSwitchedByIgnition" SG_ 812 MO_Rampenzeit_Generator_Anf 0;
BA_ "GenSigSendType" SG_ 812 MO_Sperrung_FahrPr_BZS 0;
BA_ "GenSigSwitchedByIgnition" SG_ 812 MO_Sperrung_FahrPr_BZS 0;
BA_ "GenSigSendType" SG_ 812 MO_StSt_Charisma_FahrPr 0;
BA_ "GenSigSwitchedByIgnition" SG_ 812 MO_StSt_Charisma_FahrPr 0;
BA_ "GenSigSendType" SG_ 812 MO_StSt_Charisma_Status 0;
BA_ "GenSigSwitchedByIgnition" SG_ 812 MO_StSt_Charisma_Status 0;
BA_ "GenSigSendType" SG_ 812 MO_v_Begrenz_Aktivierbar 0;
BA_ "GenSigSwitchedByIgnition" SG_ 812 MO_v_Begrenz_Aktivierbar 0;
BA_ "GenSigSendType" SG_ 812 MO_v_Begrenzung_Niveau 0;
BA_ "GenSigSwitchedByIgnition" SG_ 812 MO_v_Begrenzung_Niveau 0;
BA_ "GenSigSendType" SG_ 1648 MO1_Freigabe_Info_WFS 3;
BA_ "GenSigSwitchedByIgnition" SG_ 1648 MO1_Freigabe_Info_WFS 0;
BA_ "GenSigSendType" SG_ 1648 MO1_Freigabe_Verfallsinfo_WFS 3;
BA_ "GenSigSwitchedByIgnition" SG_ 1648 MO1_Freigabe_Verfallsinfo_WFS 0;
BA_ "GenSigSendType" SG_ 1648 MO1_Sperr_Info_WFS 3;
BA_ "GenSigSwitchedByIgnition" SG_ 1648 MO1_Sperr_Info_WFS 0;
BA_ "GenSigSendType" SG_ 1648 MO_Abstellzeit 0;
BA_ "GenSigStartValue" SG_ 1648 MO_Abstellzeit 254;
BA_ "GenSigSwitchedByIgnition" SG_ 1648 MO_Abstellzeit 0;
BA_ "GenSigSendType" SG_ 1648 MO_Abstellzeit_Status 0;
BA_ "GenSigSwitchedByIgnition" SG_ 1648 MO_Abstellzeit_Status 0;
BA_ "GenSigSendType" SG_ 1648 MO_ANC_Kennfeld_Anf 3;
BA_ "GenSigSwitchedByIgnition" SG_ 1648 MO_ANC_Kennfeld_Anf 0;
BA_ "GenSigSendType" SG_ 1648 MO_Anzahl_Abgesch_Zyl 3;
BA_ "GenSigSwitchedByIgnition" SG_ 1648 MO_Anzahl_Abgesch_Zyl 0;
BA_ "GenSigSendType" SG_ 1648 MO_Bremslicht_Reku 3;
BA_ "GenSigSwitchedByIgnition" SG_ 1648 MO_Bremslicht_Reku 0;
BA_ "GenSigSendType" SG_ 1648 MO_Drehzahl_Warnung 0;
BA_ "GenSigSwitchedByIgnition" SG_ 1648 MO_Drehzahl_Warnung 0;
BA_ "GenSigSendType" SG_ 1648 MO_EPCL 0;
BA_ "GenSigSwitchedByIgnition" SG_ 1648 MO_EPCL 0;
BA_ "GenSigSendType" SG_ 1648 MO_Ethanol_BS_Texte 0;
BA_ "GenSigSwitchedByIgnition" SG_ 1648 MO_Ethanol_BS_Texte 0;
BA_ "GenSigSendType" SG_ 1648 MO_Fahrzeugtyp 0;
BA_ "GenSigFuncType" SG_ 1648 MO_Fahrzeugtyp 8;
BA_ "GenSigSwitchedByIgnition" SG_ 1648 MO_Fahrzeugtyp 0;
BA_ "GenSigSendType" SG_ 1648 MO_Fehler_Zylabsch 0;
BA_ "GenSigSwitchedByIgnition" SG_ 1648 MO_Fehler_Zylabsch 0;
BA_ "GenSigSendType" SG_ 1648 MO_Hybrid_StartStopp_LED 3;
BA_ "GenSigSwitchedByIgnition" SG_ 1648 MO_Hybrid_StartStopp_LED 0;
BA_ "GenSigSendType" SG_ 1648 MO_max_Ladedruck 0;
BA_ "GenSigFuncType" SG_ 1648 MO_max_Ladedruck 8;
BA_ "GenSigSwitchedByIgnition" SG_ 1648 MO_max_Ladedruck 0;
BA_ "GenSigSendType" SG_ 1648 MO_NMAX_Schaltanzeige 3;
BA_ "GenSigSwitchedByIgnition" SG_ 1648 MO_NMAX_Schaltanzeige 0;
BA_ "GenSigSendType" SG_ 1648 MO_obere_Drehzahlgrenze 0;
BA_ "GenSigSwitchedByIgnition" SG_ 1648 MO_obere_Drehzahlgrenze 0;
BA_ "GenSigSendType" SG_ 1648 MO_StartStopp_PopUp 3;
BA_ "GenSigSwitchedByIgnition" SG_ 1648 MO_StartStopp_PopUp 0;
BA_ "GenSigSendType" SG_ 1648 MO_Zylabsch_Texte 0;
BA_ "GenSigSwitchedByIgnition" SG_ 1648 MO_Zylabsch_Texte 0;
BA_ "GenSigSendType" SG_ 1648 MO_Zylabsch_Texte_02 3;
BA_ "GenSigSwitchedByIgnition" SG_ 1648 MO_Zylabsch_Texte_02 0;
BA_ "GenSigSendType" SG_ 1423 FSA_Fehlerpfade_Initialisieren 0;
BA_ "GenSigSwitchedByIgnition" SG_ 1423 FSA_Fehlerpfade_Initialisieren 0;
BA_ "GenSigSendType" SG_ 1423 MO_FSA_Sensorheizung 0;
BA_ "GenSigSwitchedByIgnition" SG_ 1423 MO_FSA_Sensorheizung 0;
BA_ "GenSigSendType" SG_ 1423 MO_Getriebe_Oelalterung 0;
BA_ "GenSigSwitchedByIgnition" SG_ 1423 MO_Getriebe_Oelalterung 0;
BA_ "GenSigSendType" SG_ 1423 MO_ITM_Status 0;
BA_ "GenSigStartValue" SG_ 1423 MO_ITM_Status 14;
BA_ "GenSigSwitchedByIgnition" SG_ 1423 MO_ITM_Status 0;
BA_ "Fehlerwert" SG_ 1423 MO_ITM_Status 15;
BA_ "GenSigSendType" SG_ 1423 MO_KJS_LLK_Pos_Summe 0;
BA_ "GenSigStartValue" SG_ 1423 MO_KJS_LLK_Pos_Summe 14;
BA_ "GenSigSwitchedByIgnition" SG_ 1423 MO_KJS_LLK_Pos_Summe 0;
BA_ "GenSigSendType" SG_ 1423 MO_Kuehlmittel_Temp_Rohwert 0;
BA_ "GenSigStartValue" SG_ 1423 MO_Kuehlmittel_Temp_Rohwert 254;
BA_ "GenSigSwitchedByIgnition" SG_ 1423 MO_Kuehlmittel_Temp_Rohwert 0;
BA_ "Fehlerwert" SG_ 1423 MO_Kuehlmittel_Temp_Rohwert 255;
BA_ "GenSigSendType" SG_ 1423 MO_Oel_Temp_Radsatz 0;
BA_ "GenSigStartValue" SG_ 1423 MO_Oel_Temp_Radsatz 254;
BA_ "GenSigSwitchedByIgnition" SG_ 1423 MO_Oel_Temp_Radsatz 0;
BA_ "Fehlerwert" SG_ 1423 MO_Oel_Temp_Radsatz 255;
BA_ "GenSigSendType" SG_ 1423 MO_Tankdruck 0;
BA_ "GenSigStartValue" SG_ 1423 MO_Tankdruck 254;
BA_ "GenSigSwitchedByIgnition" SG_ 1423 MO_Tankdruck 0;
BA_ "Fehlerwert" SG_ 1423 MO_Tankdruck 255;
BA_ "GenSigSendType" SG_ 967 MO_E_Mode 0;
BA_ "GenSigSwitchedByIgnition" SG_ 967 MO_E_Mode 0;
BA_ "GenSigSendType" SG_ 967 MO_E_Texte 0;
BA_ "GenSigSwitchedByIgnition" SG_ 967 MO_E_Texte 0;
BA_ "GenSigSendType" SG_ 967 MO_E_Warnungen 0;
BA_ "GenSigSwitchedByIgnition" SG_ 967 MO_E_Warnungen 0;
BA_ "GenSigSendType" SG_ 967 MO_EFLEX_Lampe 0;
BA_ "GenSigSwitchedByIgnition" SG_ 967 MO_EFLEX_Lampe 0;
BA_ "GenSigSendType" SG_ 967 MO_Heissleuchte 0;
BA_ "GenSigSwitchedByIgnition" SG_ 967 MO_Heissleuchte 0;
BA_ "GenSigSendType" SG_ 967 MO_ITM_Warnung_Pumpe 0;
BA_ "GenSigSwitchedByIgnition" SG_ 967 MO_ITM_Warnung_Pumpe 0;
BA_ "GenSigSendType" SG_ 967 MO_KJS_nicht_bereit 0;
BA_ "GenSigSwitchedByIgnition" SG_ 967 MO_KJS_nicht_bereit 0;
BA_ "Fehlerwert" SG_ 967 MO_KJS_nicht_bereit 1;
BA_ "GenSigStartValue" SG_ 967 MO_Kuehlerluefter_1 126;
BA_ "GenSigSwitchedByIgnition" SG_ 967 MO_Kuehlerluefter_1 0;
BA_ "Fehlerwert" SG_ 967 MO_Kuehlerluefter_1 127;
BA_ "GenSigStartValue" SG_ 967 MO_Kuehlerluefter_2 126;
BA_ "GenSigSwitchedByIgnition" SG_ 967 MO_Kuehlerluefter_2 0;
BA_ "Fehlerwert" SG_ 967 MO_Kuehlerluefter_2 127;
BA_ "GenSigSendType" SG_ 967 MO_Kuehlerluefter_MUX 0;
BA_ "GenSigSwitchedByIgnition" SG_ 967 MO_Kuehlerluefter_MUX 0;
BA_ "GenSigSendType" SG_ 967 MO_OBD2_Lampe 0;
BA_ "GenSigSwitchedByIgnition" SG_ 967 MO_OBD2_Lampe 0;
BA_ "GenSigSendType" SG_ 967 MO_Oelwarnung_max 0;
BA_ "GenSigSwitchedByIgnition" SG_ 967 MO_Oelwarnung_max 0;
BA_ "GenSigSendType" SG_ 967 MO_Partikel_Lampe 0;
BA_ "GenSigSwitchedByIgnition" SG_ 967 MO_Partikel_Lampe 0;
BA_ "GenSigSendType" SG_ 967 MO_RedFahrleistung_Lampe 0;
BA_ "GenSigSwitchedByIgnition" SG_ 967 MO_RedFahrleistung_Lampe 0;
BA_ "GenSigSendType" SG_ 967 MO_Systemlampe 0;
BA_ "GenSigSwitchedByIgnition" SG_ 967 MO_Systemlampe 0;
BA_ "GenSigSendType" SG_ 967 MO_Tankdeckel_Lampe 0;
BA_ "GenSigSwitchedByIgnition" SG_ 967 MO_Tankdeckel_Lampe 0;
BA_ "GenSigSendType" SG_ 967 MO_Text_Motorstart 0;
BA_ "GenSigSwitchedByIgnition" SG_ 967 MO_Text_Motorstart 0;
BA_ "GenSigSendType" SG_ 967 MO_Text_Partikelfil_Reg 0;
BA_ "GenSigSwitchedByIgnition" SG_ 967 MO_Text_Partikelfil_Reg 0;
BA_ "GenSigSendType" SG_ 967 MO_Text_Tankdeckelwarn 0;
BA_ "GenSigSwitchedByIgnition" SG_ 967 MO_Text_Tankdeckelwarn 0;
BA_ "GenSigSendType" SG_ 967 MO_Vorglueh_Lampe 0;
BA_ "GenSigSwitchedByIgnition" SG_ 967 MO_Vorglueh_Lampe 0;
BA_ "GenSigSendType" SG_ 967 MO_Zustand_HWP 0;
BA_ "GenSigStartValue" SG_ 967 MO_Zustand_HWP 1;
BA_ "GenSigSwitchedByIgnition" SG_ 967 MO_Zustand_HWP 0;
BA_ "GenSigSendType" SG_ 967 OLEV_Oelstand_nicht_vorhanden 0;
BA_ "GenSigSwitchedByIgnition" SG_ 967 OLEV_Oelstand_nicht_vorhanden 0;
BA_ "GenSigSendType" SG_ 967 OLEV_Systemstoerung 0;
BA_ "GenSigSwitchedByIgnition" SG_ 967 OLEV_Systemstoerung 0;
BA_ "GenSigSendType" SG_ 967 WIV_Anzeige_aktiv 0;
BA_ "GenSigSwitchedByIgnition" SG_ 967 WIV_Anzeige_aktiv 0;
BA_ "GenSigSendType" SG_ 967 WIV_laufender_Motor 0;
BA_ "GenSigSwitchedByIgnition" SG_ 967 WIV_laufender_Motor 0;
BA_ "GenSigSendType" SG_ 967 WIV_nachfuellanzeige_ein 0;
BA_ "GenSigSwitchedByIgnition" SG_ 967 WIV_nachfuellanzeige_ein 0;
BA_ "GenSigSendType" SG_ 967 WIV_nicht_betriebswarm 0;
BA_ "GenSigSwitchedByIgnition" SG_ 967 WIV_nicht_betriebswarm 0;
BA_ "GenSigSendType" SG_ 967 WIV_Oeldr_Warn_Motor 0;
BA_ "GenSigSwitchedByIgnition" SG_ 967 WIV_Oeldr_Warn_Motor 0;
BA_ "GenSigSendType" SG_ 967 WIV_Oeldyn_avl 0;
BA_ "GenSigSwitchedByIgnition" SG_ 967 WIV_Oeldyn_avl 0;
BA_ "GenSigSendType" SG_ 967 WIV_Oelmenge 0;
BA_ "GenSigSwitchedByIgnition" SG_ 967 WIV_Oelmenge 0;
BA_ "GenSigSendType" SG_ 967 WIV_Oelmin_Warn 0;
BA_ "GenSigSwitchedByIgnition" SG_ 967 WIV_Oelmin_Warn 0;
BA_ "GenSigSendType" SG_ 967 WIV_Oelstand 0;
BA_ "GenSigSwitchedByIgnition" SG_ 967 WIV_Oelstand 0;
BA_ "GenSigSendType" SG_ 967 WIV_Oelstand_nicht_vorhanden 0;
BA_ "GenSigSwitchedByIgnition" SG_ 967 WIV_Oelstand_nicht_vorhanden 0;
BA_ "GenSigSendType" SG_ 967 WIV_Oelsystem_aktiv 0;
BA_ "GenSigSwitchedByIgnition" SG_ 967 WIV_Oelsystem_aktiv 0;
BA_ "GenSigSendType" SG_ 967 WIV_Schieflage 0;
BA_ "GenSigSwitchedByIgnition" SG_ 967 WIV_Schieflage 0;
BA_ "GenSigSendType" SG_ 967 WIV_Sensorfehler 0;
BA_ "GenSigSwitchedByIgnition" SG_ 967 WIV_Sensorfehler 0;
BA_ "GenSigSendType" SG_ 967 WIV_Ueberfuell_deaktiv 0;
BA_ "GenSigSwitchedByIgnition" SG_ 967 WIV_Ueberfuell_deaktiv 0;
BA_ "GenSigSendType" SG_ 967 WIV_Ueberfuell_Warn 0;
BA_ "GenSigSwitchedByIgnition" SG_ 967 WIV_Ueberfuell_Warn 0;
BA_ "GenSigSendType" SG_ 967 WIV_Unterfuell_Warn 0;
BA_ "GenSigSwitchedByIgnition" SG_ 967 WIV_Unterfuell_Warn 0;
BA_ "GenSigSendType" SG_ 340 MO_Drehzahl_VM 0;
BA_ "GenSigSwitchedByIgnition" SG_ 340 MO_Drehzahl_VM 0;
BA_ "GenSigSendType" SG_ 340 MO_Fehlerstatus_Antrieb_FDR 0;
BA_ "GenSigSendType" SG_ 340 MO_IstMoment_VKM 0;
BA_ "GenSigStartValue" SG_ 340 MO_IstMoment_VKM 1022;
BA_ "GenSigSwitchedByIgnition" SG_ 340 MO_IstMoment_VKM 0;
BA_ "GenSigSendType" SG_ 340 MO_Mom_Begr_Schalt 0;
BA_ "GenSigStartValue" SG_ 340 MO_Mom_Begr_Schalt 1022;
BA_ "GenSigSwitchedByIgnition" SG_ 340 MO_Mom_Begr_Schalt 0;
BA_ "GenSigSendType" SG_ 340 MO_Mom_Begr_Schalt_Min 0;
BA_ "GenSigStartValue" SG_ 340 MO_Mom_Begr_Schalt_Min 1022;
BA_ "GenSigSwitchedByIgnition" SG_ 340 MO_Mom_Begr_Schalt_Min 0;
BA_ "GenSigSendType" SG_ 340 MO_Primaerachse_Anforderung 0;
BA_ "GenSigSwitchedByIgnition" SG_ 340 MO_Primaerachse_Anforderung 0;
BA_ "GenSigSendType" SG_ 340 Motor_28_BZ 0;
BA_ "GenSigFuncType" SG_ 340 Motor_28_BZ 1;
BA_ "GenSigSwitchedByIgnition" SG_ 340 Motor_28_BZ 0;
BA_ "GenSigSendType" SG_ 340 Motor_28_CRC 0;
BA_ "GenSigFuncType" SG_ 340 Motor_28_CRC 2;
BA_ "GenSigSwitchedByIgnition" SG_ 340 Motor_28_CRC 0;
BA_ "GenSigSendType" SG_ 1366 FWS_Koeffizient_2 0;
BA_ "GenSigStartValue" SG_ 1366 FWS_Koeffizient_2 254;
BA_ "GenSigSwitchedByIgnition" SG_ 1366 FWS_Koeffizient_2 0;
BA_ "Fehlerwert" SG_ 1366 FWS_Koeffizient_2 255;
BA_ "GenSigSendType" SG_ 1366 FWS_QBit_Koeffizient_2 0;
BA_ "GenSigStartValue" SG_ 1366 FWS_QBit_Koeffizient_2 1;
BA_ "GenSigSwitchedByIgnition" SG_ 1366 FWS_QBit_Koeffizient_2 0;
BA_ "GenSigSendType" SG_ 1366 MO_Fahrzeugabstellzeit 0;
BA_ "GenSigStartValue" SG_ 1366 MO_Fahrzeugabstellzeit 254;
BA_ "GenSigSwitchedByIgnition" SG_ 1366 MO_Fahrzeugabstellzeit 0;
BA_ "Fehlerwert" SG_ 1366 MO_Fahrzeugabstellzeit 255;
BA_ "GenSigSendType" SG_ 1366 MO_Fahrzeugabstellzeit_Status 0;
BA_ "GenSigSwitchedByIgnition" SG_ 1366 MO_Fahrzeugabstellzeit_Status 0;
BA_ "GenSigSendType" SG_ 1366 MO_HV_Auszeit 0;
BA_ "GenSigStartValue" SG_ 1366 MO_HV_Auszeit 510;
BA_ "GenSigSwitchedByIgnition" SG_ 1366 MO_HV_Auszeit 0;
BA_ "Fehlerwert" SG_ 1366 MO_HV_Auszeit 511;
BA_ "GenSigSendType" SG_ 1366 MO_HV_Auszeit_Status 0;
BA_ "GenSigSwitchedByIgnition" SG_ 1366 MO_HV_Auszeit_Status 0;
BA_ "GenSigSendType" SG_ 1366 MO_Verbau_StartSys_EM_HV 0;
BA_ "GenSigSwitchedByIgnition" SG_ 1366 MO_Verbau_StartSys_EM_HV 0;
BA_ "GenSigSendType" SG_ 1366 MO_Verbau_StartSys_EM_MV 0;
BA_ "GenSigSwitchedByIgnition" SG_ 1366 MO_Verbau_StartSys_EM_MV 0;
BA_ "GenSigSendType" SG_ 1366 MO_Verbau_StartSys_Q_Diode 0;
BA_ "GenSigSwitchedByIgnition" SG_ 1366 MO_Verbau_StartSys_Q_Diode 0;
BA_ "GenSigSendType" SG_ 1366 MO_Verbau_StartSys_Ritzelstarter 0;
BA_ "GenSigSwitchedByIgnition" SG_ 1366 MO_Verbau_StartSys_Ritzelstarter 0;
BA_ "GenSigSendType" SG_ 1366 MO_Verbau_StartSys_RSG_MV 0;
BA_ "GenSigSwitchedByIgnition" SG_ 1366 MO_Verbau_StartSys_RSG_MV 0;
BA_ "GenSigSendType" SG_ 1366 MO_Verbau_StartSys_RSG_NV 0;
BA_ "GenSigSwitchedByIgnition" SG_ 1366 MO_Verbau_StartSys_RSG_NV 0;
BA_ "GenSigSendType" SG_ 1366 MO_Ziel_SoC_Fremdladung 0;
BA_ "GenSigStartValue" SG_ 1366 MO_Ziel_SoC_Fremdladung 254;
BA_ "GenSigSwitchedByIgnition" SG_ 1366 MO_Ziel_SoC_Fremdladung 0;
BA_ "GenSigSendType" SG_ 283 MO_EBoost_verf_praed 0;
BA_ "GenSigSwitchedByIgnition" SG_ 283 MO_EBoost_verf_praed 0;
BA_ "GenSigSendType" SG_ 283 MO_eLaunch_verf 0;
BA_ "GenSigSwitchedByIgnition" SG_ 283 MO_eLaunch_verf 0;
BA_ "GenSigSendType" SG_ 283 MO_Fahrbereitschaft 3;
BA_ "GenSigSwitchedByIgnition" SG_ 283 MO_Fahrbereitschaft 0;
BA_ "GenSigSendType" SG_ 283 MO_Freilauf_Info 0;
BA_ "GenSigSwitchedByIgnition" SG_ 283 MO_Freilauf_Info 0;
BA_ "GenSigSendType" SG_ 283 MO_Freilauf_Status 3;
BA_ "GenSigSwitchedByIgnition" SG_ 283 MO_Freilauf_Status 0;
BA_ "Fehlerwert" SG_ 283 MO_Freilauf_Status 7;
BA_ "GenSigSendType" SG_ 283 MO_Heckspoiler_Anf 3;
BA_ "GenSigSwitchedByIgnition" SG_ 283 MO_Heckspoiler_Anf 0;
BA_ "GenSigSendType" SG_ 283 MO_Krit_Heckobjekt 0;
BA_ "GenSigSwitchedByIgnition" SG_ 283 MO_Krit_Heckobjekt 0;
BA_ "Fehlerwert" SG_ 283 MO_Krit_Heckobjekt 7;
BA_ "GenSigSendType" SG_ 283 MO_NGS_Gangpos 0;
BA_ "GenSigSwitchedByIgnition" SG_ 283 MO_NGS_Gangpos 0;
BA_ "Fehlerwert" SG_ 283 MO_NGS_Gangpos 7;
BA_ "GenSigSendType" SG_ 283 MO_Parken_WFS_Status 0;
BA_ "GenSigSwitchedByIgnition" SG_ 283 MO_Parken_WFS_Status 0;
BA_ "GenSigSendType" SG_ 283 MO_Positionierung_aktiv 0;
BA_ "GenSigSwitchedByIgnition" SG_ 283 MO_Positionierung_aktiv 0;
BA_ "GenSigSendType" SG_ 2527679581 MO_Abwurfschwelle_Charge 0;
BA_ "GenSigStartValue" SG_ 2527679581 MO_Abwurfschwelle_Charge 1022;
BA_ "GenSigSwitchedByIgnition" SG_ 2527679581 MO_Abwurfschwelle_Charge 0;
BA_ "Fehlerwert" SG_ 2527679581 MO_Abwurfschwelle_Charge 1023;
BA_ "GenSigSendType" SG_ 2527679581 MO_Abwurfschwelle_EV 0;
BA_ "GenSigStartValue" SG_ 2527679581 MO_Abwurfschwelle_EV 1022;
BA_ "GenSigSwitchedByIgnition" SG_ 2527679581 MO_Abwurfschwelle_EV 0;
BA_ "Fehlerwert" SG_ 2527679581 MO_Abwurfschwelle_EV 1023;
BA_ "GenSigSendType" SG_ 2527679581 MO_Anf_KJS_1 0;
BA_ "GenSigStartValue" SG_ 2527679581 MO_Anf_KJS_1 126;
BA_ "GenSigSwitchedByIgnition" SG_ 2527679581 MO_Anf_KJS_1 0;
BA_ "Fehlerwert" SG_ 2527679581 MO_Anf_KJS_1 127;
BA_ "GenSigSendType" SG_ 2527679581 MO_Hysterese_Reakt_Charge 0;
BA_ "GenSigStartValue" SG_ 2527679581 MO_Hysterese_Reakt_Charge 510;
BA_ "GenSigSwitchedByIgnition" SG_ 2527679581 MO_Hysterese_Reakt_Charge 0;
BA_ "Fehlerwert" SG_ 2527679581 MO_Hysterese_Reakt_Charge 511;
BA_ "GenSigSendType" SG_ 2527679581 MO_Hysterese_Reakt_EV 0;
BA_ "GenSigStartValue" SG_ 2527679581 MO_Hysterese_Reakt_EV 510;
BA_ "GenSigSwitchedByIgnition" SG_ 2527679581 MO_Hysterese_Reakt_EV 0;
BA_ "Fehlerwert" SG_ 2527679581 MO_Hysterese_Reakt_EV 511;
BA_ "GenSigSendType" SG_ 2527679581 MO_TME_KL_Anf 0;
BA_ "GenSigStartValue" SG_ 2527679581 MO_TME_KL_Anf 126;
BA_ "GenSigSwitchedByIgnition" SG_ 2527679581 MO_TME_KL_Anf 0;
BA_ "Fehlerwert" SG_ 2527679581 MO_TME_KL_Anf 127;
BA_ "GenSigSendType" SG_ 377 MO_Soll_NutzbarerSOC 3;
BA_ "GenSigStartValue" SG_ 377 MO_Soll_NutzbarerSOC 254;
BA_ "Fehlerwert" SG_ 377 MO_Soll_NutzbarerSOC 255;
BA_REL_ "GenSigTimeoutTime" BU_SG_REL_ AWC SG_ 160 EPS_Zahnstangen_Pos 1000;
BA_REL_ "GenSigTimeoutTime" BU_SG_REL_ AWC SG_ 160 EPS_VZ_Zahnstangenposition 1000;
BA_REL_ "GenSigTimeoutTime" BU_SG_REL_ AWC SG_ 160 EPS_QBit_Zahnstangen_Pos 1000;
BA_REL_ "GenSigTimeoutTime" BU_SG_REL_ AWC SG_ 168 MO_QBit_Drehzahl_01 500;
BA_REL_ "GenSigTimeoutTime" BU_SG_REL_ AWC SG_ 168 MO_Drehzahl_01 500;
BA_REL_ "GenSigTimeoutTime" BU_SG_REL_ AWC SG_ 958 MO_HYB_Fahrbereitschaft 1000;
BA_REL_ "GenSigTimeoutTime" BU_SG_REL_ AWC SG_ 958 MO_StartVorauss_erfuellt 1000;
BA_REL_ "GenSigTimeoutTime" BU_SG_REL_ BMC_MLBevo SG_ 2589283415 LAD_CALID_CVN_MUX 5000;
BA_REL_ "GenSigTimeoutTime" BU_SG_REL_ BMC_MLBevo SG_ 2589283415 LAD_CVN_VLD 5000;
BA_REL_ "GenSigTimeoutTime" BU_SG_REL_ BMC_MLBevo SG_ 2589283415 LAD_CALID_Index_01 5000;
BA_REL_ "GenSigTimeoutTime" BU_SG_REL_ BMC_MLBevo SG_ 2589283415 LAD_CALID_Index_05 5000;
BA_REL_ "GenSigTimeoutTime" BU_SG_REL_ BMC_MLBevo SG_ 2589283415 LAD_CALID_Index_09 5000;
BA_REL_ "GenSigTimeoutTime" BU_SG_REL_ BMC_MLBevo SG_ 2589283415 LAD_CALID_Index_13 5000;
BA_REL_ "GenSigTimeoutTime" BU_SG_REL_ BMC_MLBevo SG_ 2589283415 LAD_CALID_Index_02 5000;
BA_REL_ "GenSigTimeoutTime" BU_SG_REL_ BMC_MLBevo SG_ 2589283415 LAD_CALID_Index_06 5000;
BA_REL_ "GenSigTimeoutTime" BU_SG_REL_ BMC_MLBevo SG_ 2589283415 LAD_CALID_Index_10 5000;
BA_REL_ "GenSigTimeoutTime" BU_SG_REL_ BMC_MLBevo SG_ 2589283415 LAD_CALID_Index_14 5000;
BA_REL_ "GenSigTimeoutTime" BU_SG_REL_ BMC_MLBevo SG_ 2589283415 LAD_CALID_Index_03 5000;
BA_REL_ "GenSigTimeoutTime" BU_SG_REL_ BMC_MLBevo SG_ 2589283415 LAD_CALID_Index_07 5000;
BA_REL_ "GenSigTimeoutTime" BU_SG_REL_ BMC_MLBevo SG_ 2589283415 LAD_CALID_Index_11 5000;
BA_REL_ "GenSigTimeoutTime" BU_SG_REL_ BMC_MLBevo SG_ 2589283415 LAD_CALID_Index_15 5000;
BA_REL_ "GenSigTimeoutTime" BU_SG_REL_ BMC_MLBevo SG_ 2589283415 LAD_CALID_Index_04 5000;
BA_REL_ "GenSigTimeoutTime" BU_SG_REL_ BMC_MLBevo SG_ 2589283415 LAD_CALID_Index_08 5000;
BA_REL_ "GenSigTimeoutTime" BU_SG_REL_ BMC_MLBevo SG_ 2589283415 LAD_CALID_Index_12 5000;
BA_REL_ "GenSigTimeoutTime" BU_SG_REL_ BMC_MLBevo SG_ 2589283415 LAD_CALID_Index_16 5000;
BA_REL_ "GenSigTimeoutTime" BU_SG_REL_ BMC_MLBevo SG_ 2589283415 LAD_CVN_Byte_1 5000;
BA_REL_ "GenSigTimeoutTime" BU_SG_REL_ BMC_MLBevo SG_ 2589283415 LAD_CVN_Byte_2 5000;
BA_REL_ "GenSigTimeoutTime" BU_SG_REL_ BMC_MLBevo SG_ 2589283415 LAD_CVN_Byte_3 5000;
BA_REL_ "GenSigTimeoutTime" BU_SG_REL_ BMC_MLBevo SG_ 2589283415 LAD_CVN_Byte_4 5000;
BA_REL_ "GenSigTimeoutTime" BU_SG_REL_ BMC_MLBevo SG_ 2589283473 LAD_KomponentenFehler_33 5000;
BA_REL_ "GenSigTimeoutTime" BU_SG_REL_ BMC_MLBevo SG_ 2589283473 LAD_KomponentenFehler_34 5000;
BA_REL_ "GenSigTimeoutTime" BU_SG_REL_ BMC_MLBevo SG_ 2589283473 LAD_KomponentenFehler_35 5000;
BA_REL_ "GenSigTimeoutTime" BU_SG_REL_ BMC_MLBevo SG_ 2589283473 LAD_KomponentenFehler_36 5000;
BA_REL_ "GenSigTimeoutTime" BU_SG_REL_ BMC_MLBevo SG_ 2589283473 LAD_KomponentenFehler_37 5000;
BA_REL_ "GenSigTimeoutTime" BU_SG_REL_ BMC_MLBevo SG_ 2589283473 LAD_KomponentenFehler_38 5000;
BA_REL_ "GenSigTimeoutTime" BU_SG_REL_ BMC_MLBevo SG_ 2589283473 LAD_KomponentenFehler_39 5000;
BA_REL_ "GenSigTimeoutTime" BU_SG_REL_ BMC_MLBevo SG_ 2589283473 LAD_KomponentenFehler_40 5000;
BA_REL_ "GenSigTimeoutTime" BU_SG_REL_ BMC_MLBevo SG_ 2589283473 LAD_KomponentenFehler_41 5000;
BA_REL_ "GenSigTimeoutTime" BU_SG_REL_ BMC_MLBevo SG_ 2589283473 LAD_KomponentenFehler_42 5000;
BA_REL_ "GenSigTimeoutTime" BU_SG_REL_ BMC_MLBevo SG_ 2589283473 LAD_KomponentenFehler_43 5000;
BA_REL_ "GenSigTimeoutTime" BU_SG_REL_ BMC_MLBevo SG_ 2589283473 LAD_KomponentenFehler_44 5000;
BA_REL_ "GenSigTimeoutTime" BU_SG_REL_ BMC_MLBevo SG_ 2589283473 LAD_KomponentenFehler_45 5000;
BA_REL_ "GenSigTimeoutTime" BU_SG_REL_ BMC_MLBevo SG_ 2589283473 LAD_KomponentenFehler_46 5000;
BA_REL_ "GenSigTimeoutTime" BU_SG_REL_ BMC_MLBevo SG_ 2589283473 LAD_KomponentenFehler_47 5000;
BA_REL_ "GenSigTimeoutTime" BU_SG_REL_ BMC_MLBevo SG_ 2589283473 LAD_KomponentenFehler_48 5000;
BA_REL_ "GenSigTimeoutTime" BU_SG_REL_ BMC_MLBevo SG_ 2589283473 LAD_KomponentenFehler_49 5000;
BA_REL_ "GenSigTimeoutTime" BU_SG_REL_ BMC_MLBevo SG_ 2589283473 LAD_KomponentenFehler_50 5000;
BA_REL_ "GenSigTimeoutTime" BU_SG_REL_ BMC_MLBevo SG_ 2589283473 LAD_KomponentenFehler_51 5000;
BA_REL_ "GenSigTimeoutTime" BU_SG_REL_ BMC_MLBevo SG_ 2589283473 LAD_KomponentenFehler_52 5000;
BA_REL_ "GenSigTimeoutTime" BU_SG_REL_ BMC_MLBevo SG_ 2589283473 LAD_KomponentenFehler_53 5000;
BA_REL_ "GenSigTimeoutTime" BU_SG_REL_ BMC_MLBevo SG_ 2589283473 LAD_KomponentenFehler_54 5000;
BA_REL_ "GenSigTimeoutTime" BU_SG_REL_ BMC_MLBevo SG_ 2589283473 LAD_KomponentenFehler_55 5000;
BA_REL_ "GenSigTimeoutTime" BU_SG_REL_ BMC_MLBevo SG_ 2589283473 LAD_KomponentenFehler_56 5000;
BA_REL_ "GenSigTimeoutTime" BU_SG_REL_ BMC_MLBevo SG_ 2589283473 LAD_KomponentenFehler_57 5000;
BA_REL_ "GenSigTimeoutTime" BU_SG_REL_ BMC_MLBevo SG_ 2589283473 LAD_KomponentenFehler_58 5000;
BA_REL_ "GenSigTimeoutTime" BU_SG_REL_ BMC_MLBevo SG_ 2589283473 LAD_KomponentenFehler_59 5000;
BA_REL_ "GenSigTimeoutTime" BU_SG_REL_ BMC_MLBevo SG_ 2589283473 LAD_KomponentenFehler_60 5000;
BA_REL_ "GenSigTimeoutTime" BU_SG_REL_ BMC_MLBevo SG_ 2589283473 LAD_KomponentenFehler_61 5000;
BA_REL_ "GenSigTimeoutTime" BU_SG_REL_ BMC_MLBevo SG_ 2589283473 LAD_KomponentenFehler_62 5000;
BA_REL_ "GenSigTimeoutTime" BU_SG_REL_ BMC_MLBevo SG_ 2589283473 LAD_KomponentenFehler_63 5000;
BA_REL_ "GenSigTimeoutTime" BU_SG_REL_ BMC_MLBevo SG_ 2589283473 LAD_Komponentenfehler_VLD 5000;
BA_REL_ "GenSigTimeoutTime" BU_SG_REL_ BMC_MLBevo SG_ 2589283481 LAD_KomponentenFehler_64 5000;
BA_REL_ "GenSigTimeoutTime" BU_SG_REL_ BMC_MLBevo SG_ 2589283481 LAD_KomponentenFehler_65 5000;
BA_REL_ "GenSigTimeoutTime" BU_SG_REL_ BMC_MLBevo SG_ 2589283481 LAD_KomponentenFehler_66 5000;
BA_REL_ "GenSigTimeoutTime" BU_SG_REL_ BMC_MLBevo SG_ 2589283481 LAD_KomponentenFehler_67 5000;
BA_REL_ "GenSigTimeoutTime" BU_SG_REL_ BMC_MLBevo SG_ 2589283481 LAD_KomponentenFehler_68 5000;
BA_REL_ "GenSigTimeoutTime" BU_SG_REL_ BMC_MLBevo SG_ 2589283481 LAD_KomponentenFehler_69 5000;
BA_REL_ "GenSigTimeoutTime" BU_SG_REL_ BMC_MLBevo SG_ 2589283481 LAD_KomponentenFehler_70 5000;
BA_REL_ "GenSigTimeoutTime" BU_SG_REL_ BMC_MLBevo SG_ 2589283481 LAD_KomponentenFehler_71 5000;
BA_REL_ "GenSigTimeoutTime" BU_SG_REL_ BMC_MLBevo SG_ 2589283481 LAD_KomponentenFehler_72 5000;
BA_REL_ "GenSigTimeoutTime" BU_SG_REL_ BMC_MLBevo SG_ 2589283481 LAD_KomponentenFehler_73 5000;
BA_REL_ "GenSigTimeoutTime" BU_SG_REL_ BMC_MLBevo SG_ 2589283481 LAD_KomponentenFehler_74 5000;
BA_REL_ "GenSigTimeoutTime" BU_SG_REL_ BMC_MLBevo SG_ 2589283481 LAD_KomponentenFehler_75 5000;
BA_REL_ "GenSigTimeoutTime" BU_SG_REL_ BMC_MLBevo SG_ 2589283472 LAD_KomponentenFehler_01 5000;
BA_REL_ "GenSigTimeoutTime" BU_SG_REL_ BMC_MLBevo SG_ 2589283472 LAD_KomponentenFehler_02 5000;
BA_REL_ "GenSigTimeoutTime" BU_SG_REL_ BMC_MLBevo SG_ 2589283472 LAD_KomponentenFehler_03 5000;
BA_REL_ "GenSigTimeoutTime" BU_SG_REL_ BMC_MLBevo SG_ 2589283472 LAD_KomponentenFehler_04 5000;
BA_REL_ "GenSigTimeoutTime" BU_SG_REL_ BMC_MLBevo SG_ 2589283472 LAD_KomponentenFehler_05 5000;
BA_REL_ "GenSigTimeoutTime" BU_SG_REL_ BMC_MLBevo SG_ 2589283472 LAD_KomponentenFehler_06 5000;
BA_REL_ "GenSigTimeoutTime" BU_SG_REL_ BMC_MLBevo SG_ 2589283472 LAD_KomponentenFehler_07 5000;
BA_REL_ "GenSigTimeoutTime" BU_SG_REL_ BMC_MLBevo SG_ 2589283472 LAD_KomponentenFehler_08 5000;
BA_REL_ "GenSigTimeoutTime" BU_SG_REL_ BMC_MLBevo SG_ 2589283472 LAD_KomponentenFehler_09 5000;
BA_REL_ "GenSigTimeoutTime" BU_SG_REL_ BMC_MLBevo SG_ 2589283472 LAD_KomponentenFehler_10 5000;
BA_REL_ "GenSigTimeoutTime" BU_SG_REL_ BMC_MLBevo SG_ 2589283472 LAD_KomponentenFehler_11 5000;
BA_REL_ "GenSigTimeoutTime" BU_SG_REL_ BMC_MLBevo SG_ 2589283472 LAD_KomponentenFehler_12 5000;
BA_REL_ "GenSigTimeoutTime" BU_SG_REL_ BMC_MLBevo SG_ 2589283472 LAD_KomponentenFehler_13 5000;
BA_REL_ "GenSigTimeoutTime" BU_SG_REL_ BMC_MLBevo SG_ 2589283472 LAD_KomponentenFehler_14 5000;
BA_REL_ "GenSigTimeoutTime" BU_SG_REL_ BMC_MLBevo SG_ 2589283472 LAD_KomponentenFehler_15 5000;
BA_REL_ "GenSigTimeoutTime" BU_SG_REL_ BMC_MLBevo SG_ 2589283472 LAD_KomponentenFehler_16 5000;
BA_REL_ "GenSigTimeoutTime" BU_SG_REL_ BMC_MLBevo SG_ 2589283472 LAD_KomponentenFehler_17 5000;
BA_REL_ "GenSigTimeoutTime" BU_SG_REL_ BMC_MLBevo SG_ 2589283472 LAD_KomponentenFehler_18 5000;
BA_REL_ "GenSigTimeoutTime" BU_SG_REL_ BMC_MLBevo SG_ 2589283472 LAD_KomponentenFehler_19 5000;
BA_REL_ "GenSigTimeoutTime" BU_SG_REL_ BMC_MLBevo SG_ 2589283472 LAD_KomponentenFehler_20 5000;
BA_REL_ "GenSigTimeoutTime" BU_SG_REL_ BMC_MLBevo SG_ 2589283472 LAD_KomponentenFehler_21 5000;
BA_REL_ "GenSigTimeoutTime" BU_SG_REL_ BMC_MLBevo SG_ 2589283472 LAD_KomponentenFehler_22 5000;
BA_REL_ "GenSigTimeoutTime" BU_SG_REL_ BMC_MLBevo SG_ 2589283472 LAD_KomponentenFehler_23 5000;
BA_REL_ "GenSigTimeoutTime" BU_SG_REL_ BMC_MLBevo SG_ 2589283472 LAD_KomponentenFehler_24 5000;
BA_REL_ "GenSigTimeoutTime" BU_SG_REL_ BMC_MLBevo SG_ 2589283472 LAD_KomponentenFehler_25 5000;
BA_REL_ "GenSigTimeoutTime" BU_SG_REL_ BMC_MLBevo SG_ 2589283472 LAD_KomponentenFehler_26 5000;
BA_REL_ "GenSigTimeoutTime" BU_SG_REL_ BMC_MLBevo SG_ 2589283472 LAD_KomponentenFehler_27 5000;
BA_REL_ "GenSigTimeoutTime" BU_SG_REL_ BMC_MLBevo SG_ 2589283472 LAD_KomponentenFehler_28 5000;
BA_REL_ "GenSigTimeoutTime" BU_SG_REL_ BMC_MLBevo SG_ 2589283472 LAD_KomponentenFehler_29 5000;
BA_REL_ "GenSigTimeoutTime" BU_SG_REL_ BMC_MLBevo SG_ 2589283472 LAD_KomponentenFehler_30 5000;
BA_REL_ "GenSigTimeoutTime" BU_SG_REL_ BMC_MLBevo SG_ 2589283472 LAD_KomponentenFehler_31 5000;
BA_REL_ "GenSigTimeoutTime" BU_SG_REL_ BMC_MLBevo SG_ 2589283472 LAD_KomponentenFehler_32 5000;
BA_REL_ "GenSigTimeoutTime" BU_SG_REL_ BMC_MLBevo SG_ 168 MO_Drehzahl_01 500;
BA_REL_ "GenSigTimeoutTime" BU_SG_REL_ BMC_MLBevo SG_ 340 MO_Drehzahl_VM 2000;
BA_REL_ "GenSigTimeoutTime" BU_SG_REL_ BMC_MLBevo SG_ 1366 MO_Fahrzeugabstellzeit_Status 5000;
BA_REL_ "GenSigTimeoutTime" BU_SG_REL_ BMC_MLBevo SG_ 1366 MO_HV_Auszeit_Status 5000;
BA_REL_ "GenSigTimeoutTime" BU_SG_REL_ BMC_MLBevo SG_ 1366 MO_Fahrzeugabstellzeit 5000;
BA_REL_ "GenSigTimeoutTime" BU_SG_REL_ BMC_MLBevo SG_ 1366 MO_HV_Auszeit 5000;
BA_REL_ "GenSigTimeoutTime" BU_SG_REL_ BMC_MLBevo SG_ 2527679581 MO_Hysterese_Reakt_Charge 3200;
BA_REL_ "GenSigTimeoutTime" BU_SG_REL_ BMC_MLBevo SG_ 2527679581 MO_Hysterese_Reakt_EV 3200;
BA_REL_ "GenSigTimeoutTime" BU_SG_REL_ BMC_MLBevo SG_ 2527679581 MO_Abwurfschwelle_Charge 3200;
BA_REL_ "GenSigTimeoutTime" BU_SG_REL_ BMC_MLBevo SG_ 2527679581 MO_Abwurfschwelle_EV 3200;
BA_REL_ "GenSigTimeoutTime" BU_SG_REL_ BMC_MLBevo SG_ 377 MO_Soll_NutzbarerSOC 1000;
BA_REL_ "GenSigTimeoutTime" BU_SG_REL_ BMS_MV SG_ 1648 MO_Abstellzeit 5000;
BA_REL_ "GenSigTimeoutTime" BU_SG_REL_ BMS_MV SG_ 1648 MO_Abstellzeit_Status 5000;
BA_REL_ "GenSigTimeoutTime" BU_SG_REL_ BMS_MV SG_ 340 MO_Drehzahl_VM 2000;
BA_REL_ "GenSigTimeoutTime" BU_SG_REL_ BMS_NV SG_ 958 MO_StartStopp_Wiederstart 1000;
BA_REL_ "GenSigTimeoutTime" BU_SG_REL_ BMS_NV SG_ 958 MO_StartStopp_Motorstopp 1000;
BA_REL_ "GenSigTimeoutTime" BU_SG_REL_ BMS_NV SG_ 958 MO_HYB_Fahrbereitschaft 1000;
BA_REL_ "GenSigTimeoutTime" BU_SG_REL_ BMS_NV SG_ 958 MO_FMAus_aktiv 1000;
BA_REL_ "GenSigTimeoutTime" BU_SG_REL_ BMS_NV SG_ 1648 MO_Fahrzeugtyp 5000;
BA_REL_ "GenSigTimeoutTime" BU_SG_REL_ BMS_NV SG_ 1648 MO_Abstellzeit 5000;
BA_REL_ "GenSigTimeoutTime" BU_SG_REL_ BMS_NV SG_ 1648 MO_Abstellzeit_Status 5000;
BA_REL_ "GenSigTimeoutTime" BU_SG_REL_ BMS_NV SG_ 340 MO_Drehzahl_VM 2000;
BA_REL_ "GenSigTimeoutTime" BU_SG_REL_ BMS_NV SG_ 1366 MO_Verbau_StartSys_Ritzelstarter 5000;
BA_REL_ "GenSigTimeoutTime" BU_SG_REL_ BMS_NV SG_ 1366 MO_Verbau_StartSys_EM_MV 5000;
BA_REL_ "GenSigTimeoutTime" BU_SG_REL_ BMS_NV SG_ 1366 MO_Verbau_StartSys_EM_HV 5000;
BA_REL_ "GenSigTimeoutTime" BU_SG_REL_ BMS_NV SG_ 1366 MO_Verbau_StartSys_RSG_NV 5000;
BA_REL_ "GenSigTimeoutTime" BU_SG_REL_ BMS_NV SG_ 1366 MO_Verbau_StartSys_Q_Diode 5000;
BA_REL_ "GenSigTimeoutTime" BU_SG_REL_ BMS_NV SG_ 1366 MO_Verbau_StartSys_RSG_MV 5000;
BA_REL_ "GenSigTimeoutTime" BU_SG_REL_ BMS_NV SG_ 283 MO_Freilauf_Status 5000;
BA_REL_ "GenSigTimeoutTime" BU_SG_REL_ DCDC_800V_PAG SG_ 168 MO_Drehzahl_01 500;
BA_REL_ "GenSigTimeoutTime" BU_SG_REL_ DCDC_HV SG_ 168 MO_Drehzahl_01 500;
BA_REL_ "GenSigTimeoutTime" BU_SG_REL_ DCDC_HV SG_ 1366 MO_HV_Auszeit_Status 5000;
BA_REL_ "GenSigTimeoutTime" BU_SG_REL_ DCDC_HV SG_ 1366 MO_HV_Auszeit 5000;
BA_REL_ "GenSigTimeoutTime" BU_SG_REL_ DCDC_IHEV SG_ 958 MO_Kl_50 1000;
BA_REL_ "GenSigTimeoutTime" BU_SG_REL_ DCDC_IHEV SG_ 340 MO_Drehzahl_VM 2000;
BA_REL_ "GenSigTimeoutTime" BU_SG_REL_ Gateway SG_ 1662 LAD_02_CRC 5000;
BA_REL_ "GenSigTimeoutTime" BU_SG_REL_ Gateway SG_ 1662 LAD_02_BZ 5000;
BA_REL_ "GenSigTimeoutTime" BU_SG_REL_ Gateway_PAG SG_ 1662 LAD_02_CRC 5000;
BA_REL_ "GenSigTimeoutTime" BU_SG_REL_ Gateway_PAG SG_ 1662 LAD_02_BZ 5000;
BA_REL_ "GenSigTimeoutTime" BU_SG_REL_ Ladegeraet_2 SG_ 2463978642 LAD_SollStrom_HV_Pfad1 1000;
BA_REL_ "GenSigTimeoutTime" BU_SG_REL_ Ladegeraet_2 SG_ 2463978642 LAD_SollStrom_HV_Pfad2 1000;
BA_REL_ "GenSigTimeoutTime" BU_SG_REL_ Ladegeraet_2 SG_ 2463978642 LAD_SollStrom_HV_Pfad3 1000;
BA_REL_ "GenSigTimeoutTime" BU_SG_REL_ Ladegeraet_2 SG_ 2463978643 LAD_05_CRC 1000;
BA_REL_ "GenSigTimeoutTime" BU_SG_REL_ Ladegeraet_2 SG_ 2463978643 LAD_05_BZ 1000;
BA_REL_ "GenSigTimeoutTime" BU_SG_REL_ Ladegeraet_2 SG_ 2463978643 LAD_AC_MaxStrom_L1 1000;
BA_REL_ "GenSigTimeoutTime" BU_SG_REL_ Ladegeraet_2 SG_ 2463978643 LAD_AC_MaxStrom_L2 1000;
BA_REL_ "GenSigTimeoutTime" BU_SG_REL_ Ladegeraet_2 SG_ 2463978643 LAD_AC_MaxStrom_L3 1000;
BA_REL_ "GenSigTimeoutTime" BU_SG_REL_ Ladegeraet_2 SG_ 2463978643 LAD_Freigabe_LAD2 1000;
BA_REL_ "GenSigTimeoutTime" BU_SG_REL_ Ladegeraet_2 SG_ 2463978643 LAD_Max_LadeSpannung_LAD2 1000;
BA_REL_ "GenSigTimeoutTime" BU_SG_REL_ Ladegeraet_2 SG_ 168 MO_Drehzahl_01 500;
BA_REL_ "GenSigTimeoutTime" BU_SG_REL_ Ladegeraet_Konzern SG_ 168 MO_Drehzahl_01 500;
BA_REL_ "GenSigTimeoutTime" BU_SG_REL_ Ladegeraet_Konzern SG_ 958 MO_Kl_50 1000;
BA_REL_ "GenSigTimeoutTime" BU_SG_REL_ Ladegeraet_Konzern SG_ 958 MO_HYB_Fahrbereitschaft 1000;
BA_REL_ "GenSigTimeoutTime" BU_SG_REL_ Ladegeraet_Konzern SG_ 958 MO_StartVorauss_erfuellt 1000;
BA_REL_ "GenSigTimeoutTime" BU_SG_REL_ Ladegeraet_Konzern SG_ 1366 MO_HV_Auszeit_Status 5000;
BA_REL_ "GenSigTimeoutTime" BU_SG_REL_ Ladegeraet_Konzern SG_ 1366 MO_HV_Auszeit 5000;
BA_REL_ "GenSigTimeoutTime" BU_SG_REL_ TME SG_ 1662 LAD_Abregelung_Temperatur 5000;
BA_REL_ "GenSigTimeoutTime" BU_SG_REL_ TME SG_ 1662 LAD_MaxLadLeistung_HV 5000;
BA_REL_ "GenSigTimeoutTime" BU_SG_REL_ TME SG_ 2589283663 LAD_PlanAntw_Verlustleistung 5000;
BA_REL_ "GenSigTimeoutTime" BU_SG_REL_ TME SG_ 2589283663 LAD_PlanAntw_Zaehler 5000;
BA_REL_ "GenSigTimeoutTime" BU_SG_REL_ TME SG_ 1600 MO_Absperrventil_oeffnen 3200;
BA_REL_ "GenSigTimeoutTime" BU_SG_REL_ TME SG_ 1600 MO_Ansaugluft_Temp 3200;
BA_REL_ "GenSigTimeoutTime" BU_SG_REL_ TME SG_ 1600 MO_Oel_Temp 3200;
BA_REL_ "GenSigTimeoutTime" BU_SG_REL_ TME SG_ 1600 MO_Kuehlmittel_Temp 3200;
BA_REL_ "GenSigTimeoutTime" BU_SG_REL_ TME SG_ 1600 MO_Hoeheninfo 3200;
BA_REL_ "GenSigTimeoutTime" BU_SG_REL_ TME SG_ 1600 MO_Kennfeldk 3200;
BA_REL_ "GenSigTimeoutTime" BU_SG_REL_ TME SG_ 1600 MO_Heizungspumpenansteuerung 3200;
BA_REL_ "GenSigTimeoutTime" BU_SG_REL_ TME SG_ 1600 MO_Nachlaufzeit_Heizungspumpe 3200;
BA_REL_ "GenSigTimeoutTime" BU_SG_REL_ TME SG_ 1607 MO_ITM_Kuehlmittel_Temp 3200;
BA_REL_ "GenSigTimeoutTime" BU_SG_REL_ TME SG_ 168 MO_Drehzahl_01 500;
BA_REL_ "GenSigTimeoutTime" BU_SG_REL_ TME SG_ 958 MO_StartStopp_Status 1000;
BA_REL_ "GenSigTimeoutTime" BU_SG_REL_ TME SG_ 958 MO_StartStopp_Wiederstart 1000;
BA_REL_ "GenSigTimeoutTime" BU_SG_REL_ TME SG_ 958 MO_StartStopp_Motorstopp 1000;
BA_REL_ "GenSigTimeoutTime" BU_SG_REL_ TME SG_ 958 MO_Kl_75 1000;
BA_REL_ "GenSigTimeoutTime" BU_SG_REL_ TME SG_ 958 MO_Gangposition 1000;
BA_REL_ "GenSigTimeoutTime" BU_SG_REL_ TME SG_ 958 MO_StartStopp_Fahrerwunsch 1000;
BA_REL_ "GenSigTimeoutTime" BU_SG_REL_ TME SG_ 958 MO_HYB_Fahrbereitschaft 1000;
BA_REL_ "GenSigTimeoutTime" BU_SG_REL_ TME SG_ 958 MO_Ext_E_Fahrt_aktiv 1000;
BA_REL_ "GenSigTimeoutTime" BU_SG_REL_ TME SG_ 958 MO_Klima_Eingr 1000;
BA_REL_ "GenSigTimeoutTime" BU_SG_REL_ TME SG_ 958 MO_Motor_laeuft 1000;
BA_REL_ "GenSigTimeoutTime" BU_SG_REL_ TME SG_ 958 MO_Kickdown 1000;
BA_REL_ "GenSigTimeoutTime" BU_SG_REL_ TME SG_ 812 MO_Charisma_FahrPr 2000;
BA_REL_ "GenSigTimeoutTime" BU_SG_REL_ TME SG_ 812 MO_BZS_Charisma_FahrPr 2000;
BA_REL_ "GenSigTimeoutTime" BU_SG_REL_ TME SG_ 1648 MO_Abstellzeit 5000;
BA_REL_ "GenSigTimeoutTime" BU_SG_REL_ TME SG_ 1648 MO_Abstellzeit_Status 5000;
BA_REL_ "GenSigTimeoutTime" BU_SG_REL_ TME SG_ 1423 MO_ITM_Status 3200;
BA_REL_ "GenSigTimeoutTime" BU_SG_REL_ TME SG_ 1423 MO_Kuehlmittel_Temp_Rohwert 3200;
BA_REL_ "GenSigTimeoutTime" BU_SG_REL_ TME SG_ 967 MO_Kuehlerluefter_MUX 800;
BA_REL_ "GenSigTimeoutTime" BU_SG_REL_ TME SG_ 967 MO_Kuehlerluefter_1 800;
BA_REL_ "GenSigTimeoutTime" BU_SG_REL_ TME SG_ 967 MO_Kuehlerluefter_2 800;
BA_REL_ "GenSigTimeoutTime" BU_SG_REL_ TME SG_ 967 MO_Zustand_HWP 800;
BA_REL_ "GenSigTimeoutTime" BU_SG_REL_ TME SG_ 967 MO_Heissleuchte 800;
BA_REL_ "GenSigTimeoutTime" BU_SG_REL_ TME SG_ 340 MO_Drehzahl_VM 2000;
BA_REL_ "GenSigTimeoutTime" BU_SG_REL_ TME SG_ 1366 MO_Fahrzeugabstellzeit_Status 5000;
BA_REL_ "GenSigTimeoutTime" BU_SG_REL_ TME SG_ 1366 MO_HV_Auszeit_Status 5000;
BA_REL_ "GenSigTimeoutTime" BU_SG_REL_ TME SG_ 1366 MO_Fahrzeugabstellzeit 5000;
BA_REL_ "GenSigTimeoutTime" BU_SG_REL_ TME SG_ 1366 MO_HV_Auszeit 5000;
BA_REL_ "GenSigTimeoutTime" BU_SG_REL_ TME SG_ 2527679581 MO_TME_KL_Anf 3200;
BA_REL_ "GenSigTimeoutTime" BU_SG_REL_ TME SG_ 2527679581 MO_Anf_KJS_1 3200;
VAL_ 1662 LAD_Abregelung_Temperatur 0 "keine_Begrenzung" 1 "Abregelung_Temp" ;
VAL_ 1662 LAD_Abregelung_IU_Ein_Aus 0 "keine_Abregelung" 1 "Abregelung_UI" ;
VAL_ 1662 LAD_Abregelung_BuchseTemp 0 "keine_Abregelung" 1 "Abregelung_Buchsentemp" ;
VAL_ 1662 LAD_MaxLadLeistung_HV 510 "Init" 511 "Fehler" ;
VAL_ 1662 LAD_PRX_Stromlimit 0 "13_Ampere" 1 "20_Ampere" 2 "32_Ampere" 3 "63_Ampere" 6 "Init" 7 "Fehler" ;
VAL_ 1662 LAD_CP_Erkennung 0 "CP_nicht_erkannt" 1 "CP_erkannt" ;
VAL_ 1662 LAD_Stecker_Verriegelt 0 "nicht_verriegelt" 1 "verriegelt" ;
VAL_ 1662 LAD_Kuehlbedarf 0 "kein_Kuehlbedarf" 1 "geringer_Kuehlbedarf" 2 "mittlerer_Kuehlbedarf" 3 "hoher_Kuehlbedarf" ;
VAL_ 1662 LAD_MaxLadLeistung_HV_Offset 0 "LAD_MaxLadLeistung_HV +0W" 1 "LAD_MaxLadLeistung_HV +25W" 2 "LAD_MaxLadLeistung_HV +50W" 3 "LAD_MaxLadLeistung_HV +75W" ;
VAL_ 1662 LAD_Warnzustand 0 "keine_Warnung" 1 "Warnung_aktiv" ;
VAL_ 1662 LAD_Fehlerzustand 0 "kein_Fehler_aktiv" 1 "Fehler_aktiv_Laden_beendet" ;
VAL_ 2463978642 LAD_SollStrom_HV_Pfad1 254 "Init" 255 "Fehler" ;
VAL_ 2463978642 LAD_SollStrom_HV_Pfad2 254 "Init" 255 "Fehler" ;
VAL_ 2463978642 LAD_SollStrom_HV_Pfad3 254 "Init" 255 "Fehler" ;
VAL_ 2463978643 LAD_AC_MaxStrom_L1 1022 "Init" 1023 "Fehler" ;
VAL_ 2463978643 LAD_AC_MaxStrom_L2 1022 "Init" 1023 "Fehler" ;
VAL_ 2463978643 LAD_AC_MaxStrom_L3 1022 "Init" 1023 "Fehler" ;
VAL_ 2463978643 LAD_Freigabe_LAD2 0 "keine_Freigabe" 1 "Freigabe" ;
VAL_ 2463978643 LAD_Max_LadeSpannung_LAD2 1022 "Init" 1023 "Fehler" ;
VAL_ 2589283663 LAD_PlanAntw_Verlustleistung 4094 "Init" 4095 "Fehler" ;
VAL_ 2589283663 LAD_PlanAntw_Zaehler 14 "Init" 15 "Fehler" ;
VAL_ 2589283415 LAD_CVN_VLD 0 "ungueltig" 1 "gueltig" ;
VAL_ 2589283415 LAD_CALID_Index_01 48 "Init" ;
VAL_ 2589283415 LAD_CALID_Index_05 48 "Init" ;
VAL_ 2589283415 LAD_CALID_Index_09 48 "Init" ;
VAL_ 2589283415 LAD_CALID_Index_13 48 "Init" ;
VAL_ 2589283415 LAD_CALID_Index_02 48 "Init" ;
VAL_ 2589283415 LAD_CALID_Index_06 48 "Init" ;
VAL_ 2589283415 LAD_CALID_Index_10 48 "Init" ;
VAL_ 2589283415 LAD_CALID_Index_14 48 "Init" ;
VAL_ 2589283415 LAD_CALID_Index_03 48 "Init" ;
VAL_ 2589283415 LAD_CALID_Index_07 48 "Init" ;
VAL_ 2589283415 LAD_CALID_Index_11 48 "Init" ;
VAL_ 2589283415 LAD_CALID_Index_15 48 "Init" ;
VAL_ 2589283415 LAD_CALID_Index_04 48 "Init" ;
VAL_ 2589283415 LAD_CALID_Index_08 48 "Init" ;
VAL_ 2589283415 LAD_CALID_Index_12 48 "Init" ;
VAL_ 2589283415 LAD_CALID_Index_16 48 "Init" ;
VAL_ 2589283415 LAD_CVN_Byte_1 0 "Init" ;
VAL_ 2589283415 LAD_CVN_Byte_2 0 "Init" ;
VAL_ 2589283415 LAD_CVN_Byte_3 0 "Init" ;
VAL_ 2589283415 LAD_CVN_Byte_4 0 "Init" ;
VAL_ 2589283472 LAD_KomponentenFehler_01 0 "TestComplete_PASS" 1 "TestComplete_FAIL" 2 "TestNotComplete_PASS" ;
VAL_ 2589283472 LAD_KomponentenFehler_02 0 "TestComplete_PASS" 1 "TestComplete_FAIL" 2 "TestNotComplete_PASS" ;
VAL_ 2589283472 LAD_KomponentenFehler_03 0 "TestComplete_PASS" 1 "TestComplete_FAIL" 2 "TestNotComplete_PASS" ;
VAL_ 2589283472 LAD_KomponentenFehler_04 0 "TestComplete_PASS" 1 "TestComplete_FAIL" 2 "TestNotComplete_PASS" ;
VAL_ 2589283472 LAD_KomponentenFehler_05 0 "TestComplete_PASS" 1 "TestComplete_FAIL" 2 "TestNotComplete_PASS" ;
VAL_ 2589283472 LAD_KomponentenFehler_06 0 "TestComplete_PASS" 1 "TestComplete_FAIL" 2 "TestNotComplete_PASS" ;
VAL_ 2589283472 LAD_KomponentenFehler_07 0 "TestComplete_PASS" 1 "TestComplete_FAIL" 2 "TestNotComplete_PASS" ;
VAL_ 2589283472 LAD_KomponentenFehler_08 0 "TestComplete_PASS" 1 "TestComplete_FAIL" 2 "TestNotComplete_PASS" ;
VAL_ 2589283472 LAD_KomponentenFehler_09 0 "TestComplete_PASS" 1 "TestComplete_FAIL" 2 "TestNotComplete_PASS" ;
VAL_ 2589283472 LAD_KomponentenFehler_10 0 "TestComplete_PASS" 1 "TestComplete_FAIL" 2 "TestNotComplete_PASS" ;
VAL_ 2589283472 LAD_KomponentenFehler_11 0 "TestComplete_PASS" 1 "TestComplete_FAIL" 2 "TestNotComplete_PASS" ;
VAL_ 2589283472 LAD_KomponentenFehler_12 0 "TestComplete_PASS" 1 "TestComplete_FAIL" 2 "TestNotComplete_PASS" ;
VAL_ 2589283472 LAD_KomponentenFehler_13 0 "TestComplete_PASS" 1 "TestComplete_FAIL" 2 "TestNotComplete_PASS" ;
VAL_ 2589283472 LAD_KomponentenFehler_14 0 "TestComplete_PASS" 1 "TestComplete_FAIL" 2 "TestNotComplete_PASS" ;
VAL_ 2589283472 LAD_KomponentenFehler_15 0 "TestComplete_PASS" 1 "TestComplete_FAIL" 2 "TestNotComplete_PASS" ;
VAL_ 2589283472 LAD_KomponentenFehler_16 0 "TestComplete_PASS" 1 "TestComplete_FAIL" 2 "TestNotComplete_PASS" ;
VAL_ 2589283472 LAD_KomponentenFehler_17 0 "TestComplete_PASS" 1 "TestComplete_FAIL" 2 "TestNotComplete_PASS" ;
VAL_ 2589283472 LAD_KomponentenFehler_18 0 "TestComplete_PASS" 1 "TestComplete_FAIL" 2 "TestNotComplete_PASS" ;
VAL_ 2589283472 LAD_KomponentenFehler_19 0 "TestComplete_PASS" 1 "TestComplete_FAIL" 2 "TestNotComplete_PASS" ;
VAL_ 2589283472 LAD_KomponentenFehler_20 0 "TestComplete_PASS" 1 "TestComplete_FAIL" 2 "TestNotComplete_PASS" ;
VAL_ 2589283472 LAD_KomponentenFehler_21 0 "TestComplete_PASS" 1 "TestComplete_FAIL" 2 "TestNotComplete_PASS" ;
VAL_ 2589283472 LAD_KomponentenFehler_22 0 "TestComplete_PASS" 1 "TestComplete_FAIL" 2 "TestNotComplete_PASS" ;
VAL_ 2589283472 LAD_KomponentenFehler_23 0 "TestComplete_PASS" 1 "TestComplete_FAIL" 2 "TestNotComplete_PASS" ;
VAL_ 2589283472 LAD_KomponentenFehler_24 0 "TestComplete_PASS" 1 "TestComplete_FAIL" 2 "TestNotComplete_PASS" ;
VAL_ 2589283472 LAD_KomponentenFehler_25 0 "TestComplete_PASS" 1 "TestComplete_FAIL" 2 "TestNotComplete_PASS" ;
VAL_ 2589283472 LAD_KomponentenFehler_26 0 "TestComplete_PASS" 1 "TestComplete_FAIL" 2 "TestNotComplete_PASS" ;
VAL_ 2589283472 LAD_KomponentenFehler_27 0 "TestComplete_PASS" 1 "TestComplete_FAIL" 2 "TestNotComplete_PASS" ;
VAL_ 2589283472 LAD_KomponentenFehler_28 0 "TestComplete_PASS" 1 "TestComplete_FAIL" 2 "TestNotComplete_PASS" ;
VAL_ 2589283472 LAD_KomponentenFehler_29 0 "TestComplete_PASS" 1 "TestComplete_FAIL" 2 "TestNotComplete_PASS" ;
VAL_ 2589283472 LAD_KomponentenFehler_30 0 "TestComplete_PASS" 1 "TestComplete_FAIL" 2 "TestNotComplete_PASS" ;
VAL_ 2589283472 LAD_KomponentenFehler_31 0 "TestComplete_PASS" 1 "TestComplete_FAIL" 2 "TestNotComplete_PASS" ;
VAL_ 2589283472 LAD_KomponentenFehler_32 0 "TestComplete_PASS" 1 "TestComplete_FAIL" 2 "TestNotComplete_PASS" ;
VAL_ 2589283473 LAD_KomponentenFehler_33 0 "TestComplete_PASS" 1 "TestComplete_FAIL" 2 "TestNotComplete_PASS" ;
VAL_ 2589283473 LAD_KomponentenFehler_34 0 "TestComplete_PASS" 1 "TestComplete_FAIL" 2 "TestNotComplete_PASS" ;
VAL_ 2589283473 LAD_KomponentenFehler_35 0 "TestComplete_PASS" 1 "TestComplete_FAIL" 2 "TestNotComplete_PASS" ;
VAL_ 2589283473 LAD_KomponentenFehler_36 0 "TestComplete_PASS" 1 "TestComplete_FAIL" 2 "TestNotComplete_PASS" ;
VAL_ 2589283473 LAD_KomponentenFehler_37 0 "TestComplete_PASS" 1 "TestComplete_FAIL" 2 "TestNotComplete_PASS" ;
VAL_ 2589283473 LAD_KomponentenFehler_38 0 "TestComplete_PASS" 1 "TestComplete_FAIL" 2 "TestNotComplete_PASS" ;
VAL_ 2589283473 LAD_KomponentenFehler_39 0 "TestComplete_PASS" 1 "TestComplete_FAIL" 2 "TestNotComplete_PASS" ;
VAL_ 2589283473 LAD_KomponentenFehler_40 0 "TestComplete_PASS" 1 "TestComplete_FAIL" 2 "TestNotComplete_PASS" ;
VAL_ 2589283473 LAD_KomponentenFehler_41 0 "TestComplete_PASS" 1 "TestComplete_FAIL" 2 "TestNotComplete_PASS" ;
VAL_ 2589283473 LAD_KomponentenFehler_42 0 "TestComplete_PASS" 1 "TestComplete_FAIL" 2 "TestNotComplete_PASS" ;
VAL_ 2589283473 LAD_KomponentenFehler_43 0 "TestComplete_PASS" 1 "TestComplete_FAIL" 2 "TestNotComplete_PASS" ;
VAL_ 2589283473 LAD_KomponentenFehler_44 0 "TestComplete_PASS" 1 "TestComplete_FAIL" 2 "TestNotComplete_PASS" ;
VAL_ 2589283473 LAD_KomponentenFehler_45 0 "TestComplete_PASS" 1 "TestComplete_FAIL" 2 "TestNotComplete_PASS" ;
VAL_ 2589283473 LAD_KomponentenFehler_46 0 "TestComplete_PASS" 1 "TestComplete_FAIL" 2 "TestNotComplete_PASS" ;
VAL_ 2589283473 LAD_KomponentenFehler_47 0 "TestComplete_PASS" 1 "TestComplete_FAIL" 2 "TestNotComplete_PASS" ;
VAL_ 2589283473 LAD_KomponentenFehler_48 0 "TestComplete_PASS" 1 "TestComplete_FAIL" 2 "TestNotComplete_PASS" ;
VAL_ 2589283473 LAD_KomponentenFehler_49 0 "TestComplete_PASS" 1 "TestComplete_FAIL" 2 "TestNotComplete_PASS" ;
VAL_ 2589283473 LAD_KomponentenFehler_50 0 "TestComplete_PASS" 1 "TestComplete_FAIL" 2 "TestNotComplete_PASS" ;
VAL_ 2589283473 LAD_KomponentenFehler_51 0 "TestComplete_PASS" 1 "TestComplete_FAIL" 2 "TestNotComplete_PASS" ;
VAL_ 2589283473 LAD_KomponentenFehler_52 0 "TestComplete_PASS" 1 "TestComplete_FAIL" 2 "TestNotComplete_PASS" ;
VAL_ 2589283473 LAD_KomponentenFehler_53 0 "TestComplete_PASS" 1 "TestComplete_FAIL" 2 "TestNotComplete_PASS" ;
VAL_ 2589283473 LAD_KomponentenFehler_54 0 "TestComplete_PASS" 1 "TestComplete_FAIL" 2 "TestNotComplete_PASS" ;
VAL_ 2589283473 LAD_KomponentenFehler_55 0 "TestComplete_PASS" 1 "TestComplete_FAIL" 2 "TestNotComplete_PASS" ;
VAL_ 2589283473 LAD_KomponentenFehler_56 0 "TestComplete_PASS" 1 "TestComplete_FAIL" 2 "TestNotComplete_PASS" ;
VAL_ 2589283473 LAD_KomponentenFehler_57 0 "TestComplete_PASS" 1 "TestComplete_FAIL" 2 "TestNotComplete_PASS" ;
VAL_ 2589283473 LAD_KomponentenFehler_58 0 "TestComplete_PASS" 1 "TestComplete_FAIL" 2 "TestNotComplete_PASS" ;
VAL_ 2589283473 LAD_KomponentenFehler_59 0 "TestComplete_PASS" 1 "TestComplete_FAIL" 2 "TestNotComplete_PASS" ;
VAL_ 2589283473 LAD_KomponentenFehler_60 0 "TestComplete_PASS" 1 "TestComplete_FAIL" 2 "TestNotComplete_PASS" ;
VAL_ 2589283473 LAD_KomponentenFehler_61 0 "TestComplete_PASS" 1 "TestComplete_FAIL" 2 "TestNotComplete_PASS" ;
VAL_ 2589283473 LAD_KomponentenFehler_62 0 "TestComplete_PASS" 1 "TestComplete_FAIL" 2 "TestNotComplete_PASS" ;
VAL_ 2589283473 LAD_KomponentenFehler_63 0 "TestComplete_PASS" 1 "TestComplete_FAIL" 2 "TestNotComplete_PASS" ;
VAL_ 2589283473 LAD_Komponentenfehler_VLD 0 "ungueltig" 1 "gueltig" ;
VAL_ 2589283481 LAD_KomponentenFehler_64 0 "TestComplete_PASS" 1 "TestComplete_FAIL" 2 "TestNotComplete_PASS" ;
VAL_ 2589283481 LAD_KomponentenFehler_65 0 "TestComplete_PASS" 1 "TestComplete_FAIL" 2 "TestNotComplete_PASS" ;
VAL_ 2589283481 LAD_KomponentenFehler_66 0 "TestComplete_PASS" 1 "TestComplete_FAIL" 2 "TestNotComplete_PASS" ;
VAL_ 2589283481 LAD_KomponentenFehler_67 0 "TestComplete_PASS" 1 "TestComplete_FAIL" 2 "TestNotComplete_PASS" ;
VAL_ 2589283481 LAD_KomponentenFehler_68 0 "TestComplete_PASS" 1 "TestComplete_FAIL" 2 "TestNotComplete_PASS" ;
VAL_ 2589283481 LAD_KomponentenFehler_69 0 "TestComplete_PASS" 1 "TestComplete_FAIL" 2 "TestNotComplete_PASS" ;
VAL_ 2589283481 LAD_KomponentenFehler_70 0 "TestComplete_PASS" 1 "TestComplete_FAIL" 2 "TestNotComplete_PASS" ;
VAL_ 2589283481 LAD_KomponentenFehler_71 0 "TestComplete_PASS" 1 "TestComplete_FAIL" 2 "TestNotComplete_PASS" ;
VAL_ 2589283481 LAD_KomponentenFehler_72 0 "TestComplete_PASS" 1 "TestComplete_FAIL" 2 "TestNotComplete_PASS" ;
VAL_ 2589283481 LAD_KomponentenFehler_73 0 "TestComplete_PASS" 1 "TestComplete_FAIL" 2 "TestNotComplete_PASS" ;
VAL_ 2589283481 LAD_KomponentenFehler_74 0 "TestComplete_PASS" 1 "TestComplete_FAIL" 2 "TestNotComplete_PASS" ;
VAL_ 2589283481 LAD_KomponentenFehler_75 0 "TestComplete_PASS" 1 "TestComplete_FAIL" 2 "TestNotComplete_PASS" ;
VAL_ 160 EPS_Lenkmoment_AbsReduz 13 "MAX" 14 "Init" 15 "Fehler" ;
VAL_ 160 EPS_FAS_Regelgroesse 62 "Init" 63 "Fehler" ;
VAL_ 160 EPS_FAS_VZ_Regelgroesse 0 "positiv" 1 "negativ" ;
VAL_ 160 EPS_Zahnstangen_Pos 4094 "Init" 4095 "Fehler" ;
VAL_ 160 EPS_VZ_Zahnstangenposition 0 "pos_VZ" 1 "neg_VZ" ;
VAL_ 160 EPS_QBit_Zahnstangen_Pos 0 "gueltiger_Wert" 1 "Ersatz_Init_oder_Fehlerwert" ;
VAL_ 160 EPS_Versorgungsstatus 0 "kein_Fehler" 1 "Unterspannung" 2 "Ueberspannung" 3 "Stoerung" ;
VAL_ 160 EPS_Versorgungsspannung 254 "Init" 255 "Fehler" ;
VAL_ 160 EPS_AWA_Status 0 "AWA_deaktiviert" 1 "AWA_Anf_nicht_ausfuehrbar" 2 "Kom_AWA_gestoert" 3 "EPS_bzgl_AWA_funktionsbereit" 4 "AWA_Anf_abgew" 5 "AWA_Momeingriff_1_aktiv" 6 "reserviert" 7 "AWA_Momeingriff_2_aktiv" 8 "AWA_abgewiesen_aufgrund_Momentenpriorisierung" 9 "Anf_abgewiesen_Bedienueblich" 14 "Init" ;
VAL_ 160 EPS_STA_Status 0 "STA_bzw_STP_deaktiviert" 1 "Anf_nicht_ausfuehrbar" 2 "Kommunikationsfehler" 3 "EPS_bzgl_STA_bzw_STP_funktionsbereit" 4 "Anf_abgewiesen_Fehler" 5 "gesperrt" 6 "STA_bzw_STP_Winkeleingriff_aktiv" 7 "gesperrt" 8 "Anf_abgewiesen_Prio" 9 "Anf_abgewiesen_Bedienueblich" 10 "Winkeleingriff_abgebrochen" 11 "Rueckfallmodus_Winkeleingriff" 12 "Notlauf_Winkelregelung_aktiv" 14 "Init" 15 "Schnittstellendeaktiverung_UEF" ;
VAL_ 1600 MO_QBit_Ansaugluft_Temp 0 "gueltiger_Wert" 1 "Ersatz_Init_oder_Fehlerwert" ;
VAL_ 1600 MO_QBit_Oel_Temp 0 "gueltiger_Wert" 1 "Ersatz_Init_oder_Fehlerwert" ;
VAL_ 1600 MO_QBit_Kuehlmittel_Temp 0 "gueltiger_Wert" 1 "Ersatz_Init_oder_Fehlerwert" ;
VAL_ 1600 MO_KL15_Abschaltempfehlung 0 "Keine Empfehlung" 1 "Abschaltempfehlung" ;
VAL_ 1600 MO_HYB_Fehler_HV_Netz 0 "i_O" 1 "kein_generatorischer_Betrieb_moeglich" ;
VAL_ 1600 MO_aktives_Getriebeheizen 0 "kein_Ventil_ansteuern" 1 "Ventil_muss_angesteuert_werden" ;
VAL_ 1600 MO_Absperrventil_oeffnen 0 "nicht_verfuegbar" 1 "Ansteuerung_Ventil_zulaessig" 2 "Ventil_oeffnen_oder_geoeffnet" 3 "Ventil_schliessen_oder_geschlossen" ;
VAL_ 1600 MO_Ansaugluft_Temp 254 "Init" 255 "Fehler" ;
VAL_ 1600 MO_Oel_Temp 253 "nicht_verbaut" 254 "Init" 255 "Fehler" ;
VAL_ 1600 MO_Kuehlmittel_Temp 254 "Init" 255 "Fehler" ;
VAL_ 1600 MO_Hoeheninfo 255 "Fehler" ;
VAL_ 1600 MO_Kennfeldk 0 "keine Kennfeldkühlung vorhanden" 1 "Kennfeldkühlung vorhanden" ;
VAL_ 1600 MO_Versionsinfo_02 0 "zum_Projektbeginn_aufgeraeumter_CAN" 1 "Motor_03_mit_10ms" 16 "MQB_mit_neuer_Momentenschnittstelle" ;
VAL_ 1600 MO_QBit_Hoeheninfo 0 "gueltiger_Wert" 1 "Ersatz_Init_oder_Fehlerwert" ;
VAL_ 1600 MO_Getriebe_kuehlen 0 "nicht_kuehlen" 1 "kuehlen" ;
VAL_ 1600 MO_Heizungspumpenansteuerung 13 "Fehler" 14 "Init" 15 "nicht_verbaut" ;
VAL_ 1600 MO_SpannungsAnf 0 "keine_Anforderung" 1 "Anforderung" ;
VAL_ 1607 MO_ITM_Kuehlmittel_Temp 0 "nicht_verbaut" 1 "Init" 2 "Fehler" ;
VAL_ 1607 MO_E85_Sensor 13 "nicht_verbaut" 14 "Init" 15 "Fehler" ;
VAL_ 1607 SCR_Anz_Motorstarts 0 "Anzahl_moeglicher_Restarts" 1 "Anzahl_moeglicher_Restarts" 2 "Anzahl_moeglicher_Restarts" 3 "Anzahl_moeglicher_Restarts" 4 "Anzahl_moeglicher_Restarts" 5 "Anzahl_moeglicher_Restarts" 6 "Anzahl_moeglicher_Restarts" 7 "Anzahl_moeglicher_Restarts" 8 "Anzahl_moeglicher_Restarts" 9 "Anzahl_moeglicher_Restarts" 10 "Anzahl_moeglicher_Restarts" 11 "Anzahl_moeglicher_Restarts" 12 "Anzahl_moeglicher_Restarts" 13 "Anzahl_moeglicher_Restarts" 14 "Fahrbarkeitseinschraenkung" 15 "keine_Einschraenkung" ;
VAL_ 1607 SCR_Reichweite 32767 "keine_Anzeige" ;
VAL_ 1607 MO_Ethanol_Spuelhinweis 0 "Kein_Hinweis" 1 "Spuelhinweis_aktiv" ;
VAL_ 1607 SCR_Warnstufe_1 0 "nicht_aktiv" 1 "Warnstufe_1_aktiv" ;
VAL_ 1607 SCR_Warnstufe_2 0 "nicht_aktiv" 1 "Warnstufe_2_aktiv" ;
VAL_ 1607 SCR_Text 0 "kein_Text" 1 "Warntext_1" 2 "Warntext_2" 3 "Hinweis_Fuellstand" 4 "Reserve" 5 "SysFehler_1" 6 "SysFehler_2" 7 "Hinweis_Systemfehler" ;
VAL_ 1607 SCR_Akustik 0 "keine_Akustik" 1 "Akustik_1" 2 "Akustik_2" 3 "Akustik_bei_Hinweis" ;
VAL_ 1607 SCR_verbaut 0 "kein_SCR" 1 "SCR_verbaut" ;
VAL_ 1607 MO_Kraftstofffilter_Wasser 0 "keine_Anzeige" 1 "Abscheidevolumen_erschoepft" ;
VAL_ 1607 SCR_Systemfehler 0 "Warnung_nicht_aktiv" 1 "Warnung_aktiv" ;
VAL_ 1607 SCR_Inducement_Strategie 0 "Restart_Strategie" 1 "Reduced_Drivability_Strategie" ;
VAL_ 1607 MO_CO2_Faktor 0 "nicht_verbaut" 4095 "Fehler" ;
VAL_ 1607 MO_MKB_MUX 0 "MKB_01" 1 "MKB_02" 2 "MKB_03" 3 "MKB_04" ;
VAL_ 1607 MO_MKB_01 0 "Minus" 1 "A" 2 "B" 3 "C" 4 "D" 5 "E" 6 "F" 7 "G" 8 "H" 9 "I" 10 "J" 11 "K" 12 "L" 13 "M" 14 "N" 15 "O" 16 "P" 17 "Q" 18 "R" 19 "S" 20 "T" 21 "U" 22 "V" 23 "W" 24 "X" 25 "Y" 26 "Z" 27 "Leerzeichen" 28 "Leerzeichen" 29 "Leerzeichen" 30 "Leerzeichen" 31 "Unterstrich" ;
VAL_ 1607 MO_MKB_02 0 "Minus" 1 "A" 2 "B" 3 "C" 4 "D" 5 "E" 6 "F" 7 "G" 8 "H" 9 "I" 10 "J" 11 "K" 12 "L" 13 "M" 14 "N" 15 "O" 16 "P" 17 "Q" 18 "R" 19 "S" 20 "T" 21 "U" 22 "V" 23 "W" 24 "X" 25 "Y" 26 "Z" 27 "Leerzeichen" 28 "Leerzeichen" 29 "Leerzeichen" 30 "Leerzeichen" 31 "Unterstrich" ;
VAL_ 1607 MO_MKB_03 0 "Minus" 1 "A" 2 "B" 3 "C" 4 "D" 5 "E" 6 "F" 7 "G" 8 "H" 9 "I" 10 "J" 11 "K" 12 "L" 13 "M" 14 "N" 15 "O" 16 "P" 17 "Q" 18 "R" 19 "S" 20 "T" 21 "U" 22 "V" 23 "W" 24 "X" 25 "Y" 26 "Z" 27 "Leerzeichen" 28 "Leerzeichen" 29 "Leerzeichen" 30 "Leerzeichen" 31 "Unterstrich" ;
VAL_ 1607 MO_MKB_04 0 "Minus" 1 "A" 2 "B" 3 "C" 4 "D" 5 "E" 6 "F" 7 "G" 8 "H" 9 "I" 10 "J" 11 "K" 12 "L" 13 "M" 14 "N" 15 "O" 16 "P" 17 "Q" 18 "R" 19 "S" 20 "T" 21 "U" 22 "V" 23 "W" 24 "X" 25 "Y" 26 "Z" 27 "Leerzeichen" 28 "Leerzeichen" 29 "Leerzeichen" 30 "Leerzeichen" 31 "Unterstrich" ;
VAL_ 168 MO_Mom_neg_verfuegbar 510 "Init" 511 "Fehler" ;
VAL_ 168 MO_Mom_Begr_stat 510 "Init" ;
VAL_ 168 MO_Mom_Begr_dyn 1022 "Init" ;
VAL_ 168 MO_QBit_Drehzahl_01 0 "gueltiger_Wert" 1 "Ersatz_Init_oder_Fehlerwert" ;
VAL_ 958 MO_StartStopp_Status 0 "System_in_diesem_KL15_Zyklus_nicht_verfuegbar" 1 "System_aktiv_keine_Freigabe_durch_StartStop_Koordinator" 2 "System_aktiv_alle_Freigaben_liegen_vor" 3 "System_aktiv_mindestens_eine_Freigabe_fehlt" ;
VAL_ 958 MO_StartStopp_Wiederstart 0 "Wiederstart_inaktiv" 1 "Wiederstart_aktiv" ;
VAL_ 958 MO_StartStopp_Motorstopp 0 "Motor_Stop_inaktiv" 1 "Motor_Stop_aktiv" ;
VAL_ 958 MO_Freig_Reku 0 "Rekuperations-Modus aus" 1 "Empfehlung Spannungsanhebung" 2 "Empfehlung Spannungsabsenkung" 3 "Rekuperationsmodus aktiv, Spannungsvariation nicht notwendig" ;
VAL_ 958 MO_Kl_75 0 "Aus" 1 "Ein" ;
VAL_ 958 MO_Kl_50 0 "aus" 1 "KL50_ein_Startausfuehrung_Fahrer" ;
VAL_ 958 MO_Gangposition 0 "Gang_N" 1 "Gang_1" 2 "Gang_2" 3 "Gang_3" 4 "Gang_4" 5 "Gang_5" 6 "Gang_6" 7 "Gang_7" 8 "Gang_8" 9 "Automat_P" 10 "Automat_Vorwaerts_S" 11 "Automat_Vorwaerts_D/E" 12 "Zwischenstellung" 13 "Gang_R" 14 "Istgang_nicht_definiert" 15 "Fehler" ;
VAL_ 958 MO_StartStopp_Fahrerwunsch 0 "Init" 1 "Stoppverbot_durch_Fahrer" 2 "Stoppfreigabe_durch_Fahrer" 3 "Stoppanforderung_durch_Fahrer" ;
VAL_ 958 MO_HYB_Fahrbereitschaft 0 "keine_Fahrbereitschaft" 1 "Fahrbereitschaft" ;
VAL_ 958 MO_Ext_E_Fahrt_aktiv 0 "Rueckmeldung_E_Taster_aus" 1 "Rueckmeldung_E_Taster_ein" ;
VAL_ 958 MO_Fahrer_bremst 0 "kein_Bremsen" 1 "Bremse_betaetigt" ;
VAL_ 958 MO_QBit_Fahrer_bremst 0 "gueltiger_Wert" 1 "Ersatz_Init_oder_Fehlerwert" ;
VAL_ 958 MO_BLS 0 "kein_Bremsen" 1 "Bremse_betaetigt" ;
VAL_ 958 MO_Konsistenz_Bremsped 0 "Bremspedalinformation_plausibel" 1 "Bremspedalinformation_unplausibel" ;
VAL_ 958 MO_KomFehler_ESP 0 "kein_Fehler" 1 "Fehler" ;
VAL_ 958 MO_Klima_Eingr 0 "kein Eingriff" 1 "Klimakompressor ausschalten" 2 "Klimakompressor Leistungsreduzierung" 3 "Klimakompressor aufgrund der Heissleuchtenvorwarnung ausschalten" ;
VAL_ 958 MO_Aussp_Anlass 0 "Anlasser_darf_angesteuert_werden" 1 "Anlasser_ausspuren__Ansteuerung_nicht_moeglich" ;
VAL_ 958 MO_Freig_Anlass 0 "Start_nicht_zulaessig" 1 "Startfreigabe" ;
VAL_ 958 MO_Kuppl_schalter 0 "Schalter_sagt_ausgekuppelt" 1 "Schalter_sagt_eingekuppelt" ;
VAL_ 958 MO_Interlock 0 "Interlockschalter_nicht_betaetigt" 1 "Interlockschalter_betaetigt" ;
VAL_ 958 MO_Motor_laeuft 0 "Motor_laeuft_nicht" 1 "Motor_laeuft_autark_und_stabil_und_darf_mechanisch_belastet_werden" ;
VAL_ 958 MO_Kickdown 0 "kein_Kickdown" 1 "Kickdown" ;
VAL_ 958 MO_QBit_KL_75 0 "gueltiger_Wert" 1 "Ersatz_Init_oder_Fehlerwert" ;
VAL_ 958 MO_EKlKomLeiRed 0 "keine_Leistungsbegr" 1 "Leistungsbegr_75" 2 "Leistungsbegr_50" 3 "Leistungsbegr_25" ;
VAL_ 958 MO_Handshake_STH 0 "keine EKP-Ansteuerung durch STH-Anforderung" 1 "EKP-Ansteuerung durch STH-Anforderung" ;
VAL_ 958 MO_BKV_Unterdruckwarnung 0 "Unterdruckhaushalt_iO" 1 "Unterdruckhaushalt_niO" ;
VAL_ 958 MO_Freigabe_Segeln 0 "Segelbetrieb_nicht_freigegeben" 1 "Segelbetrieb_freigegeben" ;
VAL_ 958 MO_PTC_Status 0 "nicht_unterstuetzt" 1 "Stufe_0" 2 "Stufe_1" 3 "Stufe_2" 4 "Stufe_3" 7 "PTC_am_BCM" ;
VAL_ 958 MO_QBit_Gangposition 0 "gueltiger_Wert" 1 "Ersatz_Init_oder_Fehlerwert" ;
VAL_ 958 MO_Signalquelle_Gangposition 0 "Sensorsignal" 1 "Modellsignal" ;
VAL_ 958 MO_Remotestart_Betrieb 0 "MSG_nicht_bereit_fuer_RS_Betrieb" 1 "MSG_bereit_fuer_oder_im_RS_Betrieb" ;
VAL_ 958 MO_Remotestart_moeglich 0 "Remotestart_nicht_moeglich" 1 "Remotestart_moeglich" ;
VAL_ 958 MO_FMAus_aktiv 0 "inaktiv" 1 "Segeln_mit_Motor_aus_aktiv" ;
VAL_ 958 MO_FMAus_Startvariante 0 "kein_Motorstart" 1 "Motorstart_elektrischer_Starter" 2 "GetriebeAnschleppstart" 3 "GetriebeNotAnschleppstart" ;
VAL_ 958 MO_BMS_NV_Anf_stuetzen 0 "nicht_notwendig" 1 "notwendig" ;
VAL_ 958 MO_Zylinderabschaltung 0 "Vollmotorbetrieb_VMB" 1 "Uebergang_HMB_in_VMB" 2 "Uebergang_VMB_in_HMB" 3 "Halbmotorbetrieb_HMB" ;
VAL_ 958 MO_HYB_VM_aktiv 0 "VM_nicht_aktiv" 1 "VM_aktiv" ;
VAL_ 958 MO_StartVorauss_erfuellt 0 "Signal_nicht_bedient" 1 "StartVorauss_nicht_ueberpruefbar" 2 "StartVorauss_nicht_erfuellt" 3 "StartVorauss_erfuellt" ;
VAL_ 812 MO_Sperrung_FahrPr_BZS 0 "keine Sperrung" 1 "Sperrung BZS1" 2 "Sperrung BZS2" 4 "Sperrung BZS3" 8 "Sperrung BZS4" 16 "Sperrung BZS5" 32 "Sperrung BZS6" 64 "Sperrung BZS7" 128 "Sperrung BZS8" ;
VAL_ 812 MO_Rampenzeit_Generator_Anf 0 "0_sec" 1 "1_sec" 2 "2_sec" 3 "3_sec" 4 "4_sec" 5 "5_sec" 6 "6_sec" 7 "7_sec" 8 "8_sec" 9 "9_sec" 10 "reserviert" 11 "reserviert" 12 "reserviert" 13 "reserviert" 14 "reserviert" 15 "keine_Anforderung" ;
VAL_ 812 MO_Prio_MAX_Wunschdrehzahl 0 "Wunsch" 1 "Zwang" ;
VAL_ 812 MO_Prio_MIN_Wunschdrehzahl 0 "Wunsch" 1 "Zwang" ;
VAL_ 812 MO_Luftpfad_aktiv 0 "kein Eingriff oder nur Eingriff über Zündpfad" 1 "Eingriff über Luftpfad" ;
VAL_ 812 MO_v_Begrenz_Aktivierbar 0 "V-Begrenzung nicht möglich" 1 "V-Begrenzung möglich" ;
VAL_ 812 MO_Charisma_FahrPr 0 "keine_Funktion" 1 "Programm_1" 2 "Programm_2" 3 "Programm_3" 4 "Programm_4" 5 "Programm_5" 6 "Programm_6" 7 "Programm_7" 8 "Programm_8" 9 "Programm_9" 10 "Programm_10" 11 "Programm_11" 12 "Programm_12" 13 "Programm_13" 14 "Programm_14" 15 "Programm_15" ;
VAL_ 812 MO_Charisma_Status 0 "Init" 1 "verfuegbar" 2 "nicht_verfuegbar" 3 "asynchron_durch_Fahrerwunsch" ;
VAL_ 812 MO_StSt_Charisma_FahrPr 0 "keine_Funktion" 1 "Programm_1" 2 "Programm_2" 3 "Programm_3" 4 "Programm_4" 5 "Programm_5" 6 "Programm_6" 7 "Programm_7" 8 "Programm_8" 9 "Programm_9" 10 "Programm_10" 11 "Programm_11" 12 "Programm_12" 13 "Programm_13" 14 "Programm_14" 15 "Programm_15" ;
VAL_ 812 MO_StSt_Charisma_Status 0 "Init" 1 "verfuegbar" 2 "nicht_verfuegbar" 3 "asynchron_durch_Fahrerwunsch" ;
VAL_ 812 MO_BZS_Charisma_FahrPr 0 "keine_Funktion" 1 "Programm_1" 2 "Programm_2" 3 "Programm_3" 4 "Programm_4" 5 "Programm_5" 6 "Programm_6" 7 "Programm_7" 8 "Programm_8" 9 "Programm_9" 10 "Programm_10" 11 "Programm_11" 12 "Programm_12" 13 "Programm_13" 14 "Programm_14" 15 "Programm_15" ;
VAL_ 812 MO_BZS_Charisma_Status 0 "Init" 1 "verfuegbar" 2 "nicht_verfuegbar" 3 "asynchron_durch_Fahrerwunsch" ;
VAL_ 812 MO_NGS_Position 0 "Neutralposition_nicht_erkannt" 1 "Neutralposition_erkannt" ;
VAL_ 812 MO_NGS_Status 0 "nicht_verbaut" 1 "nicht_plausibilisiert" 2 "plausibilisiert" 3 "Fehler" ;
VAL_ 812 MO_v_Begrenzung_Niveau 0 "keine_Begrenzung_aktiv" 1 "Sicherheitsbegrenzung_1_aktiv" 2 "Sicherheitsbegrenzung_2_aktiv" 3 "Komfortbegrenzung_aktiv" ;
VAL_ 1648 MO_ANC_Kennfeld_Anf 0 "Kennfeld_1" 1 "Uebergang_Kennfeld_2_nach_1" 2 "Uebergang_Kennfeld_1_nach_2" 3 "Kennfeld_2" ;
VAL_ 1648 MO_Bremslicht_Reku 0 "Aus" 1 "Ein" ;
VAL_ 1648 MO_StartStopp_PopUp 0 "Statuswechsel_ohne_Taster (Init)" 1 "StSt_per_Taster_deaktiviert" 2 "StSt_per_Taster_aktiviert" 3 "nicht verwendet" ;
VAL_ 1648 MO1_Sperr_Info_WFS 0 "nicht_gesperrt" 1 "gesperrt" ;
VAL_ 1648 MO1_Freigabe_Info_WFS 0 "ungueltig" 1 "gueltig" ;
VAL_ 1648 MO_EPCL 0 "EPCL_aus_kein_Text" 1 "EPCL_gelb_Stoerung" 2 "EPCL_gelb_Leistungsbeschraenkung" 3 "EPCL_rot_Fzg_sicher_abstellen" ;
VAL_ 1648 MO_Zylabsch_Texte_02 0 "ein_ZAS_generell_keine_ZAS_Anzeigen" 1 "ZAS_im_VMB" 2 "ZAS_im_ASB_1_Zyl_aktiv" 3 "ZAS_im_ASB_2_Zyl_aktiv" 4 "ZAS_im_ASB_3_Zyl_aktiv" 5 "ZAS_im_ASB_4_Zyl_aktiv" 6 "ZAS_im_ASB_5_Zyl_aktiv" 7 "ZAS_im_ASB_6_Zyl_aktiv" 8 "ZAS_im_ASB_8_Zyl_aktiv" 9 "ZAS_im_ASB_12_Zyl_aktiv" 13 "Uebergangsbetrieb" 14 "keine_ZAS_Anzeige_ggf_Stopp_Schub_Betrieb" 15 "ZAS_Stoerungs_Anzeige" ;
VAL_ 1648 MO_Fahrzeugtyp 0 "Verbrenner_Fahrzeug" 1 "Hybrid" 2 "E_Fahrzeug" 3 "E_Fahrzeug_mit_Range_Extender" 4 "Brennstoffzellenfahrzeug" 5 "tbd" 6 "tbd" 7 "tbd" ;
VAL_ 1648 MO_Abstellzeit 254 "Init" 255 "reserviert" ;
VAL_ 1648 MO_Abstellzeit_Status 0 "Abstellzeit_nicht_berechnet" 1 "Abstellzeit_berechnet" 2 "Abstellzeit_Minimalwert" 3 "Abstellzeit_ungueltig" ;
VAL_ 1648 MO1_Freigabe_Verfallsinfo_WFS 0 "verfaellt_nicht" 1 "verfaellt" ;
VAL_ 1648 MO_Hybrid_StartStopp_LED 0 "LED_aus_und_Blinken_aus" 1 "LED_ein_und_Blinken_aus" 2 "LED_ein_und_Blinken_ein_50_percent" 3 "reserviert" ;
VAL_ 1648 MO_Fehler_Zylabsch 0 "kein_Fehler" 1 "Notlauf_Vollmotorbetrieb" 2 "Notlauf_mindestens_einem_abgesch_Zylinder" ;
VAL_ 1648 MO_Anzahl_Abgesch_Zyl 0 "Vollmotorbetrieb" 1 "1_Zylinder_abgeschaltet" 2 "2_Zylinder_abgeschaltet" 3 "3_Zylinder_abgeschaltet" 4 "4_Zylinder_abgeschaltet" 5 "5_Zylinder_abgeschaltet" 6 "6_Zylinder_abgeschaltet" 7 "8_Zylinder_abgeschaltet" ;
VAL_ 1648 MO_Zylabsch_Texte 0 "keine_Texte" 1 "Zylinderabschaltung_deaktivieren" 2 "Zylinderabschaltung_aktivieren" 3 "Zylinderabschaltung_unruhig" ;
VAL_ 1648 MO_Ethanol_BS_Texte 0 "kein_Text" 1 "E85_Warm_Up" 2 "FlexFuel_Warnung_Stufe_3" 3 "Warmfahrempfehlung_MQB__FlexFuel_Warnung_Stufe_1" 4 "FlexFuel_Warnung_Stufe_2" 5 "FlexFuel_Warnung_Stufe_4" 6 "E25_Warm_Up" ;
VAL_ 1648 MO_Drehzahl_Warnung 0 "keinen_Warnhinweis_anzeigen" 1 "Warnhinweis_anzeigen" ;
VAL_ 1648 MO_obere_Drehzahlgrenze 0 "Init" ;
VAL_ 1423 MO_ITM_Status 0 "stehendes_Wasser" 1 "kein_stehendes_Wasser" 2 "Entnahmegrenze_20_Grad_Celsius" 3 "Entnahmegrenze_30_Grad_Celsius" 4 "Entnahmegrenze_40_Grad_Celsius" 5 "Entnahmegrenze_50_Grad_Celsius" 6 "Entnahmegrenze_60_Grad_Celsius" 7 "keine_Entahme_erlaubt" 14 "Init" 15 "Fehler" ;
VAL_ 1423 MO_Tankdruck 254 "Init" 255 "Fehler" ;
VAL_ 1423 MO_Kuehlmittel_Temp_Rohwert 254 "Init" 255 "Fehler" ;
VAL_ 1423 MO_Oel_Temp_Radsatz 254 "Initialwert" 255 "Fehler" ;
VAL_ 1423 MO_KJS_LLK_Pos_Summe 14 "Init" 15 "Pos_Frontendverschl_ungenau" ;
VAL_ 1423 MO_FSA_Sensorheizung 0 "inaktiv" 1 "aktiv" ;
VAL_ 1423 FSA_Fehlerpfade_Initialisieren 0 "inaktiv" 1 "aktiv" ;
VAL_ 967 MO_Kuehlerluefter_MUX 0 "Kuehlerluefter_1" 1 "Kuehlerluefter_2" ;
VAL_ 967 MO_Kuehlerluefter_1 126 "Init" 127 "Fehler" ;
VAL_ 967 MO_Kuehlerluefter_2 126 "Init" 127 "Fehler" ;
VAL_ 967 MO_EFLEX_Lampe 0 "Lampe_aus" 1 "Lampe_ein" 2 "Lampe_blinkend" 3 "Lampe_blinkend_mit_Akustik" ;
VAL_ 967 MO_KJS_nicht_bereit 0 "kein_Fehler" 1 "Fehler" ;
VAL_ 967 MO_ITM_Warnung_Pumpe 0 "keine_Warnung" 1 "ITM_Warnung" ;
VAL_ 967 WIV_Anzeige_aktiv 0 "Anzeige aus" 1 "WIV Anzeige aktiv" ;
VAL_ 967 WIV_Oelmin_Warn 0 "in_Ordnung" 1 "Warnung" ;
VAL_ 967 WIV_Sensorfehler 0 "in_Ordnung" 1 "Sensor_defekt" ;
VAL_ 967 WIV_Schieflage 0 "Fahrzeug_gerade" 1 "Fahrzeug_in_Schieflage" ;
VAL_ 967 MO_Zustand_HWP 0 "HWP_nicht_schaltbar" 1 "HWP_foerdert_nicht" 2 "HWP_foerdert" 3 "reserviert" ;
VAL_ 967 OLEV_Systemstoerung 0 "Ölsystem i.O." 1 "Systemstörung Ölsystem" ;
VAL_ 967 MO_Oelwarnung_max 0 "keine_Warnung" 1 "Warnfall_aktiv" ;
VAL_ 967 WIV_Oelsystem_aktiv 0 "Anzeige_aus" 1 "Anzeige_aktiv" ;
VAL_ 967 WIV_nicht_betriebswarm 0 "Motor_warm" 1 "Motor_nicht_betriebswarm" ;
VAL_ 967 WIV_Ueberfuell_Warn 0 "in_Ordnung" 1 "Ueberfuellwarnung" ;
VAL_ 967 WIV_laufender_Motor 0 "Messung_moeglich" 1 "Messung_nicht_moeglich" ;
VAL_ 967 MO_E_Warnungen 0 "keine_Anzeige" 1 "Fehler_Elektrosystem_Anhalten" 2 "Fehler_Elektrosystem_Werkstatt" 3 "Elektrosystem_ueberhitzt_Stopp" 4 "Fehler_Hybridsystem_Anhalten" 5 "Fehler_Hybridsystem_Werkstatt" 6 "Fehler_Wasserstoffsystem_Anhalte" 7 "Fehler_Wasserstoffsystem_Werksta" 8 "reserviert_keine_Anzeige" 9 "reserviert_keine_Anzeige" 10 "reserviert_keine_Anzeige" 11 "reserviert_keine_Anzeige" 12 "reserviert_keine_Anzeige" 13 "reserviert_keine_Anzeige" 14 "reserviert_keine_Anzeige" 15 "reserviert_keine_Anzeige" ;
VAL_ 967 MO_Text_Motorstart 0 "keine_Anzeige" 1 "Motor_im_Stoppbetrieb" 2 "StartStopp_sicherheitsbedingt_deaktiviert" 3 "System_fordert_Wiederstart" 4 "Aufforderung_Motorstart" 5 "Motorlauf_noetig" 6 "Motorlaufwarnung" 9 "Unerwuenschter_Motorstillstand" 11 "Fehler_Kupplungsschalter" 12 "Motor_startet" 13 "Kupplung_betaetigen" 14 "Waehlhebel_in_PN_Position" 15 "Bremse_treten" ;
VAL_ 967 MO_E_Texte 0 "keine_Anzeige" 1 "Batterie_fast_leer" 2 "Ladestecker_nicht_fahrbereit" 3 "VM_Betrieb_erforderlich" 4 "Batterie_laedt_Nicht_ausschalten" 5 "Bitte_Bremse_treten" 6 "manueller_Neustart_erforderlich" 7 "Stopp_Fahrzeug_nicht_abschleppen" 8 "kein_Neustart_Haube_nicht_oeffnen" 9 "Motorstart_im_naechsten_Zyklus" 10 "VM_erforderlich_EVMode_abwaehlen" 11 "laengerer_VMBetrieb_Bordbuch" 12 "Tank_leer_VM_nicht_verfuegbar" 13 "Bitte_warten_Motor_startet" 14 "kein_Start_Batterietemperatur" 15 "Ende_elektrische_Reichweite_erreicht" ;
VAL_ 967 WIV_Oeldyn_avl 0 "Oeldyn_nicht_vorhanden" 1 "Oeldyn_vorhanden" ;
VAL_ 967 OLEV_Oelstand_nicht_vorhanden 0 "Ölstand vorhanden" 1 "Ölstand nicht vorhanden" ;
VAL_ 967 MO_Systemlampe 0 "Lampe aus" 1 "Lampe ein" ;
VAL_ 967 MO_OBD2_Lampe 0 "Lampe aus" 1 "Lampe ein" ;
VAL_ 967 MO_Heissleuchte 0 "Lampe aus" 1 "Lampe ein" ;
VAL_ 967 MO_Partikel_Lampe 0 "Lampe aus" 1 "Lampe ein" ;
VAL_ 967 MO_RedFahrleistung_Lampe 0 "Lampe_aus" 1 "Lampe_ein" ;
VAL_ 967 WIV_Oelstand_nicht_vorhanden 0 "Ölstand vorhanden" 1 "Ölstand nicht vorhanden" ;
VAL_ 967 WIV_nachfuellanzeige_ein 0 "keine_Nachfuellanzeige" 1 "Nachfuellanzeige" ;
VAL_ 967 WIV_Ueberfuell_deaktiv 0 "Ueberfuellwarnung_am_Kombi_aktiv" 1 "Ueberfuellwarnung_am_Kombi_deaktiv" ;
VAL_ 967 WIV_Unterfuell_Warn 0 "in_Ordnung" 1 "Unterfuellwarnung" ;
VAL_ 967 MO_Tankdeckel_Lampe 0 "Lampe aus" 1 "Lampe ein" ;
VAL_ 967 MO_Text_Tankdeckelwarn 0 "kein_Text" 1 "Anzeige_Text_Tankdeckelwarnung_im_Kombi" ;
VAL_ 967 MO_Vorglueh_Lampe 0 "Lampe_aus" 1 "Lampe_ein" ;
VAL_ 967 WIV_Oeldr_Warn_Motor 0 "keine_Warnung" 1 "niedrige_Oeldruckstufe_nicht_erreicht" ;
VAL_ 967 MO_E_Mode 0 "keine_Anzeige" 1 "E_Mode_passiv" 2 "E_Mode_aktiv" 3 "E_Mode_inaktiv_nicht_verfuegbar" 4 "E_Mode_aktiv_nicht_verfuegbar" 5 "reserviert_keine_Anzeige" 6 "reserviert_keine_Anzeige" 7 "reserviert_keine_Anzeige" ;
VAL_ 340 MO_IstMoment_VKM 1022 "Init" ;
VAL_ 340 MO_Mom_Begr_Schalt 1022 "Init" ;
VAL_ 340 MO_Mom_Begr_Schalt_Min 1022 "Init" ;
VAL_ 340 MO_Fehlerstatus_Antrieb_FDR 0 "FDR_Normalbetrieb" 1 "FDR_abschalten" 2 "FDR_Regelung_beenden" 3 "FDR_abschalten_temporaer" 4 "FDR_Regelung_temporaer_beenden" ;
VAL_ 340 MO_Primaerachse_Anforderung 0 "Init_Freilaufsteuerung_MSG" 1 "Anforderung_Abkoppeln" 2 "Anforderung_Ankoppeln" ;
VAL_ 1366 MO_Fahrzeugabstellzeit_Status 0 "Abstellzeit_nicht_berechnet" 1 "Abstellzeit_berechnet" 2 "Abstellzeit_Minimalwert" 3 "Abstellzeit_ungültig" ;
VAL_ 1366 MO_HV_Auszeit_Status 0 "Abstellzeit_nicht_berechnet" 1 "Abstellzeit_berechnet" 2 "Abstellzeit_Minimalwert" 3 "Abstellzeit_ungültig" ;
VAL_ 1366 MO_Fahrzeugabstellzeit 254 "Init" 255 "Fehler" ;
VAL_ 1366 MO_HV_Auszeit 510 "Init" 511 "Fehler" ;
VAL_ 1366 MO_Verbau_StartSys_Ritzelstarter 0 "nicht_verbaut" 1 "verbaut" ;
VAL_ 1366 MO_Verbau_StartSys_EM_MV 0 "nicht_verbaut" 1 "verbaut" ;
VAL_ 1366 MO_Verbau_StartSys_EM_HV 0 "nicht_verbaut" 1 "verbaut" ;
VAL_ 1366 MO_Verbau_StartSys_RSG_NV 0 "nicht_verbaut" 1 "verbaut" ;
VAL_ 1366 MO_Verbau_StartSys_Q_Diode 0 "nicht_verbaut" 1 "verbaut" ;
VAL_ 1366 MO_Verbau_StartSys_RSG_MV 0 "nicht_verbaut" 1 "verbaut" ;
VAL_ 1366 FWS_QBit_Koeffizient_2 0 "gueltiger_Wert" 1 "Ersatz_Init_oder_Fehlerwert" ;
VAL_ 1366 FWS_Koeffizient_2 254 "Init" 255 "Fehler" ;
VAL_ 1366 MO_Ziel_SoC_Fremdladung 254 "Init" ;
VAL_ 283 MO_Fahrbereitschaft 0 "Fahrzykl_inaktiv__kein_Antrieb" 1 "Fahrzykl_aktiv__kein_Antrieb" 2 "Fahrzykl_aktiv__Antrieb_moeglich" ;
VAL_ 283 MO_Freilauf_Info 0 "Freilauf_freigegeben" 1 "Uebergang_in_Freilauf_unzulaessig" 2 "Freilauf_nicht_freigegeben_Abbruch" 3 "Freilauf_Anforderung" ;
VAL_ 283 MO_Krit_Heckobjekt 0 "Init_kein_relevantes_Objekt" 1 "Entfernung_grosser_Abstand" 2 "Annaeherung_grosser_Abstand" 3 "Entfernung_geringer_Abstand" 4 "Annaeherung_geringer_Abstand" 7 "Fehler" ;
VAL_ 283 MO_NGS_Gangpos 0 "nicht_bedient" 1 "1_3_oder_5" 2 "2_4_6_oder_R" 3 "R" 4 "Neutralposition" 5 "Zwischenposition" 6 "Sensor_temp_nicht_verfuegbar" 7 "Fehler" ;
VAL_ 283 MO_Freilauf_Status 0 "Freilauf_inaktiv_aber_moeglich" 1 "Freilauf_aktiv" 2 "Freilauf_nicht_moegl_1Verhinderer" 3 "Freilauf_nicht_moegl_gr_1Verhinderer" 7 "Fehler" ;
VAL_ 283 MO_EBoost_verf_praed 0 "Init_oder_nicht_verfuegbar" 1 "EBoost_kurzzeit_verfuegbar" 2 "EBoost_langzeit_verfuegbar" ;
VAL_ 283 MO_Heckspoiler_Anf 0 "nicht_angefordert" 1 "angefordert" ;
VAL_ 283 MO_eLaunch_verf 0 "Init" 1 "nicht_verfuegbar" 2 "verfuegbar" ;
VAL_ 283 MO_Positionierung_aktiv 0 "keine_Positionierung_aktiv" 1 "Positionierung_aktiv" ;
VAL_ 283 MO_Parken_WFS_Status 0 "Limitierung_Inaktiv" 1 "Limitierung_Aktiv" 2 "Abbruch" ;
VAL_ 2527679581 MO_TME_KL_Anf 126 "Init" 127 "Fehler" ;
VAL_ 2527679581 MO_Anf_KJS_1 126 "Init" 127 "Fehler" ;
VAL_ 2527679581 MO_Hysterese_Reakt_Charge 510 "Init" 511 "Fehler" ;
VAL_ 2527679581 MO_Hysterese_Reakt_EV 510 "Init" 511 "Fehler" ;
VAL_ 2527679581 MO_Abwurfschwelle_Charge 1022 "Init" 1023 "Fehler" ;
VAL_ 2527679581 MO_Abwurfschwelle_EV 1022 "Init" 1023 "Fehler" ;
VAL_ 377 MO_Soll_NutzbarerSOC 254 "Init" 255 "Fehler" ;
